VERSION ""

NS_ :

BS_:

BU_: TBox

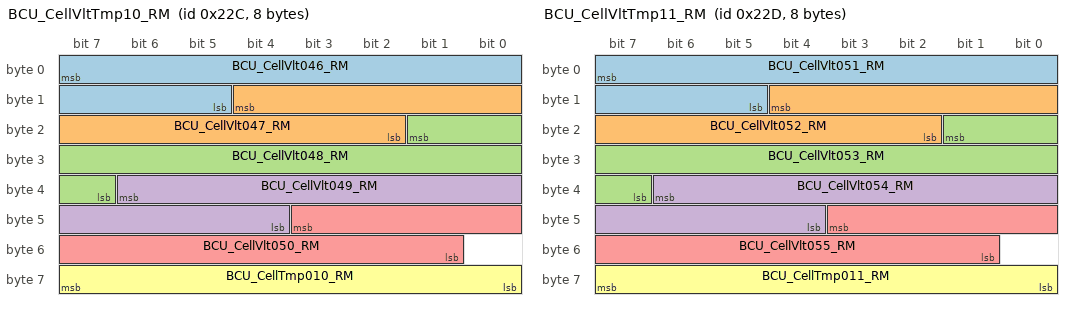
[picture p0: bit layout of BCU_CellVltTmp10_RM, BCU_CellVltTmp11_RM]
BO_ 556 BCU_CellVltTmp10_RM: 8 CGW
 SG_ BCU_CellVlt046_RM : 7|11@0+ (0.01,0) [0|18] "V" TBox
 SG_ BCU_CellVlt047_RM : 12|11@0+ (0.01,0) [0|18] "V" TBox
 SG_ BCU_CellVlt048_RM : 17|11@0+ (0.01,0) [0|18] "V" TBox
 SG_ BCU_CellVlt049_RM : 38|11@0+ (0.01,0) [0|18] "V" TBox
 SG_ BCU_CellVlt050_RM : 43|11@0+ (0.01,0) [0|18] "V" TBox
 SG_ BCU_CellTmp010_RM : 63|8@0+ (1,-40) [-40|120] "℃" TBox

BO_ 557 BCU_CellVltTmp11_RM: 8 CGW
 SG_ BCU_CellVlt051_RM : 7|11@0+ (0.01,0) [0|18] "V" TBox
 SG_ BCU_CellVlt052_RM : 12|11@0+ (0.01,0) [0|18] "V" TBox
 SG_ BCU_CellVlt053_RM : 17|11@0+ (0.01,0) [0|18] "V" TBox
 SG_ BCU_CellVlt054_RM : 38|11@0+ (0.01,0) [0|18] "V" TBox
 SG_ BCU_CellVlt055_RM : 43|11@0+ (0.01,0) [0|18] "V" TBox
 SG_ BCU_CellTmp011_RM : 63|8@0+ (1,-40) [-40|120] "℃" TBox

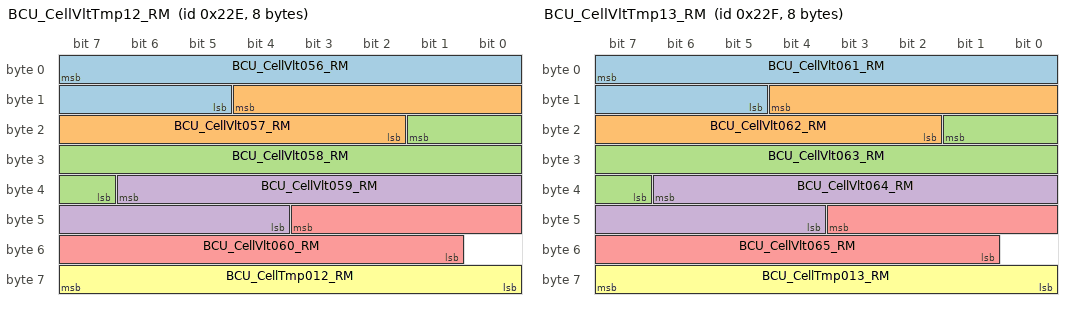
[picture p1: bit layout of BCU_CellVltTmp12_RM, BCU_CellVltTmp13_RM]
BO_ 558 BCU_CellVltTmp12_RM: 8 CGW
 SG_ BCU_CellVlt056_RM : 7|11@0+ (0.01,0) [0|18] "V" TBox
 SG_ BCU_CellVlt057_RM : 12|11@0+ (0.01,0) [0|18] "V" TBox
 SG_ BCU_CellVlt058_RM : 17|11@0+ (0.01,0) [0|18] "V" TBox
 SG_ BCU_CellVlt059_RM : 38|11@0+ (0.01,0) [0|18] "V" TBox
 SG_ BCU_CellVlt060_RM : 43|11@0+ (0.01,0) [0|18] "V" TBox
 SG_ BCU_CellTmp012_RM : 63|8@0+ (1,-40) [-40|120] "℃" TBox

BO_ 559 BCU_CellVltTmp13_RM: 8 CGW
 SG_ BCU_CellVlt061_RM : 7|11@0+ (0.01,0) [0|18] "V" TBox
 SG_ BCU_CellVlt062_RM : 12|11@0+ (0.01,0) [0|18] "V" TBox
 SG_ BCU_CellVlt063_RM : 17|11@0+ (0.01,0) [0|18] "V" TBox
 SG_ BCU_CellVlt064_RM : 38|11@0+ (0.01,0) [0|18] "V" TBox
 SG_ BCU_CellVlt065_RM : 43|11@0+ (0.01,0) [0|18] "V" TBox
 SG_ BCU_CellTmp013_RM : 63|8@0+ (1,-40) [-40|120] "℃" TBox

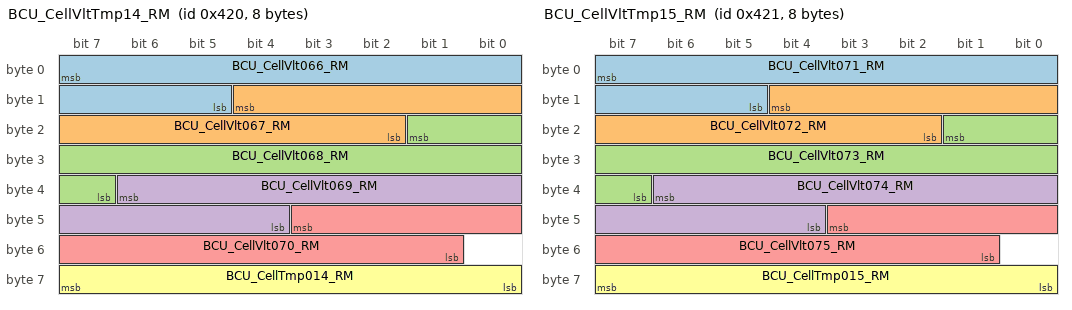
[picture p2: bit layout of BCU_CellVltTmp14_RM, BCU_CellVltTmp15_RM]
BO_ 1056 BCU_CellVltTmp14_RM: 8 CGW
 SG_ BCU_CellVlt066_RM : 7|11@0+ (0.01,0) [0|18] "V" TBox
 SG_ BCU_CellVlt067_RM : 12|11@0+ (0.01,0) [0|18] "V" TBox
 SG_ BCU_CellVlt068_RM : 17|11@0+ (0.01,0) [0|18] "V" TBox
 SG_ BCU_CellVlt069_RM : 38|11@0+ (0.01,0) [0|18] "V" TBox
 SG_ BCU_CellVlt070_RM : 43|11@0+ (0.01,0) [0|18] "V" TBox
 SG_ BCU_CellTmp014_RM : 63|8@0+ (1,-40) [-40|120] "℃" TBox

BO_ 1057 BCU_CellVltTmp15_RM: 8 CGW
 SG_ BCU_CellVlt071_RM : 7|11@0+ (0.01,0) [0|18] "V" TBox
 SG_ BCU_CellVlt072_RM : 12|11@0+ (0.01,0) [0|18] "V" TBox
 SG_ BCU_CellVlt073_RM : 17|11@0+ (0.01,0) [0|18] "V" TBox
 SG_ BCU_CellVlt074_RM : 38|11@0+ (0.01,0) [0|18] "V" TBox
 SG_ BCU_CellVlt075_RM : 43|11@0+ (0.01,0) [0|18] "V" TBox
 SG_ BCU_CellTmp015_RM : 63|8@0+ (1,-40) [-40|120] "℃" TBox

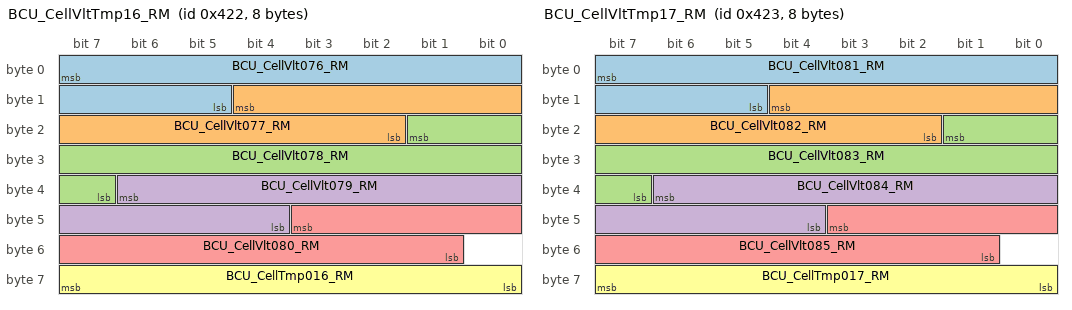
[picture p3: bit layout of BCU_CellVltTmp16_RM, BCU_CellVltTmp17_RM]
BO_ 1058 BCU_CellVltTmp16_RM: 8 CGW
 SG_ BCU_CellVlt076_RM : 7|11@0+ (0.01,0) [0|18] "V" TBox
 SG_ BCU_CellVlt077_RM : 12|11@0+ (0.01,0) [0|18] "V" TBox
 SG_ BCU_CellVlt078_RM : 17|11@0+ (0.01,0) [0|18] "V" TBox
 SG_ BCU_CellVlt079_RM : 38|11@0+ (0.01,0) [0|18] "V" TBox
 SG_ BCU_CellVlt080_RM : 43|11@0+ (0.01,0) [0|18] "V" TBox
 SG_ BCU_CellTmp016_RM : 63|8@0+ (1,-40) [-40|120] "℃" TBox

BO_ 1059 BCU_CellVltTmp17_RM: 8 CGW
 SG_ BCU_CellVlt081_RM : 7|11@0+ (0.01,0) [0|18] "V" TBox
 SG_ BCU_CellVlt082_RM : 12|11@0+ (0.01,0) [0|18] "V" TBox
 SG_ BCU_CellVlt083_RM : 17|11@0+ (0.01,0) [0|18] "V" TBox
 SG_ BCU_CellVlt084_RM : 38|11@0+ (0.01,0) [0|18] "V" TBox
 SG_ BCU_CellVlt085_RM : 43|11@0+ (0.01,0) [0|18] "V" TBox
 SG_ BCU_CellTmp017_RM : 63|8@0+ (1,-40) [-40|120] "℃" TBox

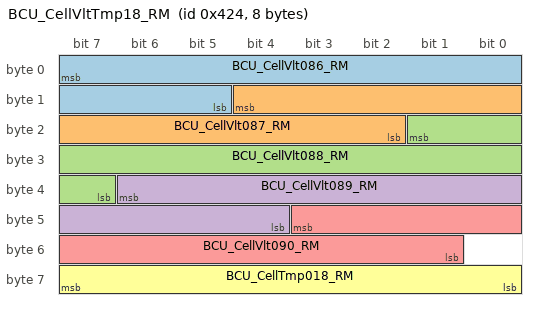
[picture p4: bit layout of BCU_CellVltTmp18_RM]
BO_ 1060 BCU_CellVltTmp18_RM: 8 CGW
 SG_ BCU_CellVlt086_RM : 7|11@0+ (0.01,0) [0|18] "V" TBox
 SG_ BCU_CellVlt087_RM : 12|11@0+ (0.01,0) [0|18] "V" TBox
 SG_ BCU_CellVlt088_RM : 17|11@0+ (0.01,0) [0|18] "V" TBox
 SG_ BCU_CellVlt089_RM : 38|11@0+ (0.01,0) [0|18] "V" TBox
 SG_ BCU_CellVlt090_RM : 43|11@0+ (0.01,0) [0|18] "V" TBox
 SG_ BCU_CellTmp018_RM : 63|8@0+ (1,-40) [-40|120] "℃" TBox

CM_ SG_ 556 BCU_CellVlt046_RM "Cell voltage 046
单体电压046";
CM_ SG_ 556 BCU_CellVlt047_RM "Cell voltage 047
单体电压047";
CM_ SG_ 556 BCU_CellVlt048_RM "Cell voltage 048
单体电压048";
CM_ SG_ 556 BCU_CellVlt049_RM "Cell voltage 049
单体电压049";
CM_ SG_ 556 BCU_CellVlt050_RM "Cell voltage 050
单体电压050";
CM_ SG_ 556 BCU_CellTmp010_RM "Cell temperature 010
单体温度010";
CM_ SG_ 557 BCU_CellVlt051_RM "Cell voltage 051
单体电压051";
CM_ SG_ 557 BCU_CellVlt052_RM "Cell voltage 052
单体电压052";
CM_ SG_ 557 BCU_CellVlt053_RM "Cell voltage 053
单体电压053";
CM_ SG_ 557 BCU_CellVlt054_RM "Cell voltage 054
单体电压054";
CM_ SG_ 557 BCU_CellVlt055_RM "Cell voltage 055
单体电压055";
CM_ SG_ 557 BCU_CellTmp011_RM "Cell temperature 011
单体温度011";
CM_ SG_ 558 BCU_CellVlt056_RM "Cell voltage 056
单体电压056";
CM_ SG_ 558 BCU_CellVlt057_RM "Cell voltage 057
单体电压057";
CM_ SG_ 558 BCU_CellVlt058_RM "Cell voltage 058
单体电压058";
CM_ SG_ 558 BCU_CellVlt059_RM "Cell voltage 059
单体电压059";
CM_ SG_ 558 BCU_CellVlt060_RM "Cell voltage 060
单体电压060";
CM_ SG_ 558 BCU_CellTmp012_RM "Cell temperature 012
单体温度012";
CM_ SG_ 559 BCU_CellVlt061_RM "Cell voltage 061
单体电压061";
CM_ SG_ 559 BCU_CellVlt062_RM "Cell voltage 062
单体电压062";
CM_ SG_ 559 BCU_CellVlt063_RM "Cell voltage 063
单体电压063";
CM_ SG_ 559 BCU_CellVlt064_RM "Cell voltage 064
单体电压064";
CM_ SG_ 559 BCU_CellVlt065_RM "Cell voltage 065
单体电压065";
CM_ SG_ 559 BCU_CellTmp013_RM "Cell temperature 013
单体温度013";
CM_ SG_ 1056 BCU_CellVlt066_RM "Cell voltage 066
单体电压066";
CM_ SG_ 1056 BCU_CellVlt067_RM "Cell voltage 067
单体电压067";
CM_ SG_ 1056 BCU_CellVlt068_RM "Cell voltage 068
单体电压068";
CM_ SG_ 1056 BCU_CellVlt069_RM "Cell voltage 069
单体电压069";
CM_ SG_ 1056 BCU_CellVlt070_RM "Cell voltage 070
单体电压070";
CM_ SG_ 1056 BCU_CellTmp014_RM "Cell temperature 014
单体温度014";
CM_ SG_ 1057 BCU_CellVlt071_RM "Cell voltage 071
单体电压071";
CM_ SG_ 1057 BCU_CellVlt072_RM "Cell voltage 072
单体电压072";
CM_ SG_ 1057 BCU_CellVlt073_RM "Cell voltage 073
单体电压073";
CM_ SG_ 1057 BCU_CellVlt074_RM "Cell voltage 074
单体电压074";
CM_ SG_ 1057 BCU_CellVlt075_RM "Cell voltage 075
单体电压075";
CM_ SG_ 1057 BCU_CellTmp015_RM "Cell temperature 015
单体温度015";
CM_ SG_ 1058 BCU_CellVlt076_RM "Cell voltage 076
单体电压076";
CM_ SG_ 1058 BCU_CellVlt077_RM "Cell voltage 077
单体电压077";
CM_ SG_ 1058 BCU_CellVlt078_RM "Cell voltage 078
单体电压078";
CM_ SG_ 1058 BCU_CellVlt079_RM "Cell voltage 079
单体电压079";
CM_ SG_ 1058 BCU_CellVlt080_RM "Cell voltage 080
单体电压080";
CM_ SG_ 1058 BCU_CellTmp016_RM "Cell temperature 016
单体温度016";
CM_ SG_ 1059 BCU_CellVlt081_RM "Cell voltage 081
单体电压081";
CM_ SG_ 1059 BCU_CellVlt082_RM "Cell voltage 082
单体电压082";
CM_ SG_ 1059 BCU_CellVlt083_RM "Cell voltage 083
单体电压083";
CM_ SG_ 1059 BCU_CellVlt084_RM "Cell voltage 084
单体电压084";
CM_ SG_ 1059 BCU_CellVlt085_RM "Cell voltage 085
单体电压085";
CM_ SG_ 1059 BCU_CellTmp017_RM "Cell temperature 017
单体温度017";
CM_ SG_ 1060 BCU_CellVlt086_RM "Cell voltage 086
单体电压086";
CM_ SG_ 1060 BCU_CellVlt087_RM "Cell voltage 087
单体电压087";
CM_ SG_ 1060 BCU_CellVlt088_RM "Cell voltage 088
单体电压088";
CM_ SG_ 1060 BCU_CellVlt089_RM "Cell voltage 089
单体电压089";
CM_ SG_ 1060 BCU_CellVlt090_RM "Cell voltage 090
单体电压090";
CM_ SG_ 1060 BCU_CellTmp018_RM "Cell temperature 018
单体温度018";

BA_DEF_ BO_  "NmMessage" ENUM "No","Yes";
BA_DEF_ BO_  "GenMsgSendType" ENUM  "Cycle","CA","CE","Event","NotUsed","NotUsed","NotUsed","IfActive","NoMsgSendType","NotUsed";
BA_DEF_ BO_  "GenMsgCycleTime" INT 0 0;
BA_DEF_ SG_  "GenSigSendType" ENUM  "Cycle","OnChange","OnWrite","IfActive","OnChangeWithRepetition","OnWriteWithRepetition","IfActiveWithRepetition";
BA_DEF_ SG_  "GenSigStartValue" INT 0 0;
BA_DEF_ BO_  "GenMsgCycleTimeFast" INT 0 0;
BA_DEF_ BO_  "GenMsgNrOfRepetition" INT 0 0;
BA_DEF_ BO_  "GenMsgDelayTime" INT 0 0;
BA_DEF_ BO_  "VFrameFormat" ENUM  "StandardCAN","ExtendedCAN","reserved","reserved","reserved","reserved","reserved","reserved","reserved","reserved","reserved","reserved","reserved","reserved","StandardCAN_FD","ExtendedCAN_FD";
BA_DEF_ BO_  "GenMsgCycleTimeActive" INT 0 500;
BA_DEF_ BO_  "GenMsgStartDelayTime" INT 0 500;

BA_DEF_DEF_  "NmMessage" "No";
BA_DEF_DEF_  "GenMsgSendType" "Cycle";
BA_DEF_DEF_  "GenMsgCycleTime" 0;
BA_DEF_DEF_  "GenSigSendType" "Cycle";
BA_DEF_DEF_  "GenSigStartValue" 0;
BA_DEF_DEF_  "GenMsgCycleTimeFast" 0;
BA_DEF_DEF_  "GenMsgNrOfRepetition" 0;
BA_DEF_DEF_  "GenMsgDelayTime" 0;
BA_DEF_DEF_  "VFrameFormat" "StandardCAN";
BA_DEF_DEF_  "GenMsgCycleTimeActive" 100;
BA_DEF_DEF_  "GenMsgStartDelayTime" 200;
BA_ "GenMsgCycleTime" BO_ 556 1000;
BA_ "GenSigStartValue" SG_ 556 BCU_CellTmp010_RM 40;
BA_ "GenMsgCycleTime" BO_ 557 1000;
BA_ "GenSigStartValue" SG_ 557 BCU_CellTmp011_RM 40;
BA_ "GenMsgCycleTime" BO_ 558 1000;
BA_ "GenSigStartValue" SG_ 558 BCU_CellTmp012_RM 40;
BA_ "GenMsgCycleTime" BO_ 559 1000;
BA_ "GenSigStartValue" SG_ 559 BCU_CellTmp013_RM 40;
BA_ "GenMsgCycleTime" BO_ 1056 1000;
BA_ "GenSigStartValue" SG_ 1056 BCU_CellTmp014_RM 40;
BA_ "GenMsgCycleTime" BO_ 1057 1000;
BA_ "GenSigStartValue" SG_ 1057 BCU_CellTmp015_RM 40;
BA_ "GenMsgCycleTime" BO_ 1058 1000;
BA_ "GenSigStartValue" SG_ 1058 BCU_CellTmp016_RM 40;
BA_ "GenMsgCycleTime" BO_ 1059 1000;
BA_ "GenSigStartValue" SG_ 1059 BCU_CellTmp017_RM 40;
BA_ "GenMsgCycleTime" BO_ 1060 1000;
BA_ "GenSigStartValue" SG_ 1060 BCU_CellTmp018_RM 40;
VAL_ 556 BCU_CellVlt046_RM 2047 "Invalid" 2046 "Invalid" 2045 "Invalid" 2044 "Invalid" 2043 "Invalid" 2042 "Invalid" 2041 "Invalid" 2040 "Invalid" 2039 "Invalid" 2038 "Invalid" 2037 "Invalid" 2036 "Invalid" 2035 "Invalid" 2034 "Invalid" 2033 "Invalid" 2032 "Invalid" 2031 "Invalid" 2030 "Invalid" 2029 "Invalid" 2028 "Invalid" 2027 "Invalid" 2026 "Invalid" 2025 "Invalid" 2024 "Invalid" 2023 "Invalid" 2022 "Invalid" 2021 "Invalid" 2020 "Invalid" 2019 "Invalid" 2018 "Invalid" 2017 "Invalid" 2016 "Invalid" 2015 "Invalid" 2014 "Invalid" 2013 "Invalid" 2012 "Invalid" 2011 "Invalid" 2010 "Invalid" 2009 "Invalid" 2008 "Invalid" 2007 "Invalid" 2006 "Invalid" 2005 "Invalid" 2004 "Invalid" 2003 "Invalid" 2002 "Invalid" 2001 "Invalid" 2000 "Invalid" 1999 "Invalid" 1998 "Invalid" 1997 "Invalid" 1996 "Invalid" 1995 "Invalid" 1994 "Invalid" 1993 "Invalid" 1992 "Invalid" 1991 "Invalid" 1990 "Invalid" 1989 "Invalid" 1988 "Invalid" 1987 "Invalid" 1986 "Invalid" 1985 "Invalid" 1984 "Invalid" 1983 "Invalid" 1982 "Invalid" 1981 "Invalid" 1980 "Invalid" 1979 "Invalid" 1978 "Invalid" 1977 "Invalid" 1976 "Invalid" 1975 "Invalid" 1974 "Invalid" 1973 "Invalid" 1972 "Invalid" 1971 "Invalid" 1970 "Invalid" 1969 "Invalid" 1968 "Invalid" 1967 "Invalid" 1966 "Invalid" 1965 "Invalid" 1964 "Invalid" 1963 "Invalid" 1962 "Invalid" 1961 "Invalid" 1960 "Invalid" 1959 "Invalid" 1958 "Invalid" 1957 "Invalid" 1956 "Invalid" 1955 "Invalid" 1954 "Invalid" 1953 "Invalid" 1952 "Invalid" 1951 "Invalid" 1950 "Invalid" 1949 "Invalid" 1948 "Invalid" 1947 "Invalid" 1946 "Invalid" 1945 "Invalid" 1944 "Invalid" 1943 "Invalid" 1942 "Invalid" 1941 "Invalid" 1940 "Invalid" 1939 "Invalid" 1938 "Invalid" 1937 "Invalid" 1936 "Invalid" 1935 "Invalid" 1934 "Invalid" 1933 "Invalid" 1932 "Invalid" 1931 "Invalid" 1930 "Invalid" 1929 "Invalid" 1928 "Invalid" 1927 "Invalid" 1926 "Invalid" 1925 "Invalid" 1924 "Invalid" 1923 "Invalid" 1922 "Invalid" 1921 "Invalid" 1920 "Invalid" 1919 "Invalid" 1918 "Invalid" 1917 "Invalid" 1916 "Invalid" 1915 "Invalid" 1914 "Invalid" 1913 "Invalid" 1912 "Invalid" 1911 "Invalid" 1910 "Invalid" 1909 "Invalid" 1908 "Invalid" 1907 "Invalid" 1906 "Invalid" 1905 "Invalid" 1904 "Invalid" 1903 "Invalid" 1902 "Invalid" 1901 "Invalid" 1900 "Invalid" 1899 "Invalid" 1898 "Invalid" 1897 "Invalid" 1896 "Invalid" 1895 "Invalid" 1894 "Invalid" 1893 "Invalid" 1892 "Invalid" 1891 "Invalid" 1890 "Invalid" 1889 "Invalid" 1888 "Invalid" 1887 "Invalid" 1886 "Invalid" 1885 "Invalid" 1884 "Invalid" 1883 "Invalid" 1882 "Invalid" 1881 "Invalid" 1880 "Invalid" 1879 "Invalid" 1878 "Invalid" 1877 "Invalid" 1876 "Invalid" 1875 "Invalid" 1874 "Invalid" 1873 "Invalid" 1872 "Invalid" 1871 "Invalid" 1870 "Invalid" 1869 "Invalid" 1868 "Invalid" 1867 "Invalid" 1866 "Invalid" 1865 "Invalid" 1864 "Invalid" 1863 "Invalid" 1862 "Invalid" 1861 "Invalid" 1860 "Invalid" 1859 "Invalid" 1858 "Invalid" 1857 "Invalid" 1856 "Invalid" 1855 "Invalid" 1854 "Invalid" 1853 "Invalid" 1852 "Invalid" 1851 "Invalid" 1850 "Invalid" 1849 "Invalid" 1848 "Invalid" 1847 "Invalid" 1846 "Invalid" 1845 "Invalid" 1844 "Invalid" 1843 "Invalid" 1842 "Invalid" 1841 "Invalid" 1840 "Invalid" 1839 "Invalid" 1838 "Invalid" 1837 "Invalid" 1836 "Invalid" 1835 "Invalid" 1834 "Invalid" 1833 "Invalid" 1832 "Invalid" 1831 "Invalid" 1830 "Invalid" 1829 "Invalid" 1828 "Invalid" 1827 "Invalid" 1826 "Invalid" 1825 "Invalid" 1824 "Invalid" 1823 "Invalid" 1822 "Invalid" 1821 "Invalid" 1820 "Invalid" 1819 "Invalid" 1818 "Invalid" 1817 "Invalid" 1816 "Invalid" 1815 "Invalid" 1814 "Invalid" 1813 "Invalid" 1812 "Invalid" 1811 "Invalid" 1810 "Invalid" 1809 "Invalid" 1808 "Invalid" 1807 "Invalid" 1806 "Invalid" 1805 "Invalid" 1804 "Invalid" 1803 "Invalid" 1802 "Invalid" 1801 "Invalid" ;
VAL_ 556 BCU_CellVlt047_RM 2047 "Invalid" 2046 "Invalid" 2045 "Invalid" 2044 "Invalid" 2043 "Invalid" 2042 "Invalid" 2041 "Invalid" 2040 "Invalid" 2039 "Invalid" 2038 "Invalid" 2037 "Invalid" 2036 "Invalid" 2035 "Invalid" 2034 "Invalid" 2033 "Invalid" 2032 "Invalid" 2031 "Invalid" 2030 "Invalid" 2029 "Invalid" 2028 "Invalid" 2027 "Invalid" 2026 "Invalid" 2025 "Invalid" 2024 "Invalid" 2023 "Invalid" 2022 "Invalid" 2021 "Invalid" 2020 "Invalid" 2019 "Invalid" 2018 "Invalid" 2017 "Invalid" 2016 "Invalid" 2015 "Invalid" 2014 "Invalid" 2013 "Invalid" 2012 "Invalid" 2011 "Invalid" 2010 "Invalid" 2009 "Invalid" 2008 "Invalid" 2007 "Invalid" 2006 "Invalid" 2005 "Invalid" 2004 "Invalid" 2003 "Invalid" 2002 "Invalid" 2001 "Invalid" 2000 "Invalid" 1999 "Invalid" 1998 "Invalid" 1997 "Invalid" 1996 "Invalid" 1995 "Invalid" 1994 "Invalid" 1993 "Invalid" 1992 "Invalid" 1991 "Invalid" 1990 "Invalid" 1989 "Invalid" 1988 "Invalid" 1987 "Invalid" 1986 "Invalid" 1985 "Invalid" 1984 "Invalid" 1983 "Invalid" 1982 "Invalid" 1981 "Invalid" 1980 "Invalid" 1979 "Invalid" 1978 "Invalid" 1977 "Invalid" 1976 "Invalid" 1975 "Invalid" 1974 "Invalid" 1973 "Invalid" 1972 "Invalid" 1971 "Invalid" 1970 "Invalid" 1969 "Invalid" 1968 "Invalid" 1967 "Invalid" 1966 "Invalid" 1965 "Invalid" 1964 "Invalid" 1963 "Invalid" 1962 "Invalid" 1961 "Invalid" 1960 "Invalid" 1959 "Invalid" 1958 "Invalid" 1957 "Invalid" 1956 "Invalid" 1955 "Invalid" 1954 "Invalid" 1953 "Invalid" 1952 "Invalid" 1951 "Invalid" 1950 "Invalid" 1949 "Invalid" 1948 "Invalid" 1947 "Invalid" 1946 "Invalid" 1945 "Invalid" 1944 "Invalid" 1943 "Invalid" 1942 "Invalid" 1941 "Invalid" 1940 "Invalid" 1939 "Invalid" 1938 "Invalid" 1937 "Invalid" 1936 "Invalid" 1935 "Invalid" 1934 "Invalid" 1933 "Invalid" 1932 "Invalid" 1931 "Invalid" 1930 "Invalid" 1929 "Invalid" 1928 "Invalid" 1927 "Invalid" 1926 "Invalid" 1925 "Invalid" 1924 "Invalid" 1923 "Invalid" 1922 "Invalid" 1921 "Invalid" 1920 "Invalid" 1919 "Invalid" 1918 "Invalid" 1917 "Invalid" 1916 "Invalid" 1915 "Invalid" 1914 "Invalid" 1913 "Invalid" 1912 "Invalid" 1911 "Invalid" 1910 "Invalid" 1909 "Invalid" 1908 "Invalid" 1907 "Invalid" 1906 "Invalid" 1905 "Invalid" 1904 "Invalid" 1903 "Invalid" 1902 "Invalid" 1901 "Invalid" 1900 "Invalid" 1899 "Invalid" 1898 "Invalid" 1897 "Invalid" 1896 "Invalid" 1895 "Invalid" 1894 "Invalid" 1893 "Invalid" 1892 "Invalid" 1891 "Invalid" 1890 "Invalid" 1889 "Invalid" 1888 "Invalid" 1887 "Invalid" 1886 "Invalid" 1885 "Invalid" 1884 "Invalid" 1883 "Invalid" 1882 "Invalid" 1881 "Invalid" 1880 "Invalid" 1879 "Invalid" 1878 "Invalid" 1877 "Invalid" 1876 "Invalid" 1875 "Invalid" 1874 "Invalid" 1873 "Invalid" 1872 "Invalid" 1871 "Invalid" 1870 "Invalid" 1869 "Invalid" 1868 "Invalid" 1867 "Invalid" 1866 "Invalid" 1865 "Invalid" 1864 "Invalid" 1863 "Invalid" 1862 "Invalid" 1861 "Invalid" 1860 "Invalid" 1859 "Invalid" 1858 "Invalid" 1857 "Invalid" 1856 "Invalid" 1855 "Invalid" 1854 "Invalid" 1853 "Invalid" 1852 "Invalid" 1851 "Invalid" 1850 "Invalid" 1849 "Invalid" 1848 "Invalid" 1847 "Invalid" 1846 "Invalid" 1845 "Invalid" 1844 "Invalid" 1843 "Invalid" 1842 "Invalid" 1841 "Invalid" 1840 "Invalid" 1839 "Invalid" 1838 "Invalid" 1837 "Invalid" 1836 "Invalid" 1835 "Invalid" 1834 "Invalid" 1833 "Invalid" 1832 "Invalid" 1831 "Invalid" 1830 "Invalid" 1829 "Invalid" 1828 "Invalid" 1827 "Invalid" 1826 "Invalid" 1825 "Invalid" 1824 "Invalid" 1823 "Invalid" 1822 "Invalid" 1821 "Invalid" 1820 "Invalid" 1819 "Invalid" 1818 "Invalid" 1817 "Invalid" 1816 "Invalid" 1815 "Invalid" 1814 "Invalid" 1813 "Invalid" 1812 "Invalid" 1811 "Invalid" 1810 "Invalid" 1809 "Invalid" 1808 "Invalid" 1807 "Invalid" 1806 "Invalid" 1805 "Invalid" 1804 "Invalid" 1803 "Invalid" 1802 "Invalid" 1801 "Invalid" ;
VAL_ 556 BCU_CellVlt048_RM 2047 "Invalid" 2046 "Invalid" 2045 "Invalid" 2044 "Invalid" 2043 "Invalid" 2042 "Invalid" 2041 "Invalid" 2040 "Invalid" 2039 "Invalid" 2038 "Invalid" 2037 "Invalid" 2036 "Invalid" 2035 "Invalid" 2034 "Invalid" 2033 "Invalid" 2032 "Invalid" 2031 "Invalid" 2030 "Invalid" 2029 "Invalid" 2028 "Invalid" 2027 "Invalid" 2026 "Invalid" 2025 "Invalid" 2024 "Invalid" 2023 "Invalid" 2022 "Invalid" 2021 "Invalid" 2020 "Invalid" 2019 "Invalid" 2018 "Invalid" 2017 "Invalid" 2016 "Invalid" 2015 "Invalid" 2014 "Invalid" 2013 "Invalid" 2012 "Invalid" 2011 "Invalid" 2010 "Invalid" 2009 "Invalid" 2008 "Invalid" 2007 "Invalid" 2006 "Invalid" 2005 "Invalid" 2004 "Invalid" 2003 "Invalid" 2002 "Invalid" 2001 "Invalid" 2000 "Invalid" 1999 "Invalid" 1998 "Invalid" 1997 "Invalid" 1996 "Invalid" 1995 "Invalid" 1994 "Invalid" 1993 "Invalid" 1992 "Invalid" 1991 "Invalid" 1990 "Invalid" 1989 "Invalid" 1988 "Invalid" 1987 "Invalid" 1986 "Invalid" 1985 "Invalid" 1984 "Invalid" 1983 "Invalid" 1982 "Invalid" 1981 "Invalid" 1980 "Invalid" 1979 "Invalid" 1978 "Invalid" 1977 "Invalid" 1976 "Invalid" 1975 "Invalid" 1974 "Invalid" 1973 "Invalid" 1972 "Invalid" 1971 "Invalid" 1970 "Invalid" 1969 "Invalid" 1968 "Invalid" 1967 "Invalid" 1966 "Invalid" 1965 "Invalid" 1964 "Invalid" 1963 "Invalid" 1962 "Invalid" 1961 "Invalid" 1960 "Invalid" 1959 "Invalid" 1958 "Invalid" 1957 "Invalid" 1956 "Invalid" 1955 "Invalid" 1954 "Invalid" 1953 "Invalid" 1952 "Invalid" 1951 "Invalid" 1950 "Invalid" 1949 "Invalid" 1948 "Invalid" 1947 "Invalid" 1946 "Invalid" 1945 "Invalid" 1944 "Invalid" 1943 "Invalid" 1942 "Invalid" 1941 "Invalid" 1940 "Invalid" 1939 "Invalid" 1938 "Invalid" 1937 "Invalid" 1936 "Invalid" 1935 "Invalid" 1934 "Invalid" 1933 "Invalid" 1932 "Invalid" 1931 "Invalid" 1930 "Invalid" 1929 "Invalid" 1928 "Invalid" 1927 "Invalid" 1926 "Invalid" 1925 "Invalid" 1924 "Invalid" 1923 "Invalid" 1922 "Invalid" 1921 "Invalid" 1920 "Invalid" 1919 "Invalid" 1918 "Invalid" 1917 "Invalid" 1916 "Invalid" 1915 "Invalid" 1914 "Invalid" 1913 "Invalid" 1912 "Invalid" 1911 "Invalid" 1910 "Invalid" 1909 "Invalid" 1908 "Invalid" 1907 "Invalid" 1906 "Invalid" 1905 "Invalid" 1904 "Invalid" 1903 "Invalid" 1902 "Invalid" 1901 "Invalid" 1900 "Invalid" 1899 "Invalid" 1898 "Invalid" 1897 "Invalid" 1896 "Invalid" 1895 "Invalid" 1894 "Invalid" 1893 "Invalid" 1892 "Invalid" 1891 "Invalid" 1890 "Invalid" 1889 "Invalid" 1888 "Invalid" 1887 "Invalid" 1886 "Invalid" 1885 "Invalid" 1884 "Invalid" 1883 "Invalid" 1882 "Invalid" 1881 "Invalid" 1880 "Invalid" 1879 "Invalid" 1878 "Invalid" 1877 "Invalid" 1876 "Invalid" 1875 "Invalid" 1874 "Invalid" 1873 "Invalid" 1872 "Invalid" 1871 "Invalid" 1870 "Invalid" 1869 "Invalid" 1868 "Invalid" 1867 "Invalid" 1866 "Invalid" 1865 "Invalid" 1864 "Invalid" 1863 "Invalid" 1862 "Invalid" 1861 "Invalid" 1860 "Invalid" 1859 "Invalid" 1858 "Invalid" 1857 "Invalid" 1856 "Invalid" 1855 "Invalid" 1854 "Invalid" 1853 "Invalid" 1852 "Invalid" 1851 "Invalid" 1850 "Invalid" 1849 "Invalid" 1848 "Invalid" 1847 "Invalid" 1846 "Invalid" 1845 "Invalid" 1844 "Invalid" 1843 "Invalid" 1842 "Invalid" 1841 "Invalid" 1840 "Invalid" 1839 "Invalid" 1838 "Invalid" 1837 "Invalid" 1836 "Invalid" 1835 "Invalid" 1834 "Invalid" 1833 "Invalid" 1832 "Invalid" 1831 "Invalid" 1830 "Invalid" 1829 "Invalid" 1828 "Invalid" 1827 "Invalid" 1826 "Invalid" 1825 "Invalid" 1824 "Invalid" 1823 "Invalid" 1822 "Invalid" 1821 "Invalid" 1820 "Invalid" 1819 "Invalid" 1818 "Invalid" 1817 "Invalid" 1816 "Invalid" 1815 "Invalid" 1814 "Invalid" 1813 "Invalid" 1812 "Invalid" 1811 "Invalid" 1810 "Invalid" 1809 "Invalid" 1808 "Invalid" 1807 "Invalid" 1806 "Invalid" 1805 "Invalid" 1804 "Invalid" 1803 "Invalid" 1802 "Invalid" 1801 "Invalid" ;
VAL_ 556 BCU_CellVlt049_RM 2047 "Invalid" 2046 "Invalid" 2045 "Invalid" 2044 "Invalid" 2043 "Invalid" 2042 "Invalid" 2041 "Invalid" 2040 "Invalid" 2039 "Invalid" 2038 "Invalid" 2037 "Invalid" 2036 "Invalid" 2035 "Invalid" 2034 "Invalid" 2033 "Invalid" 2032 "Invalid" 2031 "Invalid" 2030 "Invalid" 2029 "Invalid" 2028 "Invalid" 2027 "Invalid" 2026 "Invalid" 2025 "Invalid" 2024 "Invalid" 2023 "Invalid" 2022 "Invalid" 2021 "Invalid" 2020 "Invalid" 2019 "Invalid" 2018 "Invalid" 2017 "Invalid" 2016 "Invalid" 2015 "Invalid" 2014 "Invalid" 2013 "Invalid" 2012 "Invalid" 2011 "Invalid" 2010 "Invalid" 2009 "Invalid" 2008 "Invalid" 2007 "Invalid" 2006 "Invalid" 2005 "Invalid" 2004 "Invalid" 2003 "Invalid" 2002 "Invalid" 2001 "Invalid" 2000 "Invalid" 1999 "Invalid" 1998 "Invalid" 1997 "Invalid" 1996 "Invalid" 1995 "Invalid" 1994 "Invalid" 1993 "Invalid" 1992 "Invalid" 1991 "Invalid" 1990 "Invalid" 1989 "Invalid" 1988 "Invalid" 1987 "Invalid" 1986 "Invalid" 1985 "Invalid" 1984 "Invalid" 1983 "Invalid" 1982 "Invalid" 1981 "Invalid" 1980 "Invalid" 1979 "Invalid" 1978 "Invalid" 1977 "Invalid" 1976 "Invalid" 1975 "Invalid" 1974 "Invalid" 1973 "Invalid" 1972 "Invalid" 1971 "Invalid" 1970 "Invalid" 1969 "Invalid" 1968 "Invalid" 1967 "Invalid" 1966 "Invalid" 1965 "Invalid" 1964 "Invalid" 1963 "Invalid" 1962 "Invalid" 1961 "Invalid" 1960 "Invalid" 1959 "Invalid" 1958 "Invalid" 1957 "Invalid" 1956 "Invalid" 1955 "Invalid" 1954 "Invalid" 1953 "Invalid" 1952 "Invalid" 1951 "Invalid" 1950 "Invalid" 1949 "Invalid" 1948 "Invalid" 1947 "Invalid" 1946 "Invalid" 1945 "Invalid" 1944 "Invalid" 1943 "Invalid" 1942 "Invalid" 1941 "Invalid" 1940 "Invalid" 1939 "Invalid" 1938 "Invalid" 1937 "Invalid" 1936 "Invalid" 1935 "Invalid" 1934 "Invalid" 1933 "Invalid" 1932 "Invalid" 1931 "Invalid" 1930 "Invalid" 1929 "Invalid" 1928 "Invalid" 1927 "Invalid" 1926 "Invalid" 1925 "Invalid" 1924 "Invalid" 1923 "Invalid" 1922 "Invalid" 1921 "Invalid" 1920 "Invalid" 1919 "Invalid" 1918 "Invalid" 1917 "Invalid" 1916 "Invalid" 1915 "Invalid" 1914 "Invalid" 1913 "Invalid" 1912 "Invalid" 1911 "Invalid" 1910 "Invalid" 1909 "Invalid" 1908 "Invalid" 1907 "Invalid" 1906 "Invalid" 1905 "Invalid" 1904 "Invalid" 1903 "Invalid" 1902 "Invalid" 1901 "Invalid" 1900 "Invalid" 1899 "Invalid" 1898 "Invalid" 1897 "Invalid" 1896 "Invalid" 1895 "Invalid" 1894 "Invalid" 1893 "Invalid" 1892 "Invalid" 1891 "Invalid" 1890 "Invalid" 1889 "Invalid" 1888 "Invalid" 1887 "Invalid" 1886 "Invalid" 1885 "Invalid" 1884 "Invalid" 1883 "Invalid" 1882 "Invalid" 1881 "Invalid" 1880 "Invalid" 1879 "Invalid" 1878 "Invalid" 1877 "Invalid" 1876 "Invalid" 1875 "Invalid" 1874 "Invalid" 1873 "Invalid" 1872 "Invalid" 1871 "Invalid" 1870 "Invalid" 1869 "Invalid" 1868 "Invalid" 1867 "Invalid" 1866 "Invalid" 1865 "Invalid" 1864 "Invalid" 1863 "Invalid" 1862 "Invalid" 1861 "Invalid" 1860 "Invalid" 1859 "Invalid" 1858 "Invalid" 1857 "Invalid" 1856 "Invalid" 1855 "Invalid" 1854 "Invalid" 1853 "Invalid" 1852 "Invalid" 1851 "Invalid" 1850 "Invalid" 1849 "Invalid" 1848 "Invalid" 1847 "Invalid" 1846 "Invalid" 1845 "Invalid" 1844 "Invalid" 1843 "Invalid" 1842 "Invalid" 1841 "Invalid" 1840 "Invalid" 1839 "Invalid" 1838 "Invalid" 1837 "Invalid" 1836 "Invalid" 1835 "Invalid" 1834 "Invalid" 1833 "Invalid" 1832 "Invalid" 1831 "Invalid" 1830 "Invalid" 1829 "Invalid" 1828 "Invalid" 1827 "Invalid" 1826 "Invalid" 1825 "Invalid" 1824 "Invalid" 1823 "Invalid" 1822 "Invalid" 1821 "Invalid" 1820 "Invalid" 1819 "Invalid" 1818 "Invalid" 1817 "Invalid" 1816 "Invalid" 1815 "Invalid" 1814 "Invalid" 1813 "Invalid" 1812 "Invalid" 1811 "Invalid" 1810 "Invalid" 1809 "Invalid" 1808 "Invalid" 1807 "Invalid" 1806 "Invalid" 1805 "Invalid" 1804 "Invalid" 1803 "Invalid" 1802 "Invalid" 1801 "Invalid" ;
VAL_ 556 BCU_CellVlt050_RM 2047 "Invalid" 2046 "Invalid" 2045 "Invalid" 2044 "Invalid" 2043 "Invalid" 2042 "Invalid" 2041 "Invalid" 2040 "Invalid" 2039 "Invalid" 2038 "Invalid" 2037 "Invalid" 2036 "Invalid" 2035 "Invalid" 2034 "Invalid" 2033 "Invalid" 2032 "Invalid" 2031 "Invalid" 2030 "Invalid" 2029 "Invalid" 2028 "Invalid" 2027 "Invalid" 2026 "Invalid" 2025 "Invalid" 2024 "Invalid" 2023 "Invalid" 2022 "Invalid" 2021 "Invalid" 2020 "Invalid" 2019 "Invalid" 2018 "Invalid" 2017 "Invalid" 2016 "Invalid" 2015 "Invalid" 2014 "Invalid" 2013 "Invalid" 2012 "Invalid" 2011 "Invalid" 2010 "Invalid" 2009 "Invalid" 2008 "Invalid" 2007 "Invalid" 2006 "Invalid" 2005 "Invalid" 2004 "Invalid" 2003 "Invalid" 2002 "Invalid" 2001 "Invalid" 2000 "Invalid" 1999 "Invalid" 1998 "Invalid" 1997 "Invalid" 1996 "Invalid" 1995 "Invalid" 1994 "Invalid" 1993 "Invalid" 1992 "Invalid" 1991 "Invalid" 1990 "Invalid" 1989 "Invalid" 1988 "Invalid" 1987 "Invalid" 1986 "Invalid" 1985 "Invalid" 1984 "Invalid" 1983 "Invalid" 1982 "Invalid" 1981 "Invalid" 1980 "Invalid" 1979 "Invalid" 1978 "Invalid" 1977 "Invalid" 1976 "Invalid" 1975 "Invalid" 1974 "Invalid" 1973 "Invalid" 1972 "Invalid" 1971 "Invalid" 1970 "Invalid" 1969 "Invalid" 1968 "Invalid" 1967 "Invalid" 1966 "Invalid" 1965 "Invalid" 1964 "Invalid" 1963 "Invalid" 1962 "Invalid" 1961 "Invalid" 1960 "Invalid" 1959 "Invalid" 1958 "Invalid" 1957 "Invalid" 1956 "Invalid" 1955 "Invalid" 1954 "Invalid" 1953 "Invalid" 1952 "Invalid" 1951 "Invalid" 1950 "Invalid" 1949 "Invalid" 1948 "Invalid" 1947 "Invalid" 1946 "Invalid" 1945 "Invalid" 1944 "Invalid" 1943 "Invalid" 1942 "Invalid" 1941 "Invalid" 1940 "Invalid" 1939 "Invalid" 1938 "Invalid" 1937 "Invalid" 1936 "Invalid" 1935 "Invalid" 1934 "Invalid" 1933 "Invalid" 1932 "Invalid" 1931 "Invalid" 1930 "Invalid" 1929 "Invalid" 1928 "Invalid" 1927 "Invalid" 1926 "Invalid" 1925 "Invalid" 1924 "Invalid" 1923 "Invalid" 1922 "Invalid" 1921 "Invalid" 1920 "Invalid" 1919 "Invalid" 1918 "Invalid" 1917 "Invalid" 1916 "Invalid" 1915 "Invalid" 1914 "Invalid" 1913 "Invalid" 1912 "Invalid" 1911 "Invalid" 1910 "Invalid" 1909 "Invalid" 1908 "Invalid" 1907 "Invalid" 1906 "Invalid" 1905 "Invalid" 1904 "Invalid" 1903 "Invalid" 1902 "Invalid" 1901 "Invalid" 1900 "Invalid" 1899 "Invalid" 1898 "Invalid" 1897 "Invalid" 1896 "Invalid" 1895 "Invalid" 1894 "Invalid" 1893 "Invalid" 1892 "Invalid" 1891 "Invalid" 1890 "Invalid" 1889 "Invalid" 1888 "Invalid" 1887 "Invalid" 1886 "Invalid" 1885 "Invalid" 1884 "Invalid" 1883 "Invalid" 1882 "Invalid" 1881 "Invalid" 1880 "Invalid" 1879 "Invalid" 1878 "Invalid" 1877 "Invalid" 1876 "Invalid" 1875 "Invalid" 1874 "Invalid" 1873 "Invalid" 1872 "Invalid" 1871 "Invalid" 1870 "Invalid" 1869 "Invalid" 1868 "Invalid" 1867 "Invalid" 1866 "Invalid" 1865 "Invalid" 1864 "Invalid" 1863 "Invalid" 1862 "Invalid" 1861 "Invalid" 1860 "Invalid" 1859 "Invalid" 1858 "Invalid" 1857 "Invalid" 1856 "Invalid" 1855 "Invalid" 1854 "Invalid" 1853 "Invalid" 1852 "Invalid" 1851 "Invalid" 1850 "Invalid" 1849 "Invalid" 1848 "Invalid" 1847 "Invalid" 1846 "Invalid" 1845 "Invalid" 1844 "Invalid" 1843 "Invalid" 1842 "Invalid" 1841 "Invalid" 1840 "Invalid" 1839 "Invalid" 1838 "Invalid" 1837 "Invalid" 1836 "Invalid" 1835 "Invalid" 1834 "Invalid" 1833 "Invalid" 1832 "Invalid" 1831 "Invalid" 1830 "Invalid" 1829 "Invalid" 1828 "Invalid" 1827 "Invalid" 1826 "Invalid" 1825 "Invalid" 1824 "Invalid" 1823 "Invalid" 1822 "Invalid" 1821 "Invalid" 1820 "Invalid" 1819 "Invalid" 1818 "Invalid" 1817 "Invalid" 1816 "Invalid" 1815 "Invalid" 1814 "Invalid" 1813 "Invalid" 1812 "Invalid" 1811 "Invalid" 1810 "Invalid" 1809 "Invalid" 1808 "Invalid" 1807 "Invalid" 1806 "Invalid" 1805 "Invalid" 1804 "Invalid" 1803 "Invalid" 1802 "Invalid" 1801 "Invalid" ;
VAL_ 556 BCU_CellTmp010_RM 255 "Invalid" 254 "Invalid" 253 "Invalid" 252 "Invalid" 251 "Invalid" 250 "Invalid" 249 "Invalid" 248 "Invalid" 247 "Invalid" 246 "Invalid" 245 "Invalid" 244 "Invalid" 243 "Invalid" 242 "Invalid" 241 "Invalid" 240 "Invalid" 239 "Invalid" 238 "Invalid" 237 "Invalid" 236 "Invalid" 235 "Invalid" 234 "Invalid" 233 "Invalid" 232 "Invalid" 231 "Invalid" 230 "Invalid" 229 "Invalid" 228 "Invalid" 227 "Invalid" 226 "Invalid" 225 "Invalid" 224 "Invalid" 223 "Invalid" 222 "Invalid" 221 "Invalid" 220 "Invalid" 219 "Invalid" 218 "Invalid" 217 "Invalid" 216 "Invalid" 215 "Invalid" 214 "Invalid" 213 "Invalid" 212 "Invalid" 211 "Invalid" 210 "Invalid" 209 "Invalid" 208 "Invalid" 207 "Invalid" 206 "Invalid" 205 "Invalid" 204 "Invalid" 203 "Invalid" 202 "Invalid" 201 "Invalid" 200 "Invalid" 199 "Invalid" 198 "Invalid" 197 "Invalid" 196 "Invalid" 195 "Invalid" 194 "Invalid" 193 "Invalid" 192 "Invalid" 191 "Invalid" 190 "Invalid" 189 "Invalid" 188 "Invalid" 187 "Invalid" 186 "Invalid" 185 "Invalid" 184 "Invalid" 183 "Invalid" 182 "Invalid" 181 "Invalid" 180 "Invalid" 179 "Invalid" 178 "Invalid" 177 "Invalid" 176 "Invalid" 175 "Invalid" 174 "Invalid" 173 "Invalid" 172 "Invalid" 171 "Invalid" 170 "Invalid" 169 "Invalid" 168 "Invalid" 167 "Invalid" 166 "Invalid" 165 "Invalid" 164 "Invalid" 163 "Invalid" 162 "Invalid" 161 "Invalid" ;
VAL_ 557 BCU_CellVlt051_RM 2047 "Invalid" 2046 "Invalid" 2045 "Invalid" 2044 "Invalid" 2043 "Invalid" 2042 "Invalid" 2041 "Invalid" 2040 "Invalid" 2039 "Invalid" 2038 "Invalid" 2037 "Invalid" 2036 "Invalid" 2035 "Invalid" 2034 "Invalid" 2033 "Invalid" 2032 "Invalid" 2031 "Invalid" 2030 "Invalid" 2029 "Invalid" 2028 "Invalid" 2027 "Invalid" 2026 "Invalid" 2025 "Invalid" 2024 "Invalid" 2023 "Invalid" 2022 "Invalid" 2021 "Invalid" 2020 "Invalid" 2019 "Invalid" 2018 "Invalid" 2017 "Invalid" 2016 "Invalid" 2015 "Invalid" 2014 "Invalid" 2013 "Invalid" 2012 "Invalid" 2011 "Invalid" 2010 "Invalid" 2009 "Invalid" 2008 "Invalid" 2007 "Invalid" 2006 "Invalid" 2005 "Invalid" 2004 "Invalid" 2003 "Invalid" 2002 "Invalid" 2001 "Invalid" 2000 "Invalid" 1999 "Invalid" 1998 "Invalid" 1997 "Invalid" 1996 "Invalid" 1995 "Invalid" 1994 "Invalid" 1993 "Invalid" 1992 "Invalid" 1991 "Invalid" 1990 "Invalid" 1989 "Invalid" 1988 "Invalid" 1987 "Invalid" 1986 "Invalid" 1985 "Invalid" 1984 "Invalid" 1983 "Invalid" 1982 "Invalid" 1981 "Invalid" 1980 "Invalid" 1979 "Invalid" 1978 "Invalid" 1977 "Invalid" 1976 "Invalid" 1975 "Invalid" 1974 "Invalid" 1973 "Invalid" 1972 "Invalid" 1971 "Invalid" 1970 "Invalid" 1969 "Invalid" 1968 "Invalid" 1967 "Invalid" 1966 "Invalid" 1965 "Invalid" 1964 "Invalid" 1963 "Invalid" 1962 "Invalid" 1961 "Invalid" 1960 "Invalid" 1959 "Invalid" 1958 "Invalid" 1957 "Invalid" 1956 "Invalid" 1955 "Invalid" 1954 "Invalid" 1953 "Invalid" 1952 "Invalid" 1951 "Invalid" 1950 "Invalid" 1949 "Invalid" 1948 "Invalid" 1947 "Invalid" 1946 "Invalid" 1945 "Invalid" 1944 "Invalid" 1943 "Invalid" 1942 "Invalid" 1941 "Invalid" 1940 "Invalid" 1939 "Invalid" 1938 "Invalid" 1937 "Invalid" 1936 "Invalid" 1935 "Invalid" 1934 "Invalid" 1933 "Invalid" 1932 "Invalid" 1931 "Invalid" 1930 "Invalid" 1929 "Invalid" 1928 "Invalid" 1927 "Invalid" 1926 "Invalid" 1925 "Invalid" 1924 "Invalid" 1923 "Invalid" 1922 "Invalid" 1921 "Invalid" 1920 "Invalid" 1919 "Invalid" 1918 "Invalid" 1917 "Invalid" 1916 "Invalid" 1915 "Invalid" 1914 "Invalid" 1913 "Invalid" 1912 "Invalid" 1911 "Invalid" 1910 "Invalid" 1909 "Invalid" 1908 "Invalid" 1907 "Invalid" 1906 "Invalid" 1905 "Invalid" 1904 "Invalid" 1903 "Invalid" 1902 "Invalid" 1901 "Invalid" 1900 "Invalid" 1899 "Invalid" 1898 "Invalid" 1897 "Invalid" 1896 "Invalid" 1895 "Invalid" 1894 "Invalid" 1893 "Invalid" 1892 "Invalid" 1891 "Invalid" 1890 "Invalid" 1889 "Invalid" 1888 "Invalid" 1887 "Invalid" 1886 "Invalid" 1885 "Invalid" 1884 "Invalid" 1883 "Invalid" 1882 "Invalid" 1881 "Invalid" 1880 "Invalid" 1879 "Invalid" 1878 "Invalid" 1877 "Invalid" 1876 "Invalid" 1875 "Invalid" 1874 "Invalid" 1873 "Invalid" 1872 "Invalid" 1871 "Invalid" 1870 "Invalid" 1869 "Invalid" 1868 "Invalid" 1867 "Invalid" 1866 "Invalid" 1865 "Invalid" 1864 "Invalid" 1863 "Invalid" 1862 "Invalid" 1861 "Invalid" 1860 "Invalid" 1859 "Invalid" 1858 "Invalid" 1857 "Invalid" 1856 "Invalid" 1855 "Invalid" 1854 "Invalid" 1853 "Invalid" 1852 "Invalid" 1851 "Invalid" 1850 "Invalid" 1849 "Invalid" 1848 "Invalid" 1847 "Invalid" 1846 "Invalid" 1845 "Invalid" 1844 "Invalid" 1843 "Invalid" 1842 "Invalid" 1841 "Invalid" 1840 "Invalid" 1839 "Invalid" 1838 "Invalid" 1837 "Invalid" 1836 "Invalid" 1835 "Invalid" 1834 "Invalid" 1833 "Invalid" 1832 "Invalid" 1831 "Invalid" 1830 "Invalid" 1829 "Invalid" 1828 "Invalid" 1827 "Invalid" 1826 "Invalid" 1825 "Invalid" 1824 "Invalid" 1823 "Invalid" 1822 "Invalid" 1821 "Invalid" 1820 "Invalid" 1819 "Invalid" 1818 "Invalid" 1817 "Invalid" 1816 "Invalid" 1815 "Invalid" 1814 "Invalid" 1813 "Invalid" 1812 "Invalid" 1811 "Invalid" 1810 "Invalid" 1809 "Invalid" 1808 "Invalid" 1807 "Invalid" 1806 "Invalid" 1805 "Invalid" 1804 "Invalid" 1803 "Invalid" 1802 "Invalid" 1801 "Invalid" ;
VAL_ 557 BCU_CellVlt052_RM 2047 "Invalid" 2046 "Invalid" 2045 "Invalid" 2044 "Invalid" 2043 "Invalid" 2042 "Invalid" 2041 "Invalid" 2040 "Invalid" 2039 "Invalid" 2038 "Invalid" 2037 "Invalid" 2036 "Invalid" 2035 "Invalid" 2034 "Invalid" 2033 "Invalid" 2032 "Invalid" 2031 "Invalid" 2030 "Invalid" 2029 "Invalid" 2028 "Invalid" 2027 "Invalid" 2026 "Invalid" 2025 "Invalid" 2024 "Invalid" 2023 "Invalid" 2022 "Invalid" 2021 "Invalid" 2020 "Invalid" 2019 "Invalid" 2018 "Invalid" 2017 "Invalid" 2016 "Invalid" 2015 "Invalid" 2014 "Invalid" 2013 "Invalid" 2012 "Invalid" 2011 "Invalid" 2010 "Invalid" 2009 "Invalid" 2008 "Invalid" 2007 "Invalid" 2006 "Invalid" 2005 "Invalid" 2004 "Invalid" 2003 "Invalid" 2002 "Invalid" 2001 "Invalid" 2000 "Invalid" 1999 "Invalid" 1998 "Invalid" 1997 "Invalid" 1996 "Invalid" 1995 "Invalid" 1994 "Invalid" 1993 "Invalid" 1992 "Invalid" 1991 "Invalid" 1990 "Invalid" 1989 "Invalid" 1988 "Invalid" 1987 "Invalid" 1986 "Invalid" 1985 "Invalid" 1984 "Invalid" 1983 "Invalid" 1982 "Invalid" 1981 "Invalid" 1980 "Invalid" 1979 "Invalid" 1978 "Invalid" 1977 "Invalid" 1976 "Invalid" 1975 "Invalid" 1974 "Invalid" 1973 "Invalid" 1972 "Invalid" 1971 "Invalid" 1970 "Invalid" 1969 "Invalid" 1968 "Invalid" 1967 "Invalid" 1966 "Invalid" 1965 "Invalid" 1964 "Invalid" 1963 "Invalid" 1962 "Invalid" 1961 "Invalid" 1960 "Invalid" 1959 "Invalid" 1958 "Invalid" 1957 "Invalid" 1956 "Invalid" 1955 "Invalid" 1954 "Invalid" 1953 "Invalid" 1952 "Invalid" 1951 "Invalid" 1950 "Invalid" 1949 "Invalid" 1948 "Invalid" 1947 "Invalid" 1946 "Invalid" 1945 "Invalid" 1944 "Invalid" 1943 "Invalid" 1942 "Invalid" 1941 "Invalid" 1940 "Invalid" 1939 "Invalid" 1938 "Invalid" 1937 "Invalid" 1936 "Invalid" 1935 "Invalid" 1934 "Invalid" 1933 "Invalid" 1932 "Invalid" 1931 "Invalid" 1930 "Invalid" 1929 "Invalid" 1928 "Invalid" 1927 "Invalid" 1926 "Invalid" 1925 "Invalid" 1924 "Invalid" 1923 "Invalid" 1922 "Invalid" 1921 "Invalid" 1920 "Invalid" 1919 "Invalid" 1918 "Invalid" 1917 "Invalid" 1916 "Invalid" 1915 "Invalid" 1914 "Invalid" 1913 "Invalid" 1912 "Invalid" 1911 "Invalid" 1910 "Invalid" 1909 "Invalid" 1908 "Invalid" 1907 "Invalid" 1906 "Invalid" 1905 "Invalid" 1904 "Invalid" 1903 "Invalid" 1902 "Invalid" 1901 "Invalid" 1900 "Invalid" 1899 "Invalid" 1898 "Invalid" 1897 "Invalid" 1896 "Invalid" 1895 "Invalid" 1894 "Invalid" 1893 "Invalid" 1892 "Invalid" 1891 "Invalid" 1890 "Invalid" 1889 "Invalid" 1888 "Invalid" 1887 "Invalid" 1886 "Invalid" 1885 "Invalid" 1884 "Invalid" 1883 "Invalid" 1882 "Invalid" 1881 "Invalid" 1880 "Invalid" 1879 "Invalid" 1878 "Invalid" 1877 "Invalid" 1876 "Invalid" 1875 "Invalid" 1874 "Invalid" 1873 "Invalid" 1872 "Invalid" 1871 "Invalid" 1870 "Invalid" 1869 "Invalid" 1868 "Invalid" 1867 "Invalid" 1866 "Invalid" 1865 "Invalid" 1864 "Invalid" 1863 "Invalid" 1862 "Invalid" 1861 "Invalid" 1860 "Invalid" 1859 "Invalid" 1858 "Invalid" 1857 "Invalid" 1856 "Invalid" 1855 "Invalid" 1854 "Invalid" 1853 "Invalid" 1852 "Invalid" 1851 "Invalid" 1850 "Invalid" 1849 "Invalid" 1848 "Invalid" 1847 "Invalid" 1846 "Invalid" 1845 "Invalid" 1844 "Invalid" 1843 "Invalid" 1842 "Invalid" 1841 "Invalid" 1840 "Invalid" 1839 "Invalid" 1838 "Invalid" 1837 "Invalid" 1836 "Invalid" 1835 "Invalid" 1834 "Invalid" 1833 "Invalid" 1832 "Invalid" 1831 "Invalid" 1830 "Invalid" 1829 "Invalid" 1828 "Invalid" 1827 "Invalid" 1826 "Invalid" 1825 "Invalid" 1824 "Invalid" 1823 "Invalid" 1822 "Invalid" 1821 "Invalid" 1820 "Invalid" 1819 "Invalid" 1818 "Invalid" 1817 "Invalid" 1816 "Invalid" 1815 "Invalid" 1814 "Invalid" 1813 "Invalid" 1812 "Invalid" 1811 "Invalid" 1810 "Invalid" 1809 "Invalid" 1808 "Invalid" 1807 "Invalid" 1806 "Invalid" 1805 "Invalid" 1804 "Invalid" 1803 "Invalid" 1802 "Invalid" 1801 "Invalid" ;
VAL_ 557 BCU_CellVlt053_RM 2047 "Invalid" 2046 "Invalid" 2045 "Invalid" 2044 "Invalid" 2043 "Invalid" 2042 "Invalid" 2041 "Invalid" 2040 "Invalid" 2039 "Invalid" 2038 "Invalid" 2037 "Invalid" 2036 "Invalid" 2035 "Invalid" 2034 "Invalid" 2033 "Invalid" 2032 "Invalid" 2031 "Invalid" 2030 "Invalid" 2029 "Invalid" 2028 "Invalid" 2027 "Invalid" 2026 "Invalid" 2025 "Invalid" 2024 "Invalid" 2023 "Invalid" 2022 "Invalid" 2021 "Invalid" 2020 "Invalid" 2019 "Invalid" 2018 "Invalid" 2017 "Invalid" 2016 "Invalid" 2015 "Invalid" 2014 "Invalid" 2013 "Invalid" 2012 "Invalid" 2011 "Invalid" 2010 "Invalid" 2009 "Invalid" 2008 "Invalid" 2007 "Invalid" 2006 "Invalid" 2005 "Invalid" 2004 "Invalid" 2003 "Invalid" 2002 "Invalid" 2001 "Invalid" 2000 "Invalid" 1999 "Invalid" 1998 "Invalid" 1997 "Invalid" 1996 "Invalid" 1995 "Invalid" 1994 "Invalid" 1993 "Invalid" 1992 "Invalid" 1991 "Invalid" 1990 "Invalid" 1989 "Invalid" 1988 "Invalid" 1987 "Invalid" 1986 "Invalid" 1985 "Invalid" 1984 "Invalid" 1983 "Invalid" 1982 "Invalid" 1981 "Invalid" 1980 "Invalid" 1979 "Invalid" 1978 "Invalid" 1977 "Invalid" 1976 "Invalid" 1975 "Invalid" 1974 "Invalid" 1973 "Invalid" 1972 "Invalid" 1971 "Invalid" 1970 "Invalid" 1969 "Invalid" 1968 "Invalid" 1967 "Invalid" 1966 "Invalid" 1965 "Invalid" 1964 "Invalid" 1963 "Invalid" 1962 "Invalid" 1961 "Invalid" 1960 "Invalid" 1959 "Invalid" 1958 "Invalid" 1957 "Invalid" 1956 "Invalid" 1955 "Invalid" 1954 "Invalid" 1953 "Invalid" 1952 "Invalid" 1951 "Invalid" 1950 "Invalid" 1949 "Invalid" 1948 "Invalid" 1947 "Invalid" 1946 "Invalid" 1945 "Invalid" 1944 "Invalid" 1943 "Invalid" 1942 "Invalid" 1941 "Invalid" 1940 "Invalid" 1939 "Invalid" 1938 "Invalid" 1937 "Invalid" 1936 "Invalid" 1935 "Invalid" 1934 "Invalid" 1933 "Invalid" 1932 "Invalid" 1931 "Invalid" 1930 "Invalid" 1929 "Invalid" 1928 "Invalid" 1927 "Invalid" 1926 "Invalid" 1925 "Invalid" 1924 "Invalid" 1923 "Invalid" 1922 "Invalid" 1921 "Invalid" 1920 "Invalid" 1919 "Invalid" 1918 "Invalid" 1917 "Invalid" 1916 "Invalid" 1915 "Invalid" 1914 "Invalid" 1913 "Invalid" 1912 "Invalid" 1911 "Invalid" 1910 "Invalid" 1909 "Invalid" 1908 "Invalid" 1907 "Invalid" 1906 "Invalid" 1905 "Invalid" 1904 "Invalid" 1903 "Invalid" 1902 "Invalid" 1901 "Invalid" 1900 "Invalid" 1899 "Invalid" 1898 "Invalid" 1897 "Invalid" 1896 "Invalid" 1895 "Invalid" 1894 "Invalid" 1893 "Invalid" 1892 "Invalid" 1891 "Invalid" 1890 "Invalid" 1889 "Invalid" 1888 "Invalid" 1887 "Invalid" 1886 "Invalid" 1885 "Invalid" 1884 "Invalid" 1883 "Invalid" 1882 "Invalid" 1881 "Invalid" 1880 "Invalid" 1879 "Invalid" 1878 "Invalid" 1877 "Invalid" 1876 "Invalid" 1875 "Invalid" 1874 "Invalid" 1873 "Invalid" 1872 "Invalid" 1871 "Invalid" 1870 "Invalid" 1869 "Invalid" 1868 "Invalid" 1867 "Invalid" 1866 "Invalid" 1865 "Invalid" 1864 "Invalid" 1863 "Invalid" 1862 "Invalid" 1861 "Invalid" 1860 "Invalid" 1859 "Invalid" 1858 "Invalid" 1857 "Invalid" 1856 "Invalid" 1855 "Invalid" 1854 "Invalid" 1853 "Invalid" 1852 "Invalid" 1851 "Invalid" 1850 "Invalid" 1849 "Invalid" 1848 "Invalid" 1847 "Invalid" 1846 "Invalid" 1845 "Invalid" 1844 "Invalid" 1843 "Invalid" 1842 "Invalid" 1841 "Invalid" 1840 "Invalid" 1839 "Invalid" 1838 "Invalid" 1837 "Invalid" 1836 "Invalid" 1835 "Invalid" 1834 "Invalid" 1833 "Invalid" 1832 "Invalid" 1831 "Invalid" 1830 "Invalid" 1829 "Invalid" 1828 "Invalid" 1827 "Invalid" 1826 "Invalid" 1825 "Invalid" 1824 "Invalid" 1823 "Invalid" 1822 "Invalid" 1821 "Invalid" 1820 "Invalid" 1819 "Invalid" 1818 "Invalid" 1817 "Invalid" 1816 "Invalid" 1815 "Invalid" 1814 "Invalid" 1813 "Invalid" 1812 "Invalid" 1811 "Invalid" 1810 "Invalid" 1809 "Invalid" 1808 "Invalid" 1807 "Invalid" 1806 "Invalid" 1805 "Invalid" 1804 "Invalid" 1803 "Invalid" 1802 "Invalid" 1801 "Invalid" ;
VAL_ 557 BCU_CellVlt054_RM 2047 "Invalid" 2046 "Invalid" 2045 "Invalid" 2044 "Invalid" 2043 "Invalid" 2042 "Invalid" 2041 "Invalid" 2040 "Invalid" 2039 "Invalid" 2038 "Invalid" 2037 "Invalid" 2036 "Invalid" 2035 "Invalid" 2034 "Invalid" 2033 "Invalid" 2032 "Invalid" 2031 "Invalid" 2030 "Invalid" 2029 "Invalid" 2028 "Invalid" 2027 "Invalid" 2026 "Invalid" 2025 "Invalid" 2024 "Invalid" 2023 "Invalid" 2022 "Invalid" 2021 "Invalid" 2020 "Invalid" 2019 "Invalid" 2018 "Invalid" 2017 "Invalid" 2016 "Invalid" 2015 "Invalid" 2014 "Invalid" 2013 "Invalid" 2012 "Invalid" 2011 "Invalid" 2010 "Invalid" 2009 "Invalid" 2008 "Invalid" 2007 "Invalid" 2006 "Invalid" 2005 "Invalid" 2004 "Invalid" 2003 "Invalid" 2002 "Invalid" 2001 "Invalid" 2000 "Invalid" 1999 "Invalid" 1998 "Invalid" 1997 "Invalid" 1996 "Invalid" 1995 "Invalid" 1994 "Invalid" 1993 "Invalid" 1992 "Invalid" 1991 "Invalid" 1990 "Invalid" 1989 "Invalid" 1988 "Invalid" 1987 "Invalid" 1986 "Invalid" 1985 "Invalid" 1984 "Invalid" 1983 "Invalid" 1982 "Invalid" 1981 "Invalid" 1980 "Invalid" 1979 "Invalid" 1978 "Invalid" 1977 "Invalid" 1976 "Invalid" 1975 "Invalid" 1974 "Invalid" 1973 "Invalid" 1972 "Invalid" 1971 "Invalid" 1970 "Invalid" 1969 "Invalid" 1968 "Invalid" 1967 "Invalid" 1966 "Invalid" 1965 "Invalid" 1964 "Invalid" 1963 "Invalid" 1962 "Invalid" 1961 "Invalid" 1960 "Invalid" 1959 "Invalid" 1958 "Invalid" 1957 "Invalid" 1956 "Invalid" 1955 "Invalid" 1954 "Invalid" 1953 "Invalid" 1952 "Invalid" 1951 "Invalid" 1950 "Invalid" 1949 "Invalid" 1948 "Invalid" 1947 "Invalid" 1946 "Invalid" 1945 "Invalid" 1944 "Invalid" 1943 "Invalid" 1942 "Invalid" 1941 "Invalid" 1940 "Invalid" 1939 "Invalid" 1938 "Invalid" 1937 "Invalid" 1936 "Invalid" 1935 "Invalid" 1934 "Invalid" 1933 "Invalid" 1932 "Invalid" 1931 "Invalid" 1930 "Invalid" 1929 "Invalid" 1928 "Invalid" 1927 "Invalid" 1926 "Invalid" 1925 "Invalid" 1924 "Invalid" 1923 "Invalid" 1922 "Invalid" 1921 "Invalid" 1920 "Invalid" 1919 "Invalid" 1918 "Invalid" 1917 "Invalid" 1916 "Invalid" 1915 "Invalid" 1914 "Invalid" 1913 "Invalid" 1912 "Invalid" 1911 "Invalid" 1910 "Invalid" 1909 "Invalid" 1908 "Invalid" 1907 "Invalid" 1906 "Invalid" 1905 "Invalid" 1904 "Invalid" 1903 "Invalid" 1902 "Invalid" 1901 "Invalid" 1900 "Invalid" 1899 "Invalid" 1898 "Invalid" 1897 "Invalid" 1896 "Invalid" 1895 "Invalid" 1894 "Invalid" 1893 "Invalid" 1892 "Invalid" 1891 "Invalid" 1890 "Invalid" 1889 "Invalid" 1888 "Invalid" 1887 "Invalid" 1886 "Invalid" 1885 "Invalid" 1884 "Invalid" 1883 "Invalid" 1882 "Invalid" 1881 "Invalid" 1880 "Invalid" 1879 "Invalid" 1878 "Invalid" 1877 "Invalid" 1876 "Invalid" 1875 "Invalid" 1874 "Invalid" 1873 "Invalid" 1872 "Invalid" 1871 "Invalid" 1870 "Invalid" 1869 "Invalid" 1868 "Invalid" 1867 "Invalid" 1866 "Invalid" 1865 "Invalid" 1864 "Invalid" 1863 "Invalid" 1862 "Invalid" 1861 "Invalid" 1860 "Invalid" 1859 "Invalid" 1858 "Invalid" 1857 "Invalid" 1856 "Invalid" 1855 "Invalid" 1854 "Invalid" 1853 "Invalid" 1852 "Invalid" 1851 "Invalid" 1850 "Invalid" 1849 "Invalid" 1848 "Invalid" 1847 "Invalid" 1846 "Invalid" 1845 "Invalid" 1844 "Invalid" 1843 "Invalid" 1842 "Invalid" 1841 "Invalid" 1840 "Invalid" 1839 "Invalid" 1838 "Invalid" 1837 "Invalid" 1836 "Invalid" 1835 "Invalid" 1834 "Invalid" 1833 "Invalid" 1832 "Invalid" 1831 "Invalid" 1830 "Invalid" 1829 "Invalid" 1828 "Invalid" 1827 "Invalid" 1826 "Invalid" 1825 "Invalid" 1824 "Invalid" 1823 "Invalid" 1822 "Invalid" 1821 "Invalid" 1820 "Invalid" 1819 "Invalid" 1818 "Invalid" 1817 "Invalid" 1816 "Invalid" 1815 "Invalid" 1814 "Invalid" 1813 "Invalid" 1812 "Invalid" 1811 "Invalid" 1810 "Invalid" 1809 "Invalid" 1808 "Invalid" 1807 "Invalid" 1806 "Invalid" 1805 "Invalid" 1804 "Invalid" 1803 "Invalid" 1802 "Invalid" 1801 "Invalid" ;
VAL_ 557 BCU_CellVlt055_RM 2047 "Invalid" 2046 "Invalid" 2045 "Invalid" 2044 "Invalid" 2043 "Invalid" 2042 "Invalid" 2041 "Invalid" 2040 "Invalid" 2039 "Invalid" 2038 "Invalid" 2037 "Invalid" 2036 "Invalid" 2035 "Invalid" 2034 "Invalid" 2033 "Invalid" 2032 "Invalid" 2031 "Invalid" 2030 "Invalid" 2029 "Invalid" 2028 "Invalid" 2027 "Invalid" 2026 "Invalid" 2025 "Invalid" 2024 "Invalid" 2023 "Invalid" 2022 "Invalid" 2021 "Invalid" 2020 "Invalid" 2019 "Invalid" 2018 "Invalid" 2017 "Invalid" 2016 "Invalid" 2015 "Invalid" 2014 "Invalid" 2013 "Invalid" 2012 "Invalid" 2011 "Invalid" 2010 "Invalid" 2009 "Invalid" 2008 "Invalid" 2007 "Invalid" 2006 "Invalid" 2005 "Invalid" 2004 "Invalid" 2003 "Invalid" 2002 "Invalid" 2001 "Invalid" 2000 "Invalid" 1999 "Invalid" 1998 "Invalid" 1997 "Invalid" 1996 "Invalid" 1995 "Invalid" 1994 "Invalid" 1993 "Invalid" 1992 "Invalid" 1991 "Invalid" 1990 "Invalid" 1989 "Invalid" 1988 "Invalid" 1987 "Invalid" 1986 "Invalid" 1985 "Invalid" 1984 "Invalid" 1983 "Invalid" 1982 "Invalid" 1981 "Invalid" 1980 "Invalid" 1979 "Invalid" 1978 "Invalid" 1977 "Invalid" 1976 "Invalid" 1975 "Invalid" 1974 "Invalid" 1973 "Invalid" 1972 "Invalid" 1971 "Invalid" 1970 "Invalid" 1969 "Invalid" 1968 "Invalid" 1967 "Invalid" 1966 "Invalid" 1965 "Invalid" 1964 "Invalid" 1963 "Invalid" 1962 "Invalid" 1961 "Invalid" 1960 "Invalid" 1959 "Invalid" 1958 "Invalid" 1957 "Invalid" 1956 "Invalid" 1955 "Invalid" 1954 "Invalid" 1953 "Invalid" 1952 "Invalid" 1951 "Invalid" 1950 "Invalid" 1949 "Invalid" 1948 "Invalid" 1947 "Invalid" 1946 "Invalid" 1945 "Invalid" 1944 "Invalid" 1943 "Invalid" 1942 "Invalid" 1941 "Invalid" 1940 "Invalid" 1939 "Invalid" 1938 "Invalid" 1937 "Invalid" 1936 "Invalid" 1935 "Invalid" 1934 "Invalid" 1933 "Invalid" 1932 "Invalid" 1931 "Invalid" 1930 "Invalid" 1929 "Invalid" 1928 "Invalid" 1927 "Invalid" 1926 "Invalid" 1925 "Invalid" 1924 "Invalid" 1923 "Invalid" 1922 "Invalid" 1921 "Invalid" 1920 "Invalid" 1919 "Invalid" 1918 "Invalid" 1917 "Invalid" 1916 "Invalid" 1915 "Invalid" 1914 "Invalid" 1913 "Invalid" 1912 "Invalid" 1911 "Invalid" 1910 "Invalid" 1909 "Invalid" 1908 "Invalid" 1907 "Invalid" 1906 "Invalid" 1905 "Invalid" 1904 "Invalid" 1903 "Invalid" 1902 "Invalid" 1901 "Invalid" 1900 "Invalid" 1899 "Invalid" 1898 "Invalid" 1897 "Invalid" 1896 "Invalid" 1895 "Invalid" 1894 "Invalid" 1893 "Invalid" 1892 "Invalid" 1891 "Invalid" 1890 "Invalid" 1889 "Invalid" 1888 "Invalid" 1887 "Invalid" 1886 "Invalid" 1885 "Invalid" 1884 "Invalid" 1883 "Invalid" 1882 "Invalid" 1881 "Invalid" 1880 "Invalid" 1879 "Invalid" 1878 "Invalid" 1877 "Invalid" 1876 "Invalid" 1875 "Invalid" 1874 "Invalid" 1873 "Invalid" 1872 "Invalid" 1871 "Invalid" 1870 "Invalid" 1869 "Invalid" 1868 "Invalid" 1867 "Invalid" 1866 "Invalid" 1865 "Invalid" 1864 "Invalid" 1863 "Invalid" 1862 "Invalid" 1861 "Invalid" 1860 "Invalid" 1859 "Invalid" 1858 "Invalid" 1857 "Invalid" 1856 "Invalid" 1855 "Invalid" 1854 "Invalid" 1853 "Invalid" 1852 "Invalid" 1851 "Invalid" 1850 "Invalid" 1849 "Invalid" 1848 "Invalid" 1847 "Invalid" 1846 "Invalid" 1845 "Invalid" 1844 "Invalid" 1843 "Invalid" 1842 "Invalid" 1841 "Invalid" 1840 "Invalid" 1839 "Invalid" 1838 "Invalid" 1837 "Invalid" 1836 "Invalid" 1835 "Invalid" 1834 "Invalid" 1833 "Invalid" 1832 "Invalid" 1831 "Invalid" 1830 "Invalid" 1829 "Invalid" 1828 "Invalid" 1827 "Invalid" 1826 "Invalid" 1825 "Invalid" 1824 "Invalid" 1823 "Invalid" 1822 "Invalid" 1821 "Invalid" 1820 "Invalid" 1819 "Invalid" 1818 "Invalid" 1817 "Invalid" 1816 "Invalid" 1815 "Invalid" 1814 "Invalid" 1813 "Invalid" 1812 "Invalid" 1811 "Invalid" 1810 "Invalid" 1809 "Invalid" 1808 "Invalid" 1807 "Invalid" 1806 "Invalid" 1805 "Invalid" 1804 "Invalid" 1803 "Invalid" 1802 "Invalid" 1801 "Invalid" ;
VAL_ 557 BCU_CellTmp011_RM 255 "Invalid" 254 "Invalid" 253 "Invalid" 252 "Invalid" 251 "Invalid" 250 "Invalid" 249 "Invalid" 248 "Invalid" 247 "Invalid" 246 "Invalid" 245 "Invalid" 244 "Invalid" 243 "Invalid" 242 "Invalid" 241 "Invalid" 240 "Invalid" 239 "Invalid" 238 "Invalid" 237 "Invalid" 236 "Invalid" 235 "Invalid" 234 "Invalid" 233 "Invalid" 232 "Invalid" 231 "Invalid" 230 "Invalid" 229 "Invalid" 228 "Invalid" 227 "Invalid" 226 "Invalid" 225 "Invalid" 224 "Invalid" 223 "Invalid" 222 "Invalid" 221 "Invalid" 220 "Invalid" 219 "Invalid" 218 "Invalid" 217 "Invalid" 216 "Invalid" 215 "Invalid" 214 "Invalid" 213 "Invalid" 212 "Invalid" 211 "Invalid" 210 "Invalid" 209 "Invalid" 208 "Invalid" 207 "Invalid" 206 "Invalid" 205 "Invalid" 204 "Invalid" 203 "Invalid" 202 "Invalid" 201 "Invalid" 200 "Invalid" 199 "Invalid" 198 "Invalid" 197 "Invalid" 196 "Invalid" 195 "Invalid" 194 "Invalid" 193 "Invalid" 192 "Invalid" 191 "Invalid" 190 "Invalid" 189 "Invalid" 188 "Invalid" 187 "Invalid" 186 "Invalid" 185 "Invalid" 184 "Invalid" 183 "Invalid" 182 "Invalid" 181 "Invalid" 180 "Invalid" 179 "Invalid" 178 "Invalid" 177 "Invalid" 176 "Invalid" 175 "Invalid" 174 "Invalid" 173 "Invalid" 172 "Invalid" 171 "Invalid" 170 "Invalid" 169 "Invalid" 168 "Invalid" 167 "Invalid" 166 "Invalid" 165 "Invalid" 164 "Invalid" 163 "Invalid" 162 "Invalid" 161 "Invalid" ;
VAL_ 558 BCU_CellVlt056_RM 2047 "Invalid" 2046 "Invalid" 2045 "Invalid" 2044 "Invalid" 2043 "Invalid" 2042 "Invalid" 2041 "Invalid" 2040 "Invalid" 2039 "Invalid" 2038 "Invalid" 2037 "Invalid" 2036 "Invalid" 2035 "Invalid" 2034 "Invalid" 2033 "Invalid" 2032 "Invalid" 2031 "Invalid" 2030 "Invalid" 2029 "Invalid" 2028 "Invalid" 2027 "Invalid" 2026 "Invalid" 2025 "Invalid" 2024 "Invalid" 2023 "Invalid" 2022 "Invalid" 2021 "Invalid" 2020 "Invalid" 2019 "Invalid" 2018 "Invalid" 2017 "Invalid" 2016 "Invalid" 2015 "Invalid" 2014 "Invalid" 2013 "Invalid" 2012 "Invalid" 2011 "Invalid" 2010 "Invalid" 2009 "Invalid" 2008 "Invalid" 2007 "Invalid" 2006 "Invalid" 2005 "Invalid" 2004 "Invalid" 2003 "Invalid" 2002 "Invalid" 2001 "Invalid" 2000 "Invalid" 1999 "Invalid" 1998 "Invalid" 1997 "Invalid" 1996 "Invalid" 1995 "Invalid" 1994 "Invalid" 1993 "Invalid" 1992 "Invalid" 1991 "Invalid" 1990 "Invalid" 1989 "Invalid" 1988 "Invalid" 1987 "Invalid" 1986 "Invalid" 1985 "Invalid" 1984 "Invalid" 1983 "Invalid" 1982 "Invalid" 1981 "Invalid" 1980 "Invalid" 1979 "Invalid" 1978 "Invalid" 1977 "Invalid" 1976 "Invalid" 1975 "Invalid" 1974 "Invalid" 1973 "Invalid" 1972 "Invalid" 1971 "Invalid" 1970 "Invalid" 1969 "Invalid" 1968 "Invalid" 1967 "Invalid" 1966 "Invalid" 1965 "Invalid" 1964 "Invalid" 1963 "Invalid" 1962 "Invalid" 1961 "Invalid" 1960 "Invalid" 1959 "Invalid" 1958 "Invalid" 1957 "Invalid" 1956 "Invalid" 1955 "Invalid" 1954 "Invalid" 1953 "Invalid" 1952 "Invalid" 1951 "Invalid" 1950 "Invalid" 1949 "Invalid" 1948 "Invalid" 1947 "Invalid" 1946 "Invalid" 1945 "Invalid" 1944 "Invalid" 1943 "Invalid" 1942 "Invalid" 1941 "Invalid" 1940 "Invalid" 1939 "Invalid" 1938 "Invalid" 1937 "Invalid" 1936 "Invalid" 1935 "Invalid" 1934 "Invalid" 1933 "Invalid" 1932 "Invalid" 1931 "Invalid" 1930 "Invalid" 1929 "Invalid" 1928 "Invalid" 1927 "Invalid" 1926 "Invalid" 1925 "Invalid" 1924 "Invalid" 1923 "Invalid" 1922 "Invalid" 1921 "Invalid" 1920 "Invalid" 1919 "Invalid" 1918 "Invalid" 1917 "Invalid" 1916 "Invalid" 1915 "Invalid" 1914 "Invalid" 1913 "Invalid" 1912 "Invalid" 1911 "Invalid" 1910 "Invalid" 1909 "Invalid" 1908 "Invalid" 1907 "Invalid" 1906 "Invalid" 1905 "Invalid" 1904 "Invalid" 1903 "Invalid" 1902 "Invalid" 1901 "Invalid" 1900 "Invalid" 1899 "Invalid" 1898 "Invalid" 1897 "Invalid" 1896 "Invalid" 1895 "Invalid" 1894 "Invalid" 1893 "Invalid" 1892 "Invalid" 1891 "Invalid" 1890 "Invalid" 1889 "Invalid" 1888 "Invalid" 1887 "Invalid" 1886 "Invalid" 1885 "Invalid" 1884 "Invalid" 1883 "Invalid" 1882 "Invalid" 1881 "Invalid" 1880 "Invalid" 1879 "Invalid" 1878 "Invalid" 1877 "Invalid" 1876 "Invalid" 1875 "Invalid" 1874 "Invalid" 1873 "Invalid" 1872 "Invalid" 1871 "Invalid" 1870 "Invalid" 1869 "Invalid" 1868 "Invalid" 1867 "Invalid" 1866 "Invalid" 1865 "Invalid" 1864 "Invalid" 1863 "Invalid" 1862 "Invalid" 1861 "Invalid" 1860 "Invalid" 1859 "Invalid" 1858 "Invalid" 1857 "Invalid" 1856 "Invalid" 1855 "Invalid" 1854 "Invalid" 1853 "Invalid" 1852 "Invalid" 1851 "Invalid" 1850 "Invalid" 1849 "Invalid" 1848 "Invalid" 1847 "Invalid" 1846 "Invalid" 1845 "Invalid" 1844 "Invalid" 1843 "Invalid" 1842 "Invalid" 1841 "Invalid" 1840 "Invalid" 1839 "Invalid" 1838 "Invalid" 1837 "Invalid" 1836 "Invalid" 1835 "Invalid" 1834 "Invalid" 1833 "Invalid" 1832 "Invalid" 1831 "Invalid" 1830 "Invalid" 1829 "Invalid" 1828 "Invalid" 1827 "Invalid" 1826 "Invalid" 1825 "Invalid" 1824 "Invalid" 1823 "Invalid" 1822 "Invalid" 1821 "Invalid" 1820 "Invalid" 1819 "Invalid" 1818 "Invalid" 1817 "Invalid" 1816 "Invalid" 1815 "Invalid" 1814 "Invalid" 1813 "Invalid" 1812 "Invalid" 1811 "Invalid" 1810 "Invalid" 1809 "Invalid" 1808 "Invalid" 1807 "Invalid" 1806 "Invalid" 1805 "Invalid" 1804 "Invalid" 1803 "Invalid" 1802 "Invalid" 1801 "Invalid" ;
VAL_ 558 BCU_CellVlt057_RM 2047 "Invalid" 2046 "Invalid" 2045 "Invalid" 2044 "Invalid" 2043 "Invalid" 2042 "Invalid" 2041 "Invalid" 2040 "Invalid" 2039 "Invalid" 2038 "Invalid" 2037 "Invalid" 2036 "Invalid" 2035 "Invalid" 2034 "Invalid" 2033 "Invalid" 2032 "Invalid" 2031 "Invalid" 2030 "Invalid" 2029 "Invalid" 2028 "Invalid" 2027 "Invalid" 2026 "Invalid" 2025 "Invalid" 2024 "Invalid" 2023 "Invalid" 2022 "Invalid" 2021 "Invalid" 2020 "Invalid" 2019 "Invalid" 2018 "Invalid" 2017 "Invalid" 2016 "Invalid" 2015 "Invalid" 2014 "Invalid" 2013 "Invalid" 2012 "Invalid" 2011 "Invalid" 2010 "Invalid" 2009 "Invalid" 2008 "Invalid" 2007 "Invalid" 2006 "Invalid" 2005 "Invalid" 2004 "Invalid" 2003 "Invalid" 2002 "Invalid" 2001 "Invalid" 2000 "Invalid" 1999 "Invalid" 1998 "Invalid" 1997 "Invalid" 1996 "Invalid" 1995 "Invalid" 1994 "Invalid" 1993 "Invalid" 1992 "Invalid" 1991 "Invalid" 1990 "Invalid" 1989 "Invalid" 1988 "Invalid" 1987 "Invalid" 1986 "Invalid" 1985 "Invalid" 1984 "Invalid" 1983 "Invalid" 1982 "Invalid" 1981 "Invalid" 1980 "Invalid" 1979 "Invalid" 1978 "Invalid" 1977 "Invalid" 1976 "Invalid" 1975 "Invalid" 1974 "Invalid" 1973 "Invalid" 1972 "Invalid" 1971 "Invalid" 1970 "Invalid" 1969 "Invalid" 1968 "Invalid" 1967 "Invalid" 1966 "Invalid" 1965 "Invalid" 1964 "Invalid" 1963 "Invalid" 1962 "Invalid" 1961 "Invalid" 1960 "Invalid" 1959 "Invalid" 1958 "Invalid" 1957 "Invalid" 1956 "Invalid" 1955 "Invalid" 1954 "Invalid" 1953 "Invalid" 1952 "Invalid" 1951 "Invalid" 1950 "Invalid" 1949 "Invalid" 1948 "Invalid" 1947 "Invalid" 1946 "Invalid" 1945 "Invalid" 1944 "Invalid" 1943 "Invalid" 1942 "Invalid" 1941 "Invalid" 1940 "Invalid" 1939 "Invalid" 1938 "Invalid" 1937 "Invalid" 1936 "Invalid" 1935 "Invalid" 1934 "Invalid" 1933 "Invalid" 1932 "Invalid" 1931 "Invalid" 1930 "Invalid" 1929 "Invalid" 1928 "Invalid" 1927 "Invalid" 1926 "Invalid" 1925 "Invalid" 1924 "Invalid" 1923 "Invalid" 1922 "Invalid" 1921 "Invalid" 1920 "Invalid" 1919 "Invalid" 1918 "Invalid" 1917 "Invalid" 1916 "Invalid" 1915 "Invalid" 1914 "Invalid" 1913 "Invalid" 1912 "Invalid" 1911 "Invalid" 1910 "Invalid" 1909 "Invalid" 1908 "Invalid" 1907 "Invalid" 1906 "Invalid" 1905 "Invalid" 1904 "Invalid" 1903 "Invalid" 1902 "Invalid" 1901 "Invalid" 1900 "Invalid" 1899 "Invalid" 1898 "Invalid" 1897 "Invalid" 1896 "Invalid" 1895 "Invalid" 1894 "Invalid" 1893 "Invalid" 1892 "Invalid" 1891 "Invalid" 1890 "Invalid" 1889 "Invalid" 1888 "Invalid" 1887 "Invalid" 1886 "Invalid" 1885 "Invalid" 1884 "Invalid" 1883 "Invalid" 1882 "Invalid" 1881 "Invalid" 1880 "Invalid" 1879 "Invalid" 1878 "Invalid" 1877 "Invalid" 1876 "Invalid" 1875 "Invalid" 1874 "Invalid" 1873 "Invalid" 1872 "Invalid" 1871 "Invalid" 1870 "Invalid" 1869 "Invalid" 1868 "Invalid" 1867 "Invalid" 1866 "Invalid" 1865 "Invalid" 1864 "Invalid" 1863 "Invalid" 1862 "Invalid" 1861 "Invalid" 1860 "Invalid" 1859 "Invalid" 1858 "Invalid" 1857 "Invalid" 1856 "Invalid" 1855 "Invalid" 1854 "Invalid" 1853 "Invalid" 1852 "Invalid" 1851 "Invalid" 1850 "Invalid" 1849 "Invalid" 1848 "Invalid" 1847 "Invalid" 1846 "Invalid" 1845 "Invalid" 1844 "Invalid" 1843 "Invalid" 1842 "Invalid" 1841 "Invalid" 1840 "Invalid" 1839 "Invalid" 1838 "Invalid" 1837 "Invalid" 1836 "Invalid" 1835 "Invalid" 1834 "Invalid" 1833 "Invalid" 1832 "Invalid" 1831 "Invalid" 1830 "Invalid" 1829 "Invalid" 1828 "Invalid" 1827 "Invalid" 1826 "Invalid" 1825 "Invalid" 1824 "Invalid" 1823 "Invalid" 1822 "Invalid" 1821 "Invalid" 1820 "Invalid" 1819 "Invalid" 1818 "Invalid" 1817 "Invalid" 1816 "Invalid" 1815 "Invalid" 1814 "Invalid" 1813 "Invalid" 1812 "Invalid" 1811 "Invalid" 1810 "Invalid" 1809 "Invalid" 1808 "Invalid" 1807 "Invalid" 1806 "Invalid" 1805 "Invalid" 1804 "Invalid" 1803 "Invalid" 1802 "Invalid" 1801 "Invalid" ;
VAL_ 558 BCU_CellVlt058_RM 2047 "Invalid" 2046 "Invalid" 2045 "Invalid" 2044 "Invalid" 2043 "Invalid" 2042 "Invalid" 2041 "Invalid" 2040 "Invalid" 2039 "Invalid" 2038 "Invalid" 2037 "Invalid" 2036 "Invalid" 2035 "Invalid" 2034 "Invalid" 2033 "Invalid" 2032 "Invalid" 2031 "Invalid" 2030 "Invalid" 2029 "Invalid" 2028 "Invalid" 2027 "Invalid" 2026 "Invalid" 2025 "Invalid" 2024 "Invalid" 2023 "Invalid" 2022 "Invalid" 2021 "Invalid" 2020 "Invalid" 2019 "Invalid" 2018 "Invalid" 2017 "Invalid" 2016 "Invalid" 2015 "Invalid" 2014 "Invalid" 2013 "Invalid" 2012 "Invalid" 2011 "Invalid" 2010 "Invalid" 2009 "Invalid" 2008 "Invalid" 2007 "Invalid" 2006 "Invalid" 2005 "Invalid" 2004 "Invalid" 2003 "Invalid" 2002 "Invalid" 2001 "Invalid" 2000 "Invalid" 1999 "Invalid" 1998 "Invalid" 1997 "Invalid" 1996 "Invalid" 1995 "Invalid" 1994 "Invalid" 1993 "Invalid" 1992 "Invalid" 1991 "Invalid" 1990 "Invalid" 1989 "Invalid" 1988 "Invalid" 1987 "Invalid" 1986 "Invalid" 1985 "Invalid" 1984 "Invalid" 1983 "Invalid" 1982 "Invalid" 1981 "Invalid" 1980 "Invalid" 1979 "Invalid" 1978 "Invalid" 1977 "Invalid" 1976 "Invalid" 1975 "Invalid" 1974 "Invalid" 1973 "Invalid" 1972 "Invalid" 1971 "Invalid" 1970 "Invalid" 1969 "Invalid" 1968 "Invalid" 1967 "Invalid" 1966 "Invalid" 1965 "Invalid" 1964 "Invalid" 1963 "Invalid" 1962 "Invalid" 1961 "Invalid" 1960 "Invalid" 1959 "Invalid" 1958 "Invalid" 1957 "Invalid" 1956 "Invalid" 1955 "Invalid" 1954 "Invalid" 1953 "Invalid" 1952 "Invalid" 1951 "Invalid" 1950 "Invalid" 1949 "Invalid" 1948 "Invalid" 1947 "Invalid" 1946 "Invalid" 1945 "Invalid" 1944 "Invalid" 1943 "Invalid" 1942 "Invalid" 1941 "Invalid" 1940 "Invalid" 1939 "Invalid" 1938 "Invalid" 1937 "Invalid" 1936 "Invalid" 1935 "Invalid" 1934 "Invalid" 1933 "Invalid" 1932 "Invalid" 1931 "Invalid" 1930 "Invalid" 1929 "Invalid" 1928 "Invalid" 1927 "Invalid" 1926 "Invalid" 1925 "Invalid" 1924 "Invalid" 1923 "Invalid" 1922 "Invalid" 1921 "Invalid" 1920 "Invalid" 1919 "Invalid" 1918 "Invalid" 1917 "Invalid" 1916 "Invalid" 1915 "Invalid" 1914 "Invalid" 1913 "Invalid" 1912 "Invalid" 1911 "Invalid" 1910 "Invalid" 1909 "Invalid" 1908 "Invalid" 1907 "Invalid" 1906 "Invalid" 1905 "Invalid" 1904 "Invalid" 1903 "Invalid" 1902 "Invalid" 1901 "Invalid" 1900 "Invalid" 1899 "Invalid" 1898 "Invalid" 1897 "Invalid" 1896 "Invalid" 1895 "Invalid" 1894 "Invalid" 1893 "Invalid" 1892 "Invalid" 1891 "Invalid" 1890 "Invalid" 1889 "Invalid" 1888 "Invalid" 1887 "Invalid" 1886 "Invalid" 1885 "Invalid" 1884 "Invalid" 1883 "Invalid" 1882 "Invalid" 1881 "Invalid" 1880 "Invalid" 1879 "Invalid" 1878 "Invalid" 1877 "Invalid" 1876 "Invalid" 1875 "Invalid" 1874 "Invalid" 1873 "Invalid" 1872 "Invalid" 1871 "Invalid" 1870 "Invalid" 1869 "Invalid" 1868 "Invalid" 1867 "Invalid" 1866 "Invalid" 1865 "Invalid" 1864 "Invalid" 1863 "Invalid" 1862 "Invalid" 1861 "Invalid" 1860 "Invalid" 1859 "Invalid" 1858 "Invalid" 1857 "Invalid" 1856 "Invalid" 1855 "Invalid" 1854 "Invalid" 1853 "Invalid" 1852 "Invalid" 1851 "Invalid" 1850 "Invalid" 1849 "Invalid" 1848 "Invalid" 1847 "Invalid" 1846 "Invalid" 1845 "Invalid" 1844 "Invalid" 1843 "Invalid" 1842 "Invalid" 1841 "Invalid" 1840 "Invalid" 1839 "Invalid" 1838 "Invalid" 1837 "Invalid" 1836 "Invalid" 1835 "Invalid" 1834 "Invalid" 1833 "Invalid" 1832 "Invalid" 1831 "Invalid" 1830 "Invalid" 1829 "Invalid" 1828 "Invalid" 1827 "Invalid" 1826 "Invalid" 1825 "Invalid" 1824 "Invalid" 1823 "Invalid" 1822 "Invalid" 1821 "Invalid" 1820 "Invalid" 1819 "Invalid" 1818 "Invalid" 1817 "Invalid" 1816 "Invalid" 1815 "Invalid" 1814 "Invalid" 1813 "Invalid" 1812 "Invalid" 1811 "Invalid" 1810 "Invalid" 1809 "Invalid" 1808 "Invalid" 1807 "Invalid" 1806 "Invalid" 1805 "Invalid" 1804 "Invalid" 1803 "Invalid" 1802 "Invalid" 1801 "Invalid" ;
VAL_ 558 BCU_CellVlt059_RM 2047 "Invalid" 2046 "Invalid" 2045 "Invalid" 2044 "Invalid" 2043 "Invalid" 2042 "Invalid" 2041 "Invalid" 2040 "Invalid" 2039 "Invalid" 2038 "Invalid" 2037 "Invalid" 2036 "Invalid" 2035 "Invalid" 2034 "Invalid" 2033 "Invalid" 2032 "Invalid" 2031 "Invalid" 2030 "Invalid" 2029 "Invalid" 2028 "Invalid" 2027 "Invalid" 2026 "Invalid" 2025 "Invalid" 2024 "Invalid" 2023 "Invalid" 2022 "Invalid" 2021 "Invalid" 2020 "Invalid" 2019 "Invalid" 2018 "Invalid" 2017 "Invalid" 2016 "Invalid" 2015 "Invalid" 2014 "Invalid" 2013 "Invalid" 2012 "Invalid" 2011 "Invalid" 2010 "Invalid" 2009 "Invalid" 2008 "Invalid" 2007 "Invalid" 2006 "Invalid" 2005 "Invalid" 2004 "Invalid" 2003 "Invalid" 2002 "Invalid" 2001 "Invalid" 2000 "Invalid" 1999 "Invalid" 1998 "Invalid" 1997 "Invalid" 1996 "Invalid" 1995 "Invalid" 1994 "Invalid" 1993 "Invalid" 1992 "Invalid" 1991 "Invalid" 1990 "Invalid" 1989 "Invalid" 1988 "Invalid" 1987 "Invalid" 1986 "Invalid" 1985 "Invalid" 1984 "Invalid" 1983 "Invalid" 1982 "Invalid" 1981 "Invalid" 1980 "Invalid" 1979 "Invalid" 1978 "Invalid" 1977 "Invalid" 1976 "Invalid" 1975 "Invalid" 1974 "Invalid" 1973 "Invalid" 1972 "Invalid" 1971 "Invalid" 1970 "Invalid" 1969 "Invalid" 1968 "Invalid" 1967 "Invalid" 1966 "Invalid" 1965 "Invalid" 1964 "Invalid" 1963 "Invalid" 1962 "Invalid" 1961 "Invalid" 1960 "Invalid" 1959 "Invalid" 1958 "Invalid" 1957 "Invalid" 1956 "Invalid" 1955 "Invalid" 1954 "Invalid" 1953 "Invalid" 1952 "Invalid" 1951 "Invalid" 1950 "Invalid" 1949 "Invalid" 1948 "Invalid" 1947 "Invalid" 1946 "Invalid" 1945 "Invalid" 1944 "Invalid" 1943 "Invalid" 1942 "Invalid" 1941 "Invalid" 1940 "Invalid" 1939 "Invalid" 1938 "Invalid" 1937 "Invalid" 1936 "Invalid" 1935 "Invalid" 1934 "Invalid" 1933 "Invalid" 1932 "Invalid" 1931 "Invalid" 1930 "Invalid" 1929 "Invalid" 1928 "Invalid" 1927 "Invalid" 1926 "Invalid" 1925 "Invalid" 1924 "Invalid" 1923 "Invalid" 1922 "Invalid" 1921 "Invalid" 1920 "Invalid" 1919 "Invalid" 1918 "Invalid" 1917 "Invalid" 1916 "Invalid" 1915 "Invalid" 1914 "Invalid" 1913 "Invalid" 1912 "Invalid" 1911 "Invalid" 1910 "Invalid" 1909 "Invalid" 1908 "Invalid" 1907 "Invalid" 1906 "Invalid" 1905 "Invalid" 1904 "Invalid" 1903 "Invalid" 1902 "Invalid" 1901 "Invalid" 1900 "Invalid" 1899 "Invalid" 1898 "Invalid" 1897 "Invalid" 1896 "Invalid" 1895 "Invalid" 1894 "Invalid" 1893 "Invalid" 1892 "Invalid" 1891 "Invalid" 1890 "Invalid" 1889 "Invalid" 1888 "Invalid" 1887 "Invalid" 1886 "Invalid" 1885 "Invalid" 1884 "Invalid" 1883 "Invalid" 1882 "Invalid" 1881 "Invalid" 1880 "Invalid" 1879 "Invalid" 1878 "Invalid" 1877 "Invalid" 1876 "Invalid" 1875 "Invalid" 1874 "Invalid" 1873 "Invalid" 1872 "Invalid" 1871 "Invalid" 1870 "Invalid" 1869 "Invalid" 1868 "Invalid" 1867 "Invalid" 1866 "Invalid" 1865 "Invalid" 1864 "Invalid" 1863 "Invalid" 1862 "Invalid" 1861 "Invalid" 1860 "Invalid" 1859 "Invalid" 1858 "Invalid" 1857 "Invalid" 1856 "Invalid" 1855 "Invalid" 1854 "Invalid" 1853 "Invalid" 1852 "Invalid" 1851 "Invalid" 1850 "Invalid" 1849 "Invalid" 1848 "Invalid" 1847 "Invalid" 1846 "Invalid" 1845 "Invalid" 1844 "Invalid" 1843 "Invalid" 1842 "Invalid" 1841 "Invalid" 1840 "Invalid" 1839 "Invalid" 1838 "Invalid" 1837 "Invalid" 1836 "Invalid" 1835 "Invalid" 1834 "Invalid" 1833 "Invalid" 1832 "Invalid" 1831 "Invalid" 1830 "Invalid" 1829 "Invalid" 1828 "Invalid" 1827 "Invalid" 1826 "Invalid" 1825 "Invalid" 1824 "Invalid" 1823 "Invalid" 1822 "Invalid" 1821 "Invalid" 1820 "Invalid" 1819 "Invalid" 1818 "Invalid" 1817 "Invalid" 1816 "Invalid" 1815 "Invalid" 1814 "Invalid" 1813 "Invalid" 1812 "Invalid" 1811 "Invalid" 1810 "Invalid" 1809 "Invalid" 1808 "Invalid" 1807 "Invalid" 1806 "Invalid" 1805 "Invalid" 1804 "Invalid" 1803 "Invalid" 1802 "Invalid" 1801 "Invalid" ;
VAL_ 558 BCU_CellVlt060_RM 2047 "Invalid" 2046 "Invalid" 2045 "Invalid" 2044 "Invalid" 2043 "Invalid" 2042 "Invalid" 2041 "Invalid" 2040 "Invalid" 2039 "Invalid" 2038 "Invalid" 2037 "Invalid" 2036 "Invalid" 2035 "Invalid" 2034 "Invalid" 2033 "Invalid" 2032 "Invalid" 2031 "Invalid" 2030 "Invalid" 2029 "Invalid" 2028 "Invalid" 2027 "Invalid" 2026 "Invalid" 2025 "Invalid" 2024 "Invalid" 2023 "Invalid" 2022 "Invalid" 2021 "Invalid" 2020 "Invalid" 2019 "Invalid" 2018 "Invalid" 2017 "Invalid" 2016 "Invalid" 2015 "Invalid" 2014 "Invalid" 2013 "Invalid" 2012 "Invalid" 2011 "Invalid" 2010 "Invalid" 2009 "Invalid" 2008 "Invalid" 2007 "Invalid" 2006 "Invalid" 2005 "Invalid" 2004 "Invalid" 2003 "Invalid" 2002 "Invalid" 2001 "Invalid" 2000 "Invalid" 1999 "Invalid" 1998 "Invalid" 1997 "Invalid" 1996 "Invalid" 1995 "Invalid" 1994 "Invalid" 1993 "Invalid" 1992 "Invalid" 1991 "Invalid" 1990 "Invalid" 1989 "Invalid" 1988 "Invalid" 1987 "Invalid" 1986 "Invalid" 1985 "Invalid" 1984 "Invalid" 1983 "Invalid" 1982 "Invalid" 1981 "Invalid" 1980 "Invalid" 1979 "Invalid" 1978 "Invalid" 1977 "Invalid" 1976 "Invalid" 1975 "Invalid" 1974 "Invalid" 1973 "Invalid" 1972 "Invalid" 1971 "Invalid" 1970 "Invalid" 1969 "Invalid" 1968 "Invalid" 1967 "Invalid" 1966 "Invalid" 1965 "Invalid" 1964 "Invalid" 1963 "Invalid" 1962 "Invalid" 1961 "Invalid" 1960 "Invalid" 1959 "Invalid" 1958 "Invalid" 1957 "Invalid" 1956 "Invalid" 1955 "Invalid" 1954 "Invalid" 1953 "Invalid" 1952 "Invalid" 1951 "Invalid" 1950 "Invalid" 1949 "Invalid" 1948 "Invalid" 1947 "Invalid" 1946 "Invalid" 1945 "Invalid" 1944 "Invalid" 1943 "Invalid" 1942 "Invalid" 1941 "Invalid" 1940 "Invalid" 1939 "Invalid" 1938 "Invalid" 1937 "Invalid" 1936 "Invalid" 1935 "Invalid" 1934 "Invalid" 1933 "Invalid" 1932 "Invalid" 1931 "Invalid" 1930 "Invalid" 1929 "Invalid" 1928 "Invalid" 1927 "Invalid" 1926 "Invalid" 1925 "Invalid" 1924 "Invalid" 1923 "Invalid" 1922 "Invalid" 1921 "Invalid" 1920 "Invalid" 1919 "Invalid" 1918 "Invalid" 1917 "Invalid" 1916 "Invalid" 1915 "Invalid" 1914 "Invalid" 1913 "Invalid" 1912 "Invalid" 1911 "Invalid" 1910 "Invalid" 1909 "Invalid" 1908 "Invalid" 1907 "Invalid" 1906 "Invalid" 1905 "Invalid" 1904 "Invalid" 1903 "Invalid" 1902 "Invalid" 1901 "Invalid" 1900 "Invalid" 1899 "Invalid" 1898 "Invalid" 1897 "Invalid" 1896 "Invalid" 1895 "Invalid" 1894 "Invalid" 1893 "Invalid" 1892 "Invalid" 1891 "Invalid" 1890 "Invalid" 1889 "Invalid" 1888 "Invalid" 1887 "Invalid" 1886 "Invalid" 1885 "Invalid" 1884 "Invalid" 1883 "Invalid" 1882 "Invalid" 1881 "Invalid" 1880 "Invalid" 1879 "Invalid" 1878 "Invalid" 1877 "Invalid" 1876 "Invalid" 1875 "Invalid" 1874 "Invalid" 1873 "Invalid" 1872 "Invalid" 1871 "Invalid" 1870 "Invalid" 1869 "Invalid" 1868 "Invalid" 1867 "Invalid" 1866 "Invalid" 1865 "Invalid" 1864 "Invalid" 1863 "Invalid" 1862 "Invalid" 1861 "Invalid" 1860 "Invalid" 1859 "Invalid" 1858 "Invalid" 1857 "Invalid" 1856 "Invalid" 1855 "Invalid" 1854 "Invalid" 1853 "Invalid" 1852 "Invalid" 1851 "Invalid" 1850 "Invalid" 1849 "Invalid" 1848 "Invalid" 1847 "Invalid" 1846 "Invalid" 1845 "Invalid" 1844 "Invalid" 1843 "Invalid" 1842 "Invalid" 1841 "Invalid" 1840 "Invalid" 1839 "Invalid" 1838 "Invalid" 1837 "Invalid" 1836 "Invalid" 1835 "Invalid" 1834 "Invalid" 1833 "Invalid" 1832 "Invalid" 1831 "Invalid" 1830 "Invalid" 1829 "Invalid" 1828 "Invalid" 1827 "Invalid" 1826 "Invalid" 1825 "Invalid" 1824 "Invalid" 1823 "Invalid" 1822 "Invalid" 1821 "Invalid" 1820 "Invalid" 1819 "Invalid" 1818 "Invalid" 1817 "Invalid" 1816 "Invalid" 1815 "Invalid" 1814 "Invalid" 1813 "Invalid" 1812 "Invalid" 1811 "Invalid" 1810 "Invalid" 1809 "Invalid" 1808 "Invalid" 1807 "Invalid" 1806 "Invalid" 1805 "Invalid" 1804 "Invalid" 1803 "Invalid" 1802 "Invalid" 1801 "Invalid" ;
VAL_ 558 BCU_CellTmp012_RM 255 "Invalid" 254 "Invalid" 253 "Invalid" 252 "Invalid" 251 "Invalid" 250 "Invalid" 249 "Invalid" 248 "Invalid" 247 "Invalid" 246 "Invalid" 245 "Invalid" 244 "Invalid" 243 "Invalid" 242 "Invalid" 241 "Invalid" 240 "Invalid" 239 "Invalid" 238 "Invalid" 237 "Invalid" 236 "Invalid" 235 "Invalid" 234 "Invalid" 233 "Invalid" 232 "Invalid" 231 "Invalid" 230 "Invalid" 229 "Invalid" 228 "Invalid" 227 "Invalid" 226 "Invalid" 225 "Invalid" 224 "Invalid" 223 "Invalid" 222 "Invalid" 221 "Invalid" 220 "Invalid" 219 "Invalid" 218 "Invalid" 217 "Invalid" 216 "Invalid" 215 "Invalid" 214 "Invalid" 213 "Invalid" 212 "Invalid" 211 "Invalid" 210 "Invalid" 209 "Invalid" 208 "Invalid" 207 "Invalid" 206 "Invalid" 205 "Invalid" 204 "Invalid" 203 "Invalid" 202 "Invalid" 201 "Invalid" 200 "Invalid" 199 "Invalid" 198 "Invalid" 197 "Invalid" 196 "Invalid" 195 "Invalid" 194 "Invalid" 193 "Invalid" 192 "Invalid" 191 "Invalid" 190 "Invalid" 189 "Invalid" 188 "Invalid" 187 "Invalid" 186 "Invalid" 185 "Invalid" 184 "Invalid" 183 "Invalid" 182 "Invalid" 181 "Invalid" 180 "Invalid" 179 "Invalid" 178 "Invalid" 177 "Invalid" 176 "Invalid" 175 "Invalid" 174 "Invalid" 173 "Invalid" 172 "Invalid" 171 "Invalid" 170 "Invalid" 169 "Invalid" 168 "Invalid" 167 "Invalid" 166 "Invalid" 165 "Invalid" 164 "Invalid" 163 "Invalid" 162 "Invalid" 161 "Invalid" ;
VAL_ 559 BCU_CellVlt061_RM 2047 "Invalid" 2046 "Invalid" 2045 "Invalid" 2044 "Invalid" 2043 "Invalid" 2042 "Invalid" 2041 "Invalid" 2040 "Invalid" 2039 "Invalid" 2038 "Invalid" 2037 "Invalid" 2036 "Invalid" 2035 "Invalid" 2034 "Invalid" 2033 "Invalid" 2032 "Invalid" 2031 "Invalid" 2030 "Invalid" 2029 "Invalid" 2028 "Invalid" 2027 "Invalid" 2026 "Invalid" 2025 "Invalid" 2024 "Invalid" 2023 "Invalid" 2022 "Invalid" 2021 "Invalid" 2020 "Invalid" 2019 "Invalid" 2018 "Invalid" 2017 "Invalid" 2016 "Invalid" 2015 "Invalid" 2014 "Invalid" 2013 "Invalid" 2012 "Invalid" 2011 "Invalid" 2010 "Invalid" 2009 "Invalid" 2008 "Invalid" 2007 "Invalid" 2006 "Invalid" 2005 "Invalid" 2004 "Invalid" 2003 "Invalid" 2002 "Invalid" 2001 "Invalid" 2000 "Invalid" 1999 "Invalid" 1998 "Invalid" 1997 "Invalid" 1996 "Invalid" 1995 "Invalid" 1994 "Invalid" 1993 "Invalid" 1992 "Invalid" 1991 "Invalid" 1990 "Invalid" 1989 "Invalid" 1988 "Invalid" 1987 "Invalid" 1986 "Invalid" 1985 "Invalid" 1984 "Invalid" 1983 "Invalid" 1982 "Invalid" 1981 "Invalid" 1980 "Invalid" 1979 "Invalid" 1978 "Invalid" 1977 "Invalid" 1976 "Invalid" 1975 "Invalid" 1974 "Invalid" 1973 "Invalid" 1972 "Invalid" 1971 "Invalid" 1970 "Invalid" 1969 "Invalid" 1968 "Invalid" 1967 "Invalid" 1966 "Invalid" 1965 "Invalid" 1964 "Invalid" 1963 "Invalid" 1962 "Invalid" 1961 "Invalid" 1960 "Invalid" 1959 "Invalid" 1958 "Invalid" 1957 "Invalid" 1956 "Invalid" 1955 "Invalid" 1954 "Invalid" 1953 "Invalid" 1952 "Invalid" 1951 "Invalid" 1950 "Invalid" 1949 "Invalid" 1948 "Invalid" 1947 "Invalid" 1946 "Invalid" 1945 "Invalid" 1944 "Invalid" 1943 "Invalid" 1942 "Invalid" 1941 "Invalid" 1940 "Invalid" 1939 "Invalid" 1938 "Invalid" 1937 "Invalid" 1936 "Invalid" 1935 "Invalid" 1934 "Invalid" 1933 "Invalid" 1932 "Invalid" 1931 "Invalid" 1930 "Invalid" 1929 "Invalid" 1928 "Invalid" 1927 "Invalid" 1926 "Invalid" 1925 "Invalid" 1924 "Invalid" 1923 "Invalid" 1922 "Invalid" 1921 "Invalid" 1920 "Invalid" 1919 "Invalid" 1918 "Invalid" 1917 "Invalid" 1916 "Invalid" 1915 "Invalid" 1914 "Invalid" 1913 "Invalid" 1912 "Invalid" 1911 "Invalid" 1910 "Invalid" 1909 "Invalid" 1908 "Invalid" 1907 "Invalid" 1906 "Invalid" 1905 "Invalid" 1904 "Invalid" 1903 "Invalid" 1902 "Invalid" 1901 "Invalid" 1900 "Invalid" 1899 "Invalid" 1898 "Invalid" 1897 "Invalid" 1896 "Invalid" 1895 "Invalid" 1894 "Invalid" 1893 "Invalid" 1892 "Invalid" 1891 "Invalid" 1890 "Invalid" 1889 "Invalid" 1888 "Invalid" 1887 "Invalid" 1886 "Invalid" 1885 "Invalid" 1884 "Invalid" 1883 "Invalid" 1882 "Invalid" 1881 "Invalid" 1880 "Invalid" 1879 "Invalid" 1878 "Invalid" 1877 "Invalid" 1876 "Invalid" 1875 "Invalid" 1874 "Invalid" 1873 "Invalid" 1872 "Invalid" 1871 "Invalid" 1870 "Invalid" 1869 "Invalid" 1868 "Invalid" 1867 "Invalid" 1866 "Invalid" 1865 "Invalid" 1864 "Invalid" 1863 "Invalid" 1862 "Invalid" 1861 "Invalid" 1860 "Invalid" 1859 "Invalid" 1858 "Invalid" 1857 "Invalid" 1856 "Invalid" 1855 "Invalid" 1854 "Invalid" 1853 "Invalid" 1852 "Invalid" 1851 "Invalid" 1850 "Invalid" 1849 "Invalid" 1848 "Invalid" 1847 "Invalid" 1846 "Invalid" 1845 "Invalid" 1844 "Invalid" 1843 "Invalid" 1842 "Invalid" 1841 "Invalid" 1840 "Invalid" 1839 "Invalid" 1838 "Invalid" 1837 "Invalid" 1836 "Invalid" 1835 "Invalid" 1834 "Invalid" 1833 "Invalid" 1832 "Invalid" 1831 "Invalid" 1830 "Invalid" 1829 "Invalid" 1828 "Invalid" 1827 "Invalid" 1826 "Invalid" 1825 "Invalid" 1824 "Invalid" 1823 "Invalid" 1822 "Invalid" 1821 "Invalid" 1820 "Invalid" 1819 "Invalid" 1818 "Invalid" 1817 "Invalid" 1816 "Invalid" 1815 "Invalid" 1814 "Invalid" 1813 "Invalid" 1812 "Invalid" 1811 "Invalid" 1810 "Invalid" 1809 "Invalid" 1808 "Invalid" 1807 "Invalid" 1806 "Invalid" 1805 "Invalid" 1804 "Invalid" 1803 "Invalid" 1802 "Invalid" 1801 "Invalid" ;
VAL_ 559 BCU_CellVlt062_RM 2047 "Invalid" 2046 "Invalid" 2045 "Invalid" 2044 "Invalid" 2043 "Invalid" 2042 "Invalid" 2041 "Invalid" 2040 "Invalid" 2039 "Invalid" 2038 "Invalid" 2037 "Invalid" 2036 "Invalid" 2035 "Invalid" 2034 "Invalid" 2033 "Invalid" 2032 "Invalid" 2031 "Invalid" 2030 "Invalid" 2029 "Invalid" 2028 "Invalid" 2027 "Invalid" 2026 "Invalid" 2025 "Invalid" 2024 "Invalid" 2023 "Invalid" 2022 "Invalid" 2021 "Invalid" 2020 "Invalid" 2019 "Invalid" 2018 "Invalid" 2017 "Invalid" 2016 "Invalid" 2015 "Invalid" 2014 "Invalid" 2013 "Invalid" 2012 "Invalid" 2011 "Invalid" 2010 "Invalid" 2009 "Invalid" 2008 "Invalid" 2007 "Invalid" 2006 "Invalid" 2005 "Invalid" 2004 "Invalid" 2003 "Invalid" 2002 "Invalid" 2001 "Invalid" 2000 "Invalid" 1999 "Invalid" 1998 "Invalid" 1997 "Invalid" 1996 "Invalid" 1995 "Invalid" 1994 "Invalid" 1993 "Invalid" 1992 "Invalid" 1991 "Invalid" 1990 "Invalid" 1989 "Invalid" 1988 "Invalid" 1987 "Invalid" 1986 "Invalid" 1985 "Invalid" 1984 "Invalid" 1983 "Invalid" 1982 "Invalid" 1981 "Invalid" 1980 "Invalid" 1979 "Invalid" 1978 "Invalid" 1977 "Invalid" 1976 "Invalid" 1975 "Invalid" 1974 "Invalid" 1973 "Invalid" 1972 "Invalid" 1971 "Invalid" 1970 "Invalid" 1969 "Invalid" 1968 "Invalid" 1967 "Invalid" 1966 "Invalid" 1965 "Invalid" 1964 "Invalid" 1963 "Invalid" 1962 "Invalid" 1961 "Invalid" 1960 "Invalid" 1959 "Invalid" 1958 "Invalid" 1957 "Invalid" 1956 "Invalid" 1955 "Invalid" 1954 "Invalid" 1953 "Invalid" 1952 "Invalid" 1951 "Invalid" 1950 "Invalid" 1949 "Invalid" 1948 "Invalid" 1947 "Invalid" 1946 "Invalid" 1945 "Invalid" 1944 "Invalid" 1943 "Invalid" 1942 "Invalid" 1941 "Invalid" 1940 "Invalid" 1939 "Invalid" 1938 "Invalid" 1937 "Invalid" 1936 "Invalid" 1935 "Invalid" 1934 "Invalid" 1933 "Invalid" 1932 "Invalid" 1931 "Invalid" 1930 "Invalid" 1929 "Invalid" 1928 "Invalid" 1927 "Invalid" 1926 "Invalid" 1925 "Invalid" 1924 "Invalid" 1923 "Invalid" 1922 "Invalid" 1921 "Invalid" 1920 "Invalid" 1919 "Invalid" 1918 "Invalid" 1917 "Invalid" 1916 "Invalid" 1915 "Invalid" 1914 "Invalid" 1913 "Invalid" 1912 "Invalid" 1911 "Invalid" 1910 "Invalid" 1909 "Invalid" 1908 "Invalid" 1907 "Invalid" 1906 "Invalid" 1905 "Invalid" 1904 "Invalid" 1903 "Invalid" 1902 "Invalid" 1901 "Invalid" 1900 "Invalid" 1899 "Invalid" 1898 "Invalid" 1897 "Invalid" 1896 "Invalid" 1895 "Invalid" 1894 "Invalid" 1893 "Invalid" 1892 "Invalid" 1891 "Invalid" 1890 "Invalid" 1889 "Invalid" 1888 "Invalid" 1887 "Invalid" 1886 "Invalid" 1885 "Invalid" 1884 "Invalid" 1883 "Invalid" 1882 "Invalid" 1881 "Invalid" 1880 "Invalid" 1879 "Invalid" 1878 "Invalid" 1877 "Invalid" 1876 "Invalid" 1875 "Invalid" 1874 "Invalid" 1873 "Invalid" 1872 "Invalid" 1871 "Invalid" 1870 "Invalid" 1869 "Invalid" 1868 "Invalid" 1867 "Invalid" 1866 "Invalid" 1865 "Invalid" 1864 "Invalid" 1863 "Invalid" 1862 "Invalid" 1861 "Invalid" 1860 "Invalid" 1859 "Invalid" 1858 "Invalid" 1857 "Invalid" 1856 "Invalid" 1855 "Invalid" 1854 "Invalid" 1853 "Invalid" 1852 "Invalid" 1851 "Invalid" 1850 "Invalid" 1849 "Invalid" 1848 "Invalid" 1847 "Invalid" 1846 "Invalid" 1845 "Invalid" 1844 "Invalid" 1843 "Invalid" 1842 "Invalid" 1841 "Invalid" 1840 "Invalid" 1839 "Invalid" 1838 "Invalid" 1837 "Invalid" 1836 "Invalid" 1835 "Invalid" 1834 "Invalid" 1833 "Invalid" 1832 "Invalid" 1831 "Invalid" 1830 "Invalid" 1829 "Invalid" 1828 "Invalid" 1827 "Invalid" 1826 "Invalid" 1825 "Invalid" 1824 "Invalid" 1823 "Invalid" 1822 "Invalid" 1821 "Invalid" 1820 "Invalid" 1819 "Invalid" 1818 "Invalid" 1817 "Invalid" 1816 "Invalid" 1815 "Invalid" 1814 "Invalid" 1813 "Invalid" 1812 "Invalid" 1811 "Invalid" 1810 "Invalid" 1809 "Invalid" 1808 "Invalid" 1807 "Invalid" 1806 "Invalid" 1805 "Invalid" 1804 "Invalid" 1803 "Invalid" 1802 "Invalid" 1801 "Invalid" ;
VAL_ 559 BCU_CellVlt063_RM 2047 "Invalid" 2046 "Invalid" 2045 "Invalid" 2044 "Invalid" 2043 "Invalid" 2042 "Invalid" 2041 "Invalid" 2040 "Invalid" 2039 "Invalid" 2038 "Invalid" 2037 "Invalid" 2036 "Invalid" 2035 "Invalid" 2034 "Invalid" 2033 "Invalid" 2032 "Invalid" 2031 "Invalid" 2030 "Invalid" 2029 "Invalid" 2028 "Invalid" 2027 "Invalid" 2026 "Invalid" 2025 "Invalid" 2024 "Invalid" 2023 "Invalid" 2022 "Invalid" 2021 "Invalid" 2020 "Invalid" 2019 "Invalid" 2018 "Invalid" 2017 "Invalid" 2016 "Invalid" 2015 "Invalid" 2014 "Invalid" 2013 "Invalid" 2012 "Invalid" 2011 "Invalid" 2010 "Invalid" 2009 "Invalid" 2008 "Invalid" 2007 "Invalid" 2006 "Invalid" 2005 "Invalid" 2004 "Invalid" 2003 "Invalid" 2002 "Invalid" 2001 "Invalid" 2000 "Invalid" 1999 "Invalid" 1998 "Invalid" 1997 "Invalid" 1996 "Invalid" 1995 "Invalid" 1994 "Invalid" 1993 "Invalid" 1992 "Invalid" 1991 "Invalid" 1990 "Invalid" 1989 "Invalid" 1988 "Invalid" 1987 "Invalid" 1986 "Invalid" 1985 "Invalid" 1984 "Invalid" 1983 "Invalid" 1982 "Invalid" 1981 "Invalid" 1980 "Invalid" 1979 "Invalid" 1978 "Invalid" 1977 "Invalid" 1976 "Invalid" 1975 "Invalid" 1974 "Invalid" 1973 "Invalid" 1972 "Invalid" 1971 "Invalid" 1970 "Invalid" 1969 "Invalid" 1968 "Invalid" 1967 "Invalid" 1966 "Invalid" 1965 "Invalid" 1964 "Invalid" 1963 "Invalid" 1962 "Invalid" 1961 "Invalid" 1960 "Invalid" 1959 "Invalid" 1958 "Invalid" 1957 "Invalid" 1956 "Invalid" 1955 "Invalid" 1954 "Invalid" 1953 "Invalid" 1952 "Invalid" 1951 "Invalid" 1950 "Invalid" 1949 "Invalid" 1948 "Invalid" 1947 "Invalid" 1946 "Invalid" 1945 "Invalid" 1944 "Invalid" 1943 "Invalid" 1942 "Invalid" 1941 "Invalid" 1940 "Invalid" 1939 "Invalid" 1938 "Invalid" 1937 "Invalid" 1936 "Invalid" 1935 "Invalid" 1934 "Invalid" 1933 "Invalid" 1932 "Invalid" 1931 "Invalid" 1930 "Invalid" 1929 "Invalid" 1928 "Invalid" 1927 "Invalid" 1926 "Invalid" 1925 "Invalid" 1924 "Invalid" 1923 "Invalid" 1922 "Invalid" 1921 "Invalid" 1920 "Invalid" 1919 "Invalid" 1918 "Invalid" 1917 "Invalid" 1916 "Invalid" 1915 "Invalid" 1914 "Invalid" 1913 "Invalid" 1912 "Invalid" 1911 "Invalid" 1910 "Invalid" 1909 "Invalid" 1908 "Invalid" 1907 "Invalid" 1906 "Invalid" 1905 "Invalid" 1904 "Invalid" 1903 "Invalid" 1902 "Invalid" 1901 "Invalid" 1900 "Invalid" 1899 "Invalid" 1898 "Invalid" 1897 "Invalid" 1896 "Invalid" 1895 "Invalid" 1894 "Invalid" 1893 "Invalid" 1892 "Invalid" 1891 "Invalid" 1890 "Invalid" 1889 "Invalid" 1888 "Invalid" 1887 "Invalid" 1886 "Invalid" 1885 "Invalid" 1884 "Invalid" 1883 "Invalid" 1882 "Invalid" 1881 "Invalid" 1880 "Invalid" 1879 "Invalid" 1878 "Invalid" 1877 "Invalid" 1876 "Invalid" 1875 "Invalid" 1874 "Invalid" 1873 "Invalid" 1872 "Invalid" 1871 "Invalid" 1870 "Invalid" 1869 "Invalid" 1868 "Invalid" 1867 "Invalid" 1866 "Invalid" 1865 "Invalid" 1864 "Invalid" 1863 "Invalid" 1862 "Invalid" 1861 "Invalid" 1860 "Invalid" 1859 "Invalid" 1858 "Invalid" 1857 "Invalid" 1856 "Invalid" 1855 "Invalid" 1854 "Invalid" 1853 "Invalid" 1852 "Invalid" 1851 "Invalid" 1850 "Invalid" 1849 "Invalid" 1848 "Invalid" 1847 "Invalid" 1846 "Invalid" 1845 "Invalid" 1844 "Invalid" 1843 "Invalid" 1842 "Invalid" 1841 "Invalid" 1840 "Invalid" 1839 "Invalid" 1838 "Invalid" 1837 "Invalid" 1836 "Invalid" 1835 "Invalid" 1834 "Invalid" 1833 "Invalid" 1832 "Invalid" 1831 "Invalid" 1830 "Invalid" 1829 "Invalid" 1828 "Invalid" 1827 "Invalid" 1826 "Invalid" 1825 "Invalid" 1824 "Invalid" 1823 "Invalid" 1822 "Invalid" 1821 "Invalid" 1820 "Invalid" 1819 "Invalid" 1818 "Invalid" 1817 "Invalid" 1816 "Invalid" 1815 "Invalid" 1814 "Invalid" 1813 "Invalid" 1812 "Invalid" 1811 "Invalid" 1810 "Invalid" 1809 "Invalid" 1808 "Invalid" 1807 "Invalid" 1806 "Invalid" 1805 "Invalid" 1804 "Invalid" 1803 "Invalid" 1802 "Invalid" 1801 "Invalid" ;
VAL_ 559 BCU_CellVlt064_RM 2047 "Invalid" 2046 "Invalid" 2045 "Invalid" 2044 "Invalid" 2043 "Invalid" 2042 "Invalid" 2041 "Invalid" 2040 "Invalid" 2039 "Invalid" 2038 "Invalid" 2037 "Invalid" 2036 "Invalid" 2035 "Invalid" 2034 "Invalid" 2033 "Invalid" 2032 "Invalid" 2031 "Invalid" 2030 "Invalid" 2029 "Invalid" 2028 "Invalid" 2027 "Invalid" 2026 "Invalid" 2025 "Invalid" 2024 "Invalid" 2023 "Invalid" 2022 "Invalid" 2021 "Invalid" 2020 "Invalid" 2019 "Invalid" 2018 "Invalid" 2017 "Invalid" 2016 "Invalid" 2015 "Invalid" 2014 "Invalid" 2013 "Invalid" 2012 "Invalid" 2011 "Invalid" 2010 "Invalid" 2009 "Invalid" 2008 "Invalid" 2007 "Invalid" 2006 "Invalid" 2005 "Invalid" 2004 "Invalid" 2003 "Invalid" 2002 "Invalid" 2001 "Invalid" 2000 "Invalid" 1999 "Invalid" 1998 "Invalid" 1997 "Invalid" 1996 "Invalid" 1995 "Invalid" 1994 "Invalid" 1993 "Invalid" 1992 "Invalid" 1991 "Invalid" 1990 "Invalid" 1989 "Invalid" 1988 "Invalid" 1987 "Invalid" 1986 "Invalid" 1985 "Invalid" 1984 "Invalid" 1983 "Invalid" 1982 "Invalid" 1981 "Invalid" 1980 "Invalid" 1979 "Invalid" 1978 "Invalid" 1977 "Invalid" 1976 "Invalid" 1975 "Invalid" 1974 "Invalid" 1973 "Invalid" 1972 "Invalid" 1971 "Invalid" 1970 "Invalid" 1969 "Invalid" 1968 "Invalid" 1967 "Invalid" 1966 "Invalid" 1965 "Invalid" 1964 "Invalid" 1963 "Invalid" 1962 "Invalid" 1961 "Invalid" 1960 "Invalid" 1959 "Invalid" 1958 "Invalid" 1957 "Invalid" 1956 "Invalid" 1955 "Invalid" 1954 "Invalid" 1953 "Invalid" 1952 "Invalid" 1951 "Invalid" 1950 "Invalid" 1949 "Invalid" 1948 "Invalid" 1947 "Invalid" 1946 "Invalid" 1945 "Invalid" 1944 "Invalid" 1943 "Invalid" 1942 "Invalid" 1941 "Invalid" 1940 "Invalid" 1939 "Invalid" 1938 "Invalid" 1937 "Invalid" 1936 "Invalid" 1935 "Invalid" 1934 "Invalid" 1933 "Invalid" 1932 "Invalid" 1931 "Invalid" 1930 "Invalid" 1929 "Invalid" 1928 "Invalid" 1927 "Invalid" 1926 "Invalid" 1925 "Invalid" 1924 "Invalid" 1923 "Invalid" 1922 "Invalid" 1921 "Invalid" 1920 "Invalid" 1919 "Invalid" 1918 "Invalid" 1917 "Invalid" 1916 "Invalid" 1915 "Invalid" 1914 "Invalid" 1913 "Invalid" 1912 "Invalid" 1911 "Invalid" 1910 "Invalid" 1909 "Invalid" 1908 "Invalid" 1907 "Invalid" 1906 "Invalid" 1905 "Invalid" 1904 "Invalid" 1903 "Invalid" 1902 "Invalid" 1901 "Invalid" 1900 "Invalid" 1899 "Invalid" 1898 "Invalid" 1897 "Invalid" 1896 "Invalid" 1895 "Invalid" 1894 "Invalid" 1893 "Invalid" 1892 "Invalid" 1891 "Invalid" 1890 "Invalid" 1889 "Invalid" 1888 "Invalid" 1887 "Invalid" 1886 "Invalid" 1885 "Invalid" 1884 "Invalid" 1883 "Invalid" 1882 "Invalid" 1881 "Invalid" 1880 "Invalid" 1879 "Invalid" 1878 "Invalid" 1877 "Invalid" 1876 "Invalid" 1875 "Invalid" 1874 "Invalid" 1873 "Invalid" 1872 "Invalid" 1871 "Invalid" 1870 "Invalid" 1869 "Invalid" 1868 "Invalid" 1867 "Invalid" 1866 "Invalid" 1865 "Invalid" 1864 "Invalid" 1863 "Invalid" 1862 "Invalid" 1861 "Invalid" 1860 "Invalid" 1859 "Invalid" 1858 "Invalid" 1857 "Invalid" 1856 "Invalid" 1855 "Invalid" 1854 "Invalid" 1853 "Invalid" 1852 "Invalid" 1851 "Invalid" 1850 "Invalid" 1849 "Invalid" 1848 "Invalid" 1847 "Invalid" 1846 "Invalid" 1845 "Invalid" 1844 "Invalid" 1843 "Invalid" 1842 "Invalid" 1841 "Invalid" 1840 "Invalid" 1839 "Invalid" 1838 "Invalid" 1837 "Invalid" 1836 "Invalid" 1835 "Invalid" 1834 "Invalid" 1833 "Invalid" 1832 "Invalid" 1831 "Invalid" 1830 "Invalid" 1829 "Invalid" 1828 "Invalid" 1827 "Invalid" 1826 "Invalid" 1825 "Invalid" 1824 "Invalid" 1823 "Invalid" 1822 "Invalid" 1821 "Invalid" 1820 "Invalid" 1819 "Invalid" 1818 "Invalid" 1817 "Invalid" 1816 "Invalid" 1815 "Invalid" 1814 "Invalid" 1813 "Invalid" 1812 "Invalid" 1811 "Invalid" 1810 "Invalid" 1809 "Invalid" 1808 "Invalid" 1807 "Invalid" 1806 "Invalid" 1805 "Invalid" 1804 "Invalid" 1803 "Invalid" 1802 "Invalid" 1801 "Invalid" ;
VAL_ 559 BCU_CellVlt065_RM 2047 "Invalid" 2046 "Invalid" 2045 "Invalid" 2044 "Invalid" 2043 "Invalid" 2042 "Invalid" 2041 "Invalid" 2040 "Invalid" 2039 "Invalid" 2038 "Invalid" 2037 "Invalid" 2036 "Invalid" 2035 "Invalid" 2034 "Invalid" 2033 "Invalid" 2032 "Invalid" 2031 "Invalid" 2030 "Invalid" 2029 "Invalid" 2028 "Invalid" 2027 "Invalid" 2026 "Invalid" 2025 "Invalid" 2024 "Invalid" 2023 "Invalid" 2022 "Invalid" 2021 "Invalid" 2020 "Invalid" 2019 "Invalid" 2018 "Invalid" 2017 "Invalid" 2016 "Invalid" 2015 "Invalid" 2014 "Invalid" 2013 "Invalid" 2012 "Invalid" 2011 "Invalid" 2010 "Invalid" 2009 "Invalid" 2008 "Invalid" 2007 "Invalid" 2006 "Invalid" 2005 "Invalid" 2004 "Invalid" 2003 "Invalid" 2002 "Invalid" 2001 "Invalid" 2000 "Invalid" 1999 "Invalid" 1998 "Invalid" 1997 "Invalid" 1996 "Invalid" 1995 "Invalid" 1994 "Invalid" 1993 "Invalid" 1992 "Invalid" 1991 "Invalid" 1990 "Invalid" 1989 "Invalid" 1988 "Invalid" 1987 "Invalid" 1986 "Invalid" 1985 "Invalid" 1984 "Invalid" 1983 "Invalid" 1982 "Invalid" 1981 "Invalid" 1980 "Invalid" 1979 "Invalid" 1978 "Invalid" 1977 "Invalid" 1976 "Invalid" 1975 "Invalid" 1974 "Invalid" 1973 "Invalid" 1972 "Invalid" 1971 "Invalid" 1970 "Invalid" 1969 "Invalid" 1968 "Invalid" 1967 "Invalid" 1966 "Invalid" 1965 "Invalid" 1964 "Invalid" 1963 "Invalid" 1962 "Invalid" 1961 "Invalid" 1960 "Invalid" 1959 "Invalid" 1958 "Invalid" 1957 "Invalid" 1956 "Invalid" 1955 "Invalid" 1954 "Invalid" 1953 "Invalid" 1952 "Invalid" 1951 "Invalid" 1950 "Invalid" 1949 "Invalid" 1948 "Invalid" 1947 "Invalid" 1946 "Invalid" 1945 "Invalid" 1944 "Invalid" 1943 "Invalid" 1942 "Invalid" 1941 "Invalid" 1940 "Invalid" 1939 "Invalid" 1938 "Invalid" 1937 "Invalid" 1936 "Invalid" 1935 "Invalid" 1934 "Invalid" 1933 "Invalid" 1932 "Invalid" 1931 "Invalid" 1930 "Invalid" 1929 "Invalid" 1928 "Invalid" 1927 "Invalid" 1926 "Invalid" 1925 "Invalid" 1924 "Invalid" 1923 "Invalid" 1922 "Invalid" 1921 "Invalid" 1920 "Invalid" 1919 "Invalid" 1918 "Invalid" 1917 "Invalid" 1916 "Invalid" 1915 "Invalid" 1914 "Invalid" 1913 "Invalid" 1912 "Invalid" 1911 "Invalid" 1910 "Invalid" 1909 "Invalid" 1908 "Invalid" 1907 "Invalid" 1906 "Invalid" 1905 "Invalid" 1904 "Invalid" 1903 "Invalid" 1902 "Invalid" 1901 "Invalid" 1900 "Invalid" 1899 "Invalid" 1898 "Invalid" 1897 "Invalid" 1896 "Invalid" 1895 "Invalid" 1894 "Invalid" 1893 "Invalid" 1892 "Invalid" 1891 "Invalid" 1890 "Invalid" 1889 "Invalid" 1888 "Invalid" 1887 "Invalid" 1886 "Invalid" 1885 "Invalid" 1884 "Invalid" 1883 "Invalid" 1882 "Invalid" 1881 "Invalid" 1880 "Invalid" 1879 "Invalid" 1878 "Invalid" 1877 "Invalid" 1876 "Invalid" 1875 "Invalid" 1874 "Invalid" 1873 "Invalid" 1872 "Invalid" 1871 "Invalid" 1870 "Invalid" 1869 "Invalid" 1868 "Invalid" 1867 "Invalid" 1866 "Invalid" 1865 "Invalid" 1864 "Invalid" 1863 "Invalid" 1862 "Invalid" 1861 "Invalid" 1860 "Invalid" 1859 "Invalid" 1858 "Invalid" 1857 "Invalid" 1856 "Invalid" 1855 "Invalid" 1854 "Invalid" 1853 "Invalid" 1852 "Invalid" 1851 "Invalid" 1850 "Invalid" 1849 "Invalid" 1848 "Invalid" 1847 "Invalid" 1846 "Invalid" 1845 "Invalid" 1844 "Invalid" 1843 "Invalid" 1842 "Invalid" 1841 "Invalid" 1840 "Invalid" 1839 "Invalid" 1838 "Invalid" 1837 "Invalid" 1836 "Invalid" 1835 "Invalid" 1834 "Invalid" 1833 "Invalid" 1832 "Invalid" 1831 "Invalid" 1830 "Invalid" 1829 "Invalid" 1828 "Invalid" 1827 "Invalid" 1826 "Invalid" 1825 "Invalid" 1824 "Invalid" 1823 "Invalid" 1822 "Invalid" 1821 "Invalid" 1820 "Invalid" 1819 "Invalid" 1818 "Invalid" 1817 "Invalid" 1816 "Invalid" 1815 "Invalid" 1814 "Invalid" 1813 "Invalid" 1812 "Invalid" 1811 "Invalid" 1810 "Invalid" 1809 "Invalid" 1808 "Invalid" 1807 "Invalid" 1806 "Invalid" 1805 "Invalid" 1804 "Invalid" 1803 "Invalid" 1802 "Invalid" 1801 "Invalid" ;
VAL_ 559 BCU_CellTmp013_RM 255 "Invalid" 254 "Invalid" 253 "Invalid" 252 "Invalid" 251 "Invalid" 250 "Invalid" 249 "Invalid" 248 "Invalid" 247 "Invalid" 246 "Invalid" 245 "Invalid" 244 "Invalid" 243 "Invalid" 242 "Invalid" 241 "Invalid" 240 "Invalid" 239 "Invalid" 238 "Invalid" 237 "Invalid" 236 "Invalid" 235 "Invalid" 234 "Invalid" 233 "Invalid" 232 "Invalid" 231 "Invalid" 230 "Invalid" 229 "Invalid" 228 "Invalid" 227 "Invalid" 226 "Invalid" 225 "Invalid" 224 "Invalid" 223 "Invalid" 222 "Invalid" 221 "Invalid" 220 "Invalid" 219 "Invalid" 218 "Invalid" 217 "Invalid" 216 "Invalid" 215 "Invalid" 214 "Invalid" 213 "Invalid" 212 "Invalid" 211 "Invalid" 210 "Invalid" 209 "Invalid" 208 "Invalid" 207 "Invalid" 206 "Invalid" 205 "Invalid" 204 "Invalid" 203 "Invalid" 202 "Invalid" 201 "Invalid" 200 "Invalid" 199 "Invalid" 198 "Invalid" 197 "Invalid" 196 "Invalid" 195 "Invalid" 194 "Invalid" 193 "Invalid" 192 "Invalid" 191 "Invalid" 190 "Invalid" 189 "Invalid" 188 "Invalid" 187 "Invalid" 186 "Invalid" 185 "Invalid" 184 "Invalid" 183 "Invalid" 182 "Invalid" 181 "Invalid" 180 "Invalid" 179 "Invalid" 178 "Invalid" 177 "Invalid" 176 "Invalid" 175 "Invalid" 174 "Invalid" 173 "Invalid" 172 "Invalid" 171 "Invalid" 170 "Invalid" 169 "Invalid" 168 "Invalid" 167 "Invalid" 166 "Invalid" 165 "Invalid" 164 "Invalid" 163 "Invalid" 162 "Invalid" 161 "Invalid" ;
VAL_ 1056 BCU_CellVlt066_RM 2047 "Invalid" 2046 "Invalid" 2045 "Invalid" 2044 "Invalid" 2043 "Invalid" 2042 "Invalid" 2041 "Invalid" 2040 "Invalid" 2039 "Invalid" 2038 "Invalid" 2037 "Invalid" 2036 "Invalid" 2035 "Invalid" 2034 "Invalid" 2033 "Invalid" 2032 "Invalid" 2031 "Invalid" 2030 "Invalid" 2029 "Invalid" 2028 "Invalid" 2027 "Invalid" 2026 "Invalid" 2025 "Invalid" 2024 "Invalid" 2023 "Invalid" 2022 "Invalid" 2021 "Invalid" 2020 "Invalid" 2019 "Invalid" 2018 "Invalid" 2017 "Invalid" 2016 "Invalid" 2015 "Invalid" 2014 "Invalid" 2013 "Invalid" 2012 "Invalid" 2011 "Invalid" 2010 "Invalid" 2009 "Invalid" 2008 "Invalid" 2007 "Invalid" 2006 "Invalid" 2005 "Invalid" 2004 "Invalid" 2003 "Invalid" 2002 "Invalid" 2001 "Invalid" 2000 "Invalid" 1999 "Invalid" 1998 "Invalid" 1997 "Invalid" 1996 "Invalid" 1995 "Invalid" 1994 "Invalid" 1993 "Invalid" 1992 "Invalid" 1991 "Invalid" 1990 "Invalid" 1989 "Invalid" 1988 "Invalid" 1987 "Invalid" 1986 "Invalid" 1985 "Invalid" 1984 "Invalid" 1983 "Invalid" 1982 "Invalid" 1981 "Invalid" 1980 "Invalid" 1979 "Invalid" 1978 "Invalid" 1977 "Invalid" 1976 "Invalid" 1975 "Invalid" 1974 "Invalid" 1973 "Invalid" 1972 "Invalid" 1971 "Invalid" 1970 "Invalid" 1969 "Invalid" 1968 "Invalid" 1967 "Invalid" 1966 "Invalid" 1965 "Invalid" 1964 "Invalid" 1963 "Invalid" 1962 "Invalid" 1961 "Invalid" 1960 "Invalid" 1959 "Invalid" 1958 "Invalid" 1957 "Invalid" 1956 "Invalid" 1955 "Invalid" 1954 "Invalid" 1953 "Invalid" 1952 "Invalid" 1951 "Invalid" 1950 "Invalid" 1949 "Invalid" 1948 "Invalid" 1947 "Invalid" 1946 "Invalid" 1945 "Invalid" 1944 "Invalid" 1943 "Invalid" 1942 "Invalid" 1941 "Invalid" 1940 "Invalid" 1939 "Invalid" 1938 "Invalid" 1937 "Invalid" 1936 "Invalid" 1935 "Invalid" 1934 "Invalid" 1933 "Invalid" 1932 "Invalid" 1931 "Invalid" 1930 "Invalid" 1929 "Invalid" 1928 "Invalid" 1927 "Invalid" 1926 "Invalid" 1925 "Invalid" 1924 "Invalid" 1923 "Invalid" 1922 "Invalid" 1921 "Invalid" 1920 "Invalid" 1919 "Invalid" 1918 "Invalid" 1917 "Invalid" 1916 "Invalid" 1915 "Invalid" 1914 "Invalid" 1913 "Invalid" 1912 "Invalid" 1911 "Invalid" 1910 "Invalid" 1909 "Invalid" 1908 "Invalid" 1907 "Invalid" 1906 "Invalid" 1905 "Invalid" 1904 "Invalid" 1903 "Invalid" 1902 "Invalid" 1901 "Invalid" 1900 "Invalid" 1899 "Invalid" 1898 "Invalid" 1897 "Invalid" 1896 "Invalid" 1895 "Invalid" 1894 "Invalid" 1893 "Invalid" 1892 "Invalid" 1891 "Invalid" 1890 "Invalid" 1889 "Invalid" 1888 "Invalid" 1887 "Invalid" 1886 "Invalid" 1885 "Invalid" 1884 "Invalid" 1883 "Invalid" 1882 "Invalid" 1881 "Invalid" 1880 "Invalid" 1879 "Invalid" 1878 "Invalid" 1877 "Invalid" 1876 "Invalid" 1875 "Invalid" 1874 "Invalid" 1873 "Invalid" 1872 "Invalid" 1871 "Invalid" 1870 "Invalid" 1869 "Invalid" 1868 "Invalid" 1867 "Invalid" 1866 "Invalid" 1865 "Invalid" 1864 "Invalid" 1863 "Invalid" 1862 "Invalid" 1861 "Invalid" 1860 "Invalid" 1859 "Invalid" 1858 "Invalid" 1857 "Invalid" 1856 "Invalid" 1855 "Invalid" 1854 "Invalid" 1853 "Invalid" 1852 "Invalid" 1851 "Invalid" 1850 "Invalid" 1849 "Invalid" 1848 "Invalid" 1847 "Invalid" 1846 "Invalid" 1845 "Invalid" 1844 "Invalid" 1843 "Invalid" 1842 "Invalid" 1841 "Invalid" 1840 "Invalid" 1839 "Invalid" 1838 "Invalid" 1837 "Invalid" 1836 "Invalid" 1835 "Invalid" 1834 "Invalid" 1833 "Invalid" 1832 "Invalid" 1831 "Invalid" 1830 "Invalid" 1829 "Invalid" 1828 "Invalid" 1827 "Invalid" 1826 "Invalid" 1825 "Invalid" 1824 "Invalid" 1823 "Invalid" 1822 "Invalid" 1821 "Invalid" 1820 "Invalid" 1819 "Invalid" 1818 "Invalid" 1817 "Invalid" 1816 "Invalid" 1815 "Invalid" 1814 "Invalid" 1813 "Invalid" 1812 "Invalid" 1811 "Invalid" 1810 "Invalid" 1809 "Invalid" 1808 "Invalid" 1807 "Invalid" 1806 "Invalid" 1805 "Invalid" 1804 "Invalid" 1803 "Invalid" 1802 "Invalid" 1801 "Invalid" ;
VAL_ 1056 BCU_CellVlt067_RM 2047 "Invalid" 2046 "Invalid" 2045 "Invalid" 2044 "Invalid" 2043 "Invalid" 2042 "Invalid" 2041 "Invalid" 2040 "Invalid" 2039 "Invalid" 2038 "Invalid" 2037 "Invalid" 2036 "Invalid" 2035 "Invalid" 2034 "Invalid" 2033 "Invalid" 2032 "Invalid" 2031 "Invalid" 2030 "Invalid" 2029 "Invalid" 2028 "Invalid" 2027 "Invalid" 2026 "Invalid" 2025 "Invalid" 2024 "Invalid" 2023 "Invalid" 2022 "Invalid" 2021 "Invalid" 2020 "Invalid" 2019 "Invalid" 2018 "Invalid" 2017 "Invalid" 2016 "Invalid" 2015 "Invalid" 2014 "Invalid" 2013 "Invalid" 2012 "Invalid" 2011 "Invalid" 2010 "Invalid" 2009 "Invalid" 2008 "Invalid" 2007 "Invalid" 2006 "Invalid" 2005 "Invalid" 2004 "Invalid" 2003 "Invalid" 2002 "Invalid" 2001 "Invalid" 2000 "Invalid" 1999 "Invalid" 1998 "Invalid" 1997 "Invalid" 1996 "Invalid" 1995 "Invalid" 1994 "Invalid" 1993 "Invalid" 1992 "Invalid" 1991 "Invalid" 1990 "Invalid" 1989 "Invalid" 1988 "Invalid" 1987 "Invalid" 1986 "Invalid" 1985 "Invalid" 1984 "Invalid" 1983 "Invalid" 1982 "Invalid" 1981 "Invalid" 1980 "Invalid" 1979 "Invalid" 1978 "Invalid" 1977 "Invalid" 1976 "Invalid" 1975 "Invalid" 1974 "Invalid" 1973 "Invalid" 1972 "Invalid" 1971 "Invalid" 1970 "Invalid" 1969 "Invalid" 1968 "Invalid" 1967 "Invalid" 1966 "Invalid" 1965 "Invalid" 1964 "Invalid" 1963 "Invalid" 1962 "Invalid" 1961 "Invalid" 1960 "Invalid" 1959 "Invalid" 1958 "Invalid" 1957 "Invalid" 1956 "Invalid" 1955 "Invalid" 1954 "Invalid" 1953 "Invalid" 1952 "Invalid" 1951 "Invalid" 1950 "Invalid" 1949 "Invalid" 1948 "Invalid" 1947 "Invalid" 1946 "Invalid" 1945 "Invalid" 1944 "Invalid" 1943 "Invalid" 1942 "Invalid" 1941 "Invalid" 1940 "Invalid" 1939 "Invalid" 1938 "Invalid" 1937 "Invalid" 1936 "Invalid" 1935 "Invalid" 1934 "Invalid" 1933 "Invalid" 1932 "Invalid" 1931 "Invalid" 1930 "Invalid" 1929 "Invalid" 1928 "Invalid" 1927 "Invalid" 1926 "Invalid" 1925 "Invalid" 1924 "Invalid" 1923 "Invalid" 1922 "Invalid" 1921 "Invalid" 1920 "Invalid" 1919 "Invalid" 1918 "Invalid" 1917 "Invalid" 1916 "Invalid" 1915 "Invalid" 1914 "Invalid" 1913 "Invalid" 1912 "Invalid" 1911 "Invalid" 1910 "Invalid" 1909 "Invalid" 1908 "Invalid" 1907 "Invalid" 1906 "Invalid" 1905 "Invalid" 1904 "Invalid" 1903 "Invalid" 1902 "Invalid" 1901 "Invalid" 1900 "Invalid" 1899 "Invalid" 1898 "Invalid" 1897 "Invalid" 1896 "Invalid" 1895 "Invalid" 1894 "Invalid" 1893 "Invalid" 1892 "Invalid" 1891 "Invalid" 1890 "Invalid" 1889 "Invalid" 1888 "Invalid" 1887 "Invalid" 1886 "Invalid" 1885 "Invalid" 1884 "Invalid" 1883 "Invalid" 1882 "Invalid" 1881 "Invalid" 1880 "Invalid" 1879 "Invalid" 1878 "Invalid" 1877 "Invalid" 1876 "Invalid" 1875 "Invalid" 1874 "Invalid" 1873 "Invalid" 1872 "Invalid" 1871 "Invalid" 1870 "Invalid" 1869 "Invalid" 1868 "Invalid" 1867 "Invalid" 1866 "Invalid" 1865 "Invalid" 1864 "Invalid" 1863 "Invalid" 1862 "Invalid" 1861 "Invalid" 1860 "Invalid" 1859 "Invalid" 1858 "Invalid" 1857 "Invalid" 1856 "Invalid" 1855 "Invalid" 1854 "Invalid" 1853 "Invalid" 1852 "Invalid" 1851 "Invalid" 1850 "Invalid" 1849 "Invalid" 1848 "Invalid" 1847 "Invalid" 1846 "Invalid" 1845 "Invalid" 1844 "Invalid" 1843 "Invalid" 1842 "Invalid" 1841 "Invalid" 1840 "Invalid" 1839 "Invalid" 1838 "Invalid" 1837 "Invalid" 1836 "Invalid" 1835 "Invalid" 1834 "Invalid" 1833 "Invalid" 1832 "Invalid" 1831 "Invalid" 1830 "Invalid" 1829 "Invalid" 1828 "Invalid" 1827 "Invalid" 1826 "Invalid" 1825 "Invalid" 1824 "Invalid" 1823 "Invalid" 1822 "Invalid" 1821 "Invalid" 1820 "Invalid" 1819 "Invalid" 1818 "Invalid" 1817 "Invalid" 1816 "Invalid" 1815 "Invalid" 1814 "Invalid" 1813 "Invalid" 1812 "Invalid" 1811 "Invalid" 1810 "Invalid" 1809 "Invalid" 1808 "Invalid" 1807 "Invalid" 1806 "Invalid" 1805 "Invalid" 1804 "Invalid" 1803 "Invalid" 1802 "Invalid" 1801 "Invalid" ;
VAL_ 1056 BCU_CellVlt068_RM 2047 "Invalid" 2046 "Invalid" 2045 "Invalid" 2044 "Invalid" 2043 "Invalid" 2042 "Invalid" 2041 "Invalid" 2040 "Invalid" 2039 "Invalid" 2038 "Invalid" 2037 "Invalid" 2036 "Invalid" 2035 "Invalid" 2034 "Invalid" 2033 "Invalid" 2032 "Invalid" 2031 "Invalid" 2030 "Invalid" 2029 "Invalid" 2028 "Invalid" 2027 "Invalid" 2026 "Invalid" 2025 "Invalid" 2024 "Invalid" 2023 "Invalid" 2022 "Invalid" 2021 "Invalid" 2020 "Invalid" 2019 "Invalid" 2018 "Invalid" 2017 "Invalid" 2016 "Invalid" 2015 "Invalid" 2014 "Invalid" 2013 "Invalid" 2012 "Invalid" 2011 "Invalid" 2010 "Invalid" 2009 "Invalid" 2008 "Invalid" 2007 "Invalid" 2006 "Invalid" 2005 "Invalid" 2004 "Invalid" 2003 "Invalid" 2002 "Invalid" 2001 "Invalid" 2000 "Invalid" 1999 "Invalid" 1998 "Invalid" 1997 "Invalid" 1996 "Invalid" 1995 "Invalid" 1994 "Invalid" 1993 "Invalid" 1992 "Invalid" 1991 "Invalid" 1990 "Invalid" 1989 "Invalid" 1988 "Invalid" 1987 "Invalid" 1986 "Invalid" 1985 "Invalid" 1984 "Invalid" 1983 "Invalid" 1982 "Invalid" 1981 "Invalid" 1980 "Invalid" 1979 "Invalid" 1978 "Invalid" 1977 "Invalid" 1976 "Invalid" 1975 "Invalid" 1974 "Invalid" 1973 "Invalid" 1972 "Invalid" 1971 "Invalid" 1970 "Invalid" 1969 "Invalid" 1968 "Invalid" 1967 "Invalid" 1966 "Invalid" 1965 "Invalid" 1964 "Invalid" 1963 "Invalid" 1962 "Invalid" 1961 "Invalid" 1960 "Invalid" 1959 "Invalid" 1958 "Invalid" 1957 "Invalid" 1956 "Invalid" 1955 "Invalid" 1954 "Invalid" 1953 "Invalid" 1952 "Invalid" 1951 "Invalid" 1950 "Invalid" 1949 "Invalid" 1948 "Invalid" 1947 "Invalid" 1946 "Invalid" 1945 "Invalid" 1944 "Invalid" 1943 "Invalid" 1942 "Invalid" 1941 "Invalid" 1940 "Invalid" 1939 "Invalid" 1938 "Invalid" 1937 "Invalid" 1936 "Invalid" 1935 "Invalid" 1934 "Invalid" 1933 "Invalid" 1932 "Invalid" 1931 "Invalid" 1930 "Invalid" 1929 "Invalid" 1928 "Invalid" 1927 "Invalid" 1926 "Invalid" 1925 "Invalid" 1924 "Invalid" 1923 "Invalid" 1922 "Invalid" 1921 "Invalid" 1920 "Invalid" 1919 "Invalid" 1918 "Invalid" 1917 "Invalid" 1916 "Invalid" 1915 "Invalid" 1914 "Invalid" 1913 "Invalid" 1912 "Invalid" 1911 "Invalid" 1910 "Invalid" 1909 "Invalid" 1908 "Invalid" 1907 "Invalid" 1906 "Invalid" 1905 "Invalid" 1904 "Invalid" 1903 "Invalid" 1902 "Invalid" 1901 "Invalid" 1900 "Invalid" 1899 "Invalid" 1898 "Invalid" 1897 "Invalid" 1896 "Invalid" 1895 "Invalid" 1894 "Invalid" 1893 "Invalid" 1892 "Invalid" 1891 "Invalid" 1890 "Invalid" 1889 "Invalid" 1888 "Invalid" 1887 "Invalid" 1886 "Invalid" 1885 "Invalid" 1884 "Invalid" 1883 "Invalid" 1882 "Invalid" 1881 "Invalid" 1880 "Invalid" 1879 "Invalid" 1878 "Invalid" 1877 "Invalid" 1876 "Invalid" 1875 "Invalid" 1874 "Invalid" 1873 "Invalid" 1872 "Invalid" 1871 "Invalid" 1870 "Invalid" 1869 "Invalid" 1868 "Invalid" 1867 "Invalid" 1866 "Invalid" 1865 "Invalid" 1864 "Invalid" 1863 "Invalid" 1862 "Invalid" 1861 "Invalid" 1860 "Invalid" 1859 "Invalid" 1858 "Invalid" 1857 "Invalid" 1856 "Invalid" 1855 "Invalid" 1854 "Invalid" 1853 "Invalid" 1852 "Invalid" 1851 "Invalid" 1850 "Invalid" 1849 "Invalid" 1848 "Invalid" 1847 "Invalid" 1846 "Invalid" 1845 "Invalid" 1844 "Invalid" 1843 "Invalid" 1842 "Invalid" 1841 "Invalid" 1840 "Invalid" 1839 "Invalid" 1838 "Invalid" 1837 "Invalid" 1836 "Invalid" 1835 "Invalid" 1834 "Invalid" 1833 "Invalid" 1832 "Invalid" 1831 "Invalid" 1830 "Invalid" 1829 "Invalid" 1828 "Invalid" 1827 "Invalid" 1826 "Invalid" 1825 "Invalid" 1824 "Invalid" 1823 "Invalid" 1822 "Invalid" 1821 "Invalid" 1820 "Invalid" 1819 "Invalid" 1818 "Invalid" 1817 "Invalid" 1816 "Invalid" 1815 "Invalid" 1814 "Invalid" 1813 "Invalid" 1812 "Invalid" 1811 "Invalid" 1810 "Invalid" 1809 "Invalid" 1808 "Invalid" 1807 "Invalid" 1806 "Invalid" 1805 "Invalid" 1804 "Invalid" 1803 "Invalid" 1802 "Invalid" 1801 "Invalid" ;
VAL_ 1056 BCU_CellVlt069_RM 2047 "Invalid" 2046 "Invalid" 2045 "Invalid" 2044 "Invalid" 2043 "Invalid" 2042 "Invalid" 2041 "Invalid" 2040 "Invalid" 2039 "Invalid" 2038 "Invalid" 2037 "Invalid" 2036 "Invalid" 2035 "Invalid" 2034 "Invalid" 2033 "Invalid" 2032 "Invalid" 2031 "Invalid" 2030 "Invalid" 2029 "Invalid" 2028 "Invalid" 2027 "Invalid" 2026 "Invalid" 2025 "Invalid" 2024 "Invalid" 2023 "Invalid" 2022 "Invalid" 2021 "Invalid" 2020 "Invalid" 2019 "Invalid" 2018 "Invalid" 2017 "Invalid" 2016 "Invalid" 2015 "Invalid" 2014 "Invalid" 2013 "Invalid" 2012 "Invalid" 2011 "Invalid" 2010 "Invalid" 2009 "Invalid" 2008 "Invalid" 2007 "Invalid" 2006 "Invalid" 2005 "Invalid" 2004 "Invalid" 2003 "Invalid" 2002 "Invalid" 2001 "Invalid" 2000 "Invalid" 1999 "Invalid" 1998 "Invalid" 1997 "Invalid" 1996 "Invalid" 1995 "Invalid" 1994 "Invalid" 1993 "Invalid" 1992 "Invalid" 1991 "Invalid" 1990 "Invalid" 1989 "Invalid" 1988 "Invalid" 1987 "Invalid" 1986 "Invalid" 1985 "Invalid" 1984 "Invalid" 1983 "Invalid" 1982 "Invalid" 1981 "Invalid" 1980 "Invalid" 1979 "Invalid" 1978 "Invalid" 1977 "Invalid" 1976 "Invalid" 1975 "Invalid" 1974 "Invalid" 1973 "Invalid" 1972 "Invalid" 1971 "Invalid" 1970 "Invalid" 1969 "Invalid" 1968 "Invalid" 1967 "Invalid" 1966 "Invalid" 1965 "Invalid" 1964 "Invalid" 1963 "Invalid" 1962 "Invalid" 1961 "Invalid" 1960 "Invalid" 1959 "Invalid" 1958 "Invalid" 1957 "Invalid" 1956 "Invalid" 1955 "Invalid" 1954 "Invalid" 1953 "Invalid" 1952 "Invalid" 1951 "Invalid" 1950 "Invalid" 1949 "Invalid" 1948 "Invalid" 1947 "Invalid" 1946 "Invalid" 1945 "Invalid" 1944 "Invalid" 1943 "Invalid" 1942 "Invalid" 1941 "Invalid" 1940 "Invalid" 1939 "Invalid" 1938 "Invalid" 1937 "Invalid" 1936 "Invalid" 1935 "Invalid" 1934 "Invalid" 1933 "Invalid" 1932 "Invalid" 1931 "Invalid" 1930 "Invalid" 1929 "Invalid" 1928 "Invalid" 1927 "Invalid" 1926 "Invalid" 1925 "Invalid" 1924 "Invalid" 1923 "Invalid" 1922 "Invalid" 1921 "Invalid" 1920 "Invalid" 1919 "Invalid" 1918 "Invalid" 1917 "Invalid" 1916 "Invalid" 1915 "Invalid" 1914 "Invalid" 1913 "Invalid" 1912 "Invalid" 1911 "Invalid" 1910 "Invalid" 1909 "Invalid" 1908 "Invalid" 1907 "Invalid" 1906 "Invalid" 1905 "Invalid" 1904 "Invalid" 1903 "Invalid" 1902 "Invalid" 1901 "Invalid" 1900 "Invalid" 1899 "Invalid" 1898 "Invalid" 1897 "Invalid" 1896 "Invalid" 1895 "Invalid" 1894 "Invalid" 1893 "Invalid" 1892 "Invalid" 1891 "Invalid" 1890 "Invalid" 1889 "Invalid" 1888 "Invalid" 1887 "Invalid" 1886 "Invalid" 1885 "Invalid" 1884 "Invalid" 1883 "Invalid" 1882 "Invalid" 1881 "Invalid" 1880 "Invalid" 1879 "Invalid" 1878 "Invalid" 1877 "Invalid" 1876 "Invalid" 1875 "Invalid" 1874 "Invalid" 1873 "Invalid" 1872 "Invalid" 1871 "Invalid" 1870 "Invalid" 1869 "Invalid" 1868 "Invalid" 1867 "Invalid" 1866 "Invalid" 1865 "Invalid" 1864 "Invalid" 1863 "Invalid" 1862 "Invalid" 1861 "Invalid" 1860 "Invalid" 1859 "Invalid" 1858 "Invalid" 1857 "Invalid" 1856 "Invalid" 1855 "Invalid" 1854 "Invalid" 1853 "Invalid" 1852 "Invalid" 1851 "Invalid" 1850 "Invalid" 1849 "Invalid" 1848 "Invalid" 1847 "Invalid" 1846 "Invalid" 1845 "Invalid" 1844 "Invalid" 1843 "Invalid" 1842 "Invalid" 1841 "Invalid" 1840 "Invalid" 1839 "Invalid" 1838 "Invalid" 1837 "Invalid" 1836 "Invalid" 1835 "Invalid" 1834 "Invalid" 1833 "Invalid" 1832 "Invalid" 1831 "Invalid" 1830 "Invalid" 1829 "Invalid" 1828 "Invalid" 1827 "Invalid" 1826 "Invalid" 1825 "Invalid" 1824 "Invalid" 1823 "Invalid" 1822 "Invalid" 1821 "Invalid" 1820 "Invalid" 1819 "Invalid" 1818 "Invalid" 1817 "Invalid" 1816 "Invalid" 1815 "Invalid" 1814 "Invalid" 1813 "Invalid" 1812 "Invalid" 1811 "Invalid" 1810 "Invalid" 1809 "Invalid" 1808 "Invalid" 1807 "Invalid" 1806 "Invalid" 1805 "Invalid" 1804 "Invalid" 1803 "Invalid" 1802 "Invalid" 1801 "Invalid" ;
VAL_ 1056 BCU_CellVlt070_RM 2047 "Invalid" 2046 "Invalid" 2045 "Invalid" 2044 "Invalid" 2043 "Invalid" 2042 "Invalid" 2041 "Invalid" 2040 "Invalid" 2039 "Invalid" 2038 "Invalid" 2037 "Invalid" 2036 "Invalid" 2035 "Invalid" 2034 "Invalid" 2033 "Invalid" 2032 "Invalid" 2031 "Invalid" 2030 "Invalid" 2029 "Invalid" 2028 "Invalid" 2027 "Invalid" 2026 "Invalid" 2025 "Invalid" 2024 "Invalid" 2023 "Invalid" 2022 "Invalid" 2021 "Invalid" 2020 "Invalid" 2019 "Invalid" 2018 "Invalid" 2017 "Invalid" 2016 "Invalid" 2015 "Invalid" 2014 "Invalid" 2013 "Invalid" 2012 "Invalid" 2011 "Invalid" 2010 "Invalid" 2009 "Invalid" 2008 "Invalid" 2007 "Invalid" 2006 "Invalid" 2005 "Invalid" 2004 "Invalid" 2003 "Invalid" 2002 "Invalid" 2001 "Invalid" 2000 "Invalid" 1999 "Invalid" 1998 "Invalid" 1997 "Invalid" 1996 "Invalid" 1995 "Invalid" 1994 "Invalid" 1993 "Invalid" 1992 "Invalid" 1991 "Invalid" 1990 "Invalid" 1989 "Invalid" 1988 "Invalid" 1987 "Invalid" 1986 "Invalid" 1985 "Invalid" 1984 "Invalid" 1983 "Invalid" 1982 "Invalid" 1981 "Invalid" 1980 "Invalid" 1979 "Invalid" 1978 "Invalid" 1977 "Invalid" 1976 "Invalid" 1975 "Invalid" 1974 "Invalid" 1973 "Invalid" 1972 "Invalid" 1971 "Invalid" 1970 "Invalid" 1969 "Invalid" 1968 "Invalid" 1967 "Invalid" 1966 "Invalid" 1965 "Invalid" 1964 "Invalid" 1963 "Invalid" 1962 "Invalid" 1961 "Invalid" 1960 "Invalid" 1959 "Invalid" 1958 "Invalid" 1957 "Invalid" 1956 "Invalid" 1955 "Invalid" 1954 "Invalid" 1953 "Invalid" 1952 "Invalid" 1951 "Invalid" 1950 "Invalid" 1949 "Invalid" 1948 "Invalid" 1947 "Invalid" 1946 "Invalid" 1945 "Invalid" 1944 "Invalid" 1943 "Invalid" 1942 "Invalid" 1941 "Invalid" 1940 "Invalid" 1939 "Invalid" 1938 "Invalid" 1937 "Invalid" 1936 "Invalid" 1935 "Invalid" 1934 "Invalid" 1933 "Invalid" 1932 "Invalid" 1931 "Invalid" 1930 "Invalid" 1929 "Invalid" 1928 "Invalid" 1927 "Invalid" 1926 "Invalid" 1925 "Invalid" 1924 "Invalid" 1923 "Invalid" 1922 "Invalid" 1921 "Invalid" 1920 "Invalid" 1919 "Invalid" 1918 "Invalid" 1917 "Invalid" 1916 "Invalid" 1915 "Invalid" 1914 "Invalid" 1913 "Invalid" 1912 "Invalid" 1911 "Invalid" 1910 "Invalid" 1909 "Invalid" 1908 "Invalid" 1907 "Invalid" 1906 "Invalid" 1905 "Invalid" 1904 "Invalid" 1903 "Invalid" 1902 "Invalid" 1901 "Invalid" 1900 "Invalid" 1899 "Invalid" 1898 "Invalid" 1897 "Invalid" 1896 "Invalid" 1895 "Invalid" 1894 "Invalid" 1893 "Invalid" 1892 "Invalid" 1891 "Invalid" 1890 "Invalid" 1889 "Invalid" 1888 "Invalid" 1887 "Invalid" 1886 "Invalid" 1885 "Invalid" 1884 "Invalid" 1883 "Invalid" 1882 "Invalid" 1881 "Invalid" 1880 "Invalid" 1879 "Invalid" 1878 "Invalid" 1877 "Invalid" 1876 "Invalid" 1875 "Invalid" 1874 "Invalid" 1873 "Invalid" 1872 "Invalid" 1871 "Invalid" 1870 "Invalid" 1869 "Invalid" 1868 "Invalid" 1867 "Invalid" 1866 "Invalid" 1865 "Invalid" 1864 "Invalid" 1863 "Invalid" 1862 "Invalid" 1861 "Invalid" 1860 "Invalid" 1859 "Invalid" 1858 "Invalid" 1857 "Invalid" 1856 "Invalid" 1855 "Invalid" 1854 "Invalid" 1853 "Invalid" 1852 "Invalid" 1851 "Invalid" 1850 "Invalid" 1849 "Invalid" 1848 "Invalid" 1847 "Invalid" 1846 "Invalid" 1845 "Invalid" 1844 "Invalid" 1843 "Invalid" 1842 "Invalid" 1841 "Invalid" 1840 "Invalid" 1839 "Invalid" 1838 "Invalid" 1837 "Invalid" 1836 "Invalid" 1835 "Invalid" 1834 "Invalid" 1833 "Invalid" 1832 "Invalid" 1831 "Invalid" 1830 "Invalid" 1829 "Invalid" 1828 "Invalid" 1827 "Invalid" 1826 "Invalid" 1825 "Invalid" 1824 "Invalid" 1823 "Invalid" 1822 "Invalid" 1821 "Invalid" 1820 "Invalid" 1819 "Invalid" 1818 "Invalid" 1817 "Invalid" 1816 "Invalid" 1815 "Invalid" 1814 "Invalid" 1813 "Invalid" 1812 "Invalid" 1811 "Invalid" 1810 "Invalid" 1809 "Invalid" 1808 "Invalid" 1807 "Invalid" 1806 "Invalid" 1805 "Invalid" 1804 "Invalid" 1803 "Invalid" 1802 "Invalid" 1801 "Invalid" ;
VAL_ 1056 BCU_CellTmp014_RM 255 "Invalid" 254 "Invalid" 253 "Invalid" 252 "Invalid" 251 "Invalid" 250 "Invalid" 249 "Invalid" 248 "Invalid" 247 "Invalid" 246 "Invalid" 245 "Invalid" 244 "Invalid" 243 "Invalid" 242 "Invalid" 241 "Invalid" 240 "Invalid" 239 "Invalid" 238 "Invalid" 237 "Invalid" 236 "Invalid" 235 "Invalid" 234 "Invalid" 233 "Invalid" 232 "Invalid" 231 "Invalid" 230 "Invalid" 229 "Invalid" 228 "Invalid" 227 "Invalid" 226 "Invalid" 225 "Invalid" 224 "Invalid" 223 "Invalid" 222 "Invalid" 221 "Invalid" 220 "Invalid" 219 "Invalid" 218 "Invalid" 217 "Invalid" 216 "Invalid" 215 "Invalid" 214 "Invalid" 213 "Invalid" 212 "Invalid" 211 "Invalid" 210 "Invalid" 209 "Invalid" 208 "Invalid" 207 "Invalid" 206 "Invalid" 205 "Invalid" 204 "Invalid" 203 "Invalid" 202 "Invalid" 201 "Invalid" 200 "Invalid" 199 "Invalid" 198 "Invalid" 197 "Invalid" 196 "Invalid" 195 "Invalid" 194 "Invalid" 193 "Invalid" 192 "Invalid" 191 "Invalid" 190 "Invalid" 189 "Invalid" 188 "Invalid" 187 "Invalid" 186 "Invalid" 185 "Invalid" 184 "Invalid" 183 "Invalid" 182 "Invalid" 181 "Invalid" 180 "Invalid" 179 "Invalid" 178 "Invalid" 177 "Invalid" 176 "Invalid" 175 "Invalid" 174 "Invalid" 173 "Invalid" 172 "Invalid" 171 "Invalid" 170 "Invalid" 169 "Invalid" 168 "Invalid" 167 "Invalid" 166 "Invalid" 165 "Invalid" 164 "Invalid" 163 "Invalid" 162 "Invalid" 161 "Invalid" ;
VAL_ 1057 BCU_CellVlt071_RM 2047 "Invalid" 2046 "Invalid" 2045 "Invalid" 2044 "Invalid" 2043 "Invalid" 2042 "Invalid" 2041 "Invalid" 2040 "Invalid" 2039 "Invalid" 2038 "Invalid" 2037 "Invalid" 2036 "Invalid" 2035 "Invalid" 2034 "Invalid" 2033 "Invalid" 2032 "Invalid" 2031 "Invalid" 2030 "Invalid" 2029 "Invalid" 2028 "Invalid" 2027 "Invalid" 2026 "Invalid" 2025 "Invalid" 2024 "Invalid" 2023 "Invalid" 2022 "Invalid" 2021 "Invalid" 2020 "Invalid" 2019 "Invalid" 2018 "Invalid" 2017 "Invalid" 2016 "Invalid" 2015 "Invalid" 2014 "Invalid" 2013 "Invalid" 2012 "Invalid" 2011 "Invalid" 2010 "Invalid" 2009 "Invalid" 2008 "Invalid" 2007 "Invalid" 2006 "Invalid" 2005 "Invalid" 2004 "Invalid" 2003 "Invalid" 2002 "Invalid" 2001 "Invalid" 2000 "Invalid" 1999 "Invalid" 1998 "Invalid" 1997 "Invalid" 1996 "Invalid" 1995 "Invalid" 1994 "Invalid" 1993 "Invalid" 1992 "Invalid" 1991 "Invalid" 1990 "Invalid" 1989 "Invalid" 1988 "Invalid" 1987 "Invalid" 1986 "Invalid" 1985 "Invalid" 1984 "Invalid" 1983 "Invalid" 1982 "Invalid" 1981 "Invalid" 1980 "Invalid" 1979 "Invalid" 1978 "Invalid" 1977 "Invalid" 1976 "Invalid" 1975 "Invalid" 1974 "Invalid" 1973 "Invalid" 1972 "Invalid" 1971 "Invalid" 1970 "Invalid" 1969 "Invalid" 1968 "Invalid" 1967 "Invalid" 1966 "Invalid" 1965 "Invalid" 1964 "Invalid" 1963 "Invalid" 1962 "Invalid" 1961 "Invalid" 1960 "Invalid" 1959 "Invalid" 1958 "Invalid" 1957 "Invalid" 1956 "Invalid" 1955 "Invalid" 1954 "Invalid" 1953 "Invalid" 1952 "Invalid" 1951 "Invalid" 1950 "Invalid" 1949 "Invalid" 1948 "Invalid" 1947 "Invalid" 1946 "Invalid" 1945 "Invalid" 1944 "Invalid" 1943 "Invalid" 1942 "Invalid" 1941 "Invalid" 1940 "Invalid" 1939 "Invalid" 1938 "Invalid" 1937 "Invalid" 1936 "Invalid" 1935 "Invalid" 1934 "Invalid" 1933 "Invalid" 1932 "Invalid" 1931 "Invalid" 1930 "Invalid" 1929 "Invalid" 1928 "Invalid" 1927 "Invalid" 1926 "Invalid" 1925 "Invalid" 1924 "Invalid" 1923 "Invalid" 1922 "Invalid" 1921 "Invalid" 1920 "Invalid" 1919 "Invalid" 1918 "Invalid" 1917 "Invalid" 1916 "Invalid" 1915 "Invalid" 1914 "Invalid" 1913 "Invalid" 1912 "Invalid" 1911 "Invalid" 1910 "Invalid" 1909 "Invalid" 1908 "Invalid" 1907 "Invalid" 1906 "Invalid" 1905 "Invalid" 1904 "Invalid" 1903 "Invalid" 1902 "Invalid" 1901 "Invalid" 1900 "Invalid" 1899 "Invalid" 1898 "Invalid" 1897 "Invalid" 1896 "Invalid" 1895 "Invalid" 1894 "Invalid" 1893 "Invalid" 1892 "Invalid" 1891 "Invalid" 1890 "Invalid" 1889 "Invalid" 1888 "Invalid" 1887 "Invalid" 1886 "Invalid" 1885 "Invalid" 1884 "Invalid" 1883 "Invalid" 1882 "Invalid" 1881 "Invalid" 1880 "Invalid" 1879 "Invalid" 1878 "Invalid" 1877 "Invalid" 1876 "Invalid" 1875 "Invalid" 1874 "Invalid" 1873 "Invalid" 1872 "Invalid" 1871 "Invalid" 1870 "Invalid" 1869 "Invalid" 1868 "Invalid" 1867 "Invalid" 1866 "Invalid" 1865 "Invalid" 1864 "Invalid" 1863 "Invalid" 1862 "Invalid" 1861 "Invalid" 1860 "Invalid" 1859 "Invalid" 1858 "Invalid" 1857 "Invalid" 1856 "Invalid" 1855 "Invalid" 1854 "Invalid" 1853 "Invalid" 1852 "Invalid" 1851 "Invalid" 1850 "Invalid" 1849 "Invalid" 1848 "Invalid" 1847 "Invalid" 1846 "Invalid" 1845 "Invalid" 1844 "Invalid" 1843 "Invalid" 1842 "Invalid" 1841 "Invalid" 1840 "Invalid" 1839 "Invalid" 1838 "Invalid" 1837 "Invalid" 1836 "Invalid" 1835 "Invalid" 1834 "Invalid" 1833 "Invalid" 1832 "Invalid" 1831 "Invalid" 1830 "Invalid" 1829 "Invalid" 1828 "Invalid" 1827 "Invalid" 1826 "Invalid" 1825 "Invalid" 1824 "Invalid" 1823 "Invalid" 1822 "Invalid" 1821 "Invalid" 1820 "Invalid" 1819 "Invalid" 1818 "Invalid" 1817 "Invalid" 1816 "Invalid" 1815 "Invalid" 1814 "Invalid" 1813 "Invalid" 1812 "Invalid" 1811 "Invalid" 1810 "Invalid" 1809 "Invalid" 1808 "Invalid" 1807 "Invalid" 1806 "Invalid" 1805 "Invalid" 1804 "Invalid" 1803 "Invalid" 1802 "Invalid" 1801 "Invalid" ;
VAL_ 1057 BCU_CellVlt072_RM 2047 "Invalid" 2046 "Invalid" 2045 "Invalid" 2044 "Invalid" 2043 "Invalid" 2042 "Invalid" 2041 "Invalid" 2040 "Invalid" 2039 "Invalid" 2038 "Invalid" 2037 "Invalid" 2036 "Invalid" 2035 "Invalid" 2034 "Invalid" 2033 "Invalid" 2032 "Invalid" 2031 "Invalid" 2030 "Invalid" 2029 "Invalid" 2028 "Invalid" 2027 "Invalid" 2026 "Invalid" 2025 "Invalid" 2024 "Invalid" 2023 "Invalid" 2022 "Invalid" 2021 "Invalid" 2020 "Invalid" 2019 "Invalid" 2018 "Invalid" 2017 "Invalid" 2016 "Invalid" 2015 "Invalid" 2014 "Invalid" 2013 "Invalid" 2012 "Invalid" 2011 "Invalid" 2010 "Invalid" 2009 "Invalid" 2008 "Invalid" 2007 "Invalid" 2006 "Invalid" 2005 "Invalid" 2004 "Invalid" 2003 "Invalid" 2002 "Invalid" 2001 "Invalid" 2000 "Invalid" 1999 "Invalid" 1998 "Invalid" 1997 "Invalid" 1996 "Invalid" 1995 "Invalid" 1994 "Invalid" 1993 "Invalid" 1992 "Invalid" 1991 "Invalid" 1990 "Invalid" 1989 "Invalid" 1988 "Invalid" 1987 "Invalid" 1986 "Invalid" 1985 "Invalid" 1984 "Invalid" 1983 "Invalid" 1982 "Invalid" 1981 "Invalid" 1980 "Invalid" 1979 "Invalid" 1978 "Invalid" 1977 "Invalid" 1976 "Invalid" 1975 "Invalid" 1974 "Invalid" 1973 "Invalid" 1972 "Invalid" 1971 "Invalid" 1970 "Invalid" 1969 "Invalid" 1968 "Invalid" 1967 "Invalid" 1966 "Invalid" 1965 "Invalid" 1964 "Invalid" 1963 "Invalid" 1962 "Invalid" 1961 "Invalid" 1960 "Invalid" 1959 "Invalid" 1958 "Invalid" 1957 "Invalid" 1956 "Invalid" 1955 "Invalid" 1954 "Invalid" 1953 "Invalid" 1952 "Invalid" 1951 "Invalid" 1950 "Invalid" 1949 "Invalid" 1948 "Invalid" 1947 "Invalid" 1946 "Invalid" 1945 "Invalid" 1944 "Invalid" 1943 "Invalid" 1942 "Invalid" 1941 "Invalid" 1940 "Invalid" 1939 "Invalid" 1938 "Invalid" 1937 "Invalid" 1936 "Invalid" 1935 "Invalid" 1934 "Invalid" 1933 "Invalid" 1932 "Invalid" 1931 "Invalid" 1930 "Invalid" 1929 "Invalid" 1928 "Invalid" 1927 "Invalid" 1926 "Invalid" 1925 "Invalid" 1924 "Invalid" 1923 "Invalid" 1922 "Invalid" 1921 "Invalid" 1920 "Invalid" 1919 "Invalid" 1918 "Invalid" 1917 "Invalid" 1916 "Invalid" 1915 "Invalid" 1914 "Invalid" 1913 "Invalid" 1912 "Invalid" 1911 "Invalid" 1910 "Invalid" 1909 "Invalid" 1908 "Invalid" 1907 "Invalid" 1906 "Invalid" 1905 "Invalid" 1904 "Invalid" 1903 "Invalid" 1902 "Invalid" 1901 "Invalid" 1900 "Invalid" 1899 "Invalid" 1898 "Invalid" 1897 "Invalid" 1896 "Invalid" 1895 "Invalid" 1894 "Invalid" 1893 "Invalid" 1892 "Invalid" 1891 "Invalid" 1890 "Invalid" 1889 "Invalid" 1888 "Invalid" 1887 "Invalid" 1886 "Invalid" 1885 "Invalid" 1884 "Invalid" 1883 "Invalid" 1882 "Invalid" 1881 "Invalid" 1880 "Invalid" 1879 "Invalid" 1878 "Invalid" 1877 "Invalid" 1876 "Invalid" 1875 "Invalid" 1874 "Invalid" 1873 "Invalid" 1872 "Invalid" 1871 "Invalid" 1870 "Invalid" 1869 "Invalid" 1868 "Invalid" 1867 "Invalid" 1866 "Invalid" 1865 "Invalid" 1864 "Invalid" 1863 "Invalid" 1862 "Invalid" 1861 "Invalid" 1860 "Invalid" 1859 "Invalid" 1858 "Invalid" 1857 "Invalid" 1856 "Invalid" 1855 "Invalid" 1854 "Invalid" 1853 "Invalid" 1852 "Invalid" 1851 "Invalid" 1850 "Invalid" 1849 "Invalid" 1848 "Invalid" 1847 "Invalid" 1846 "Invalid" 1845 "Invalid" 1844 "Invalid" 1843 "Invalid" 1842 "Invalid" 1841 "Invalid" 1840 "Invalid" 1839 "Invalid" 1838 "Invalid" 1837 "Invalid" 1836 "Invalid" 1835 "Invalid" 1834 "Invalid" 1833 "Invalid" 1832 "Invalid" 1831 "Invalid" 1830 "Invalid" 1829 "Invalid" 1828 "Invalid" 1827 "Invalid" 1826 "Invalid" 1825 "Invalid" 1824 "Invalid" 1823 "Invalid" 1822 "Invalid" 1821 "Invalid" 1820 "Invalid" 1819 "Invalid" 1818 "Invalid" 1817 "Invalid" 1816 "Invalid" 1815 "Invalid" 1814 "Invalid" 1813 "Invalid" 1812 "Invalid" 1811 "Invalid" 1810 "Invalid" 1809 "Invalid" 1808 "Invalid" 1807 "Invalid" 1806 "Invalid" 1805 "Invalid" 1804 "Invalid" 1803 "Invalid" 1802 "Invalid" 1801 "Invalid" ;
VAL_ 1057 BCU_CellVlt073_RM 2047 "Invalid" 2046 "Invalid" 2045 "Invalid" 2044 "Invalid" 2043 "Invalid" 2042 "Invalid" 2041 "Invalid" 2040 "Invalid" 2039 "Invalid" 2038 "Invalid" 2037 "Invalid" 2036 "Invalid" 2035 "Invalid" 2034 "Invalid" 2033 "Invalid" 2032 "Invalid" 2031 "Invalid" 2030 "Invalid" 2029 "Invalid" 2028 "Invalid" 2027 "Invalid" 2026 "Invalid" 2025 "Invalid" 2024 "Invalid" 2023 "Invalid" 2022 "Invalid" 2021 "Invalid" 2020 "Invalid" 2019 "Invalid" 2018 "Invalid" 2017 "Invalid" 2016 "Invalid" 2015 "Invalid" 2014 "Invalid" 2013 "Invalid" 2012 "Invalid" 2011 "Invalid" 2010 "Invalid" 2009 "Invalid" 2008 "Invalid" 2007 "Invalid" 2006 "Invalid" 2005 "Invalid" 2004 "Invalid" 2003 "Invalid" 2002 "Invalid" 2001 "Invalid" 2000 "Invalid" 1999 "Invalid" 1998 "Invalid" 1997 "Invalid" 1996 "Invalid" 1995 "Invalid" 1994 "Invalid" 1993 "Invalid" 1992 "Invalid" 1991 "Invalid" 1990 "Invalid" 1989 "Invalid" 1988 "Invalid" 1987 "Invalid" 1986 "Invalid" 1985 "Invalid" 1984 "Invalid" 1983 "Invalid" 1982 "Invalid" 1981 "Invalid" 1980 "Invalid" 1979 "Invalid" 1978 "Invalid" 1977 "Invalid" 1976 "Invalid" 1975 "Invalid" 1974 "Invalid" 1973 "Invalid" 1972 "Invalid" 1971 "Invalid" 1970 "Invalid" 1969 "Invalid" 1968 "Invalid" 1967 "Invalid" 1966 "Invalid" 1965 "Invalid" 1964 "Invalid" 1963 "Invalid" 1962 "Invalid" 1961 "Invalid" 1960 "Invalid" 1959 "Invalid" 1958 "Invalid" 1957 "Invalid" 1956 "Invalid" 1955 "Invalid" 1954 "Invalid" 1953 "Invalid" 1952 "Invalid" 1951 "Invalid" 1950 "Invalid" 1949 "Invalid" 1948 "Invalid" 1947 "Invalid" 1946 "Invalid" 1945 "Invalid" 1944 "Invalid" 1943 "Invalid" 1942 "Invalid" 1941 "Invalid" 1940 "Invalid" 1939 "Invalid" 1938 "Invalid" 1937 "Invalid" 1936 "Invalid" 1935 "Invalid" 1934 "Invalid" 1933 "Invalid" 1932 "Invalid" 1931 "Invalid" 1930 "Invalid" 1929 "Invalid" 1928 "Invalid" 1927 "Invalid" 1926 "Invalid" 1925 "Invalid" 1924 "Invalid" 1923 "Invalid" 1922 "Invalid" 1921 "Invalid" 1920 "Invalid" 1919 "Invalid" 1918 "Invalid" 1917 "Invalid" 1916 "Invalid" 1915 "Invalid" 1914 "Invalid" 1913 "Invalid" 1912 "Invalid" 1911 "Invalid" 1910 "Invalid" 1909 "Invalid" 1908 "Invalid" 1907 "Invalid" 1906 "Invalid" 1905 "Invalid" 1904 "Invalid" 1903 "Invalid" 1902 "Invalid" 1901 "Invalid" 1900 "Invalid" 1899 "Invalid" 1898 "Invalid" 1897 "Invalid" 1896 "Invalid" 1895 "Invalid" 1894 "Invalid" 1893 "Invalid" 1892 "Invalid" 1891 "Invalid" 1890 "Invalid" 1889 "Invalid" 1888 "Invalid" 1887 "Invalid" 1886 "Invalid" 1885 "Invalid" 1884 "Invalid" 1883 "Invalid" 1882 "Invalid" 1881 "Invalid" 1880 "Invalid" 1879 "Invalid" 1878 "Invalid" 1877 "Invalid" 1876 "Invalid" 1875 "Invalid" 1874 "Invalid" 1873 "Invalid" 1872 "Invalid" 1871 "Invalid" 1870 "Invalid" 1869 "Invalid" 1868 "Invalid" 1867 "Invalid" 1866 "Invalid" 1865 "Invalid" 1864 "Invalid" 1863 "Invalid" 1862 "Invalid" 1861 "Invalid" 1860 "Invalid" 1859 "Invalid" 1858 "Invalid" 1857 "Invalid" 1856 "Invalid" 1855 "Invalid" 1854 "Invalid" 1853 "Invalid" 1852 "Invalid" 1851 "Invalid" 1850 "Invalid" 1849 "Invalid" 1848 "Invalid" 1847 "Invalid" 1846 "Invalid" 1845 "Invalid" 1844 "Invalid" 1843 "Invalid" 1842 "Invalid" 1841 "Invalid" 1840 "Invalid" 1839 "Invalid" 1838 "Invalid" 1837 "Invalid" 1836 "Invalid" 1835 "Invalid" 1834 "Invalid" 1833 "Invalid" 1832 "Invalid" 1831 "Invalid" 1830 "Invalid" 1829 "Invalid" 1828 "Invalid" 1827 "Invalid" 1826 "Invalid" 1825 "Invalid" 1824 "Invalid" 1823 "Invalid" 1822 "Invalid" 1821 "Invalid" 1820 "Invalid" 1819 "Invalid" 1818 "Invalid" 1817 "Invalid" 1816 "Invalid" 1815 "Invalid" 1814 "Invalid" 1813 "Invalid" 1812 "Invalid" 1811 "Invalid" 1810 "Invalid" 1809 "Invalid" 1808 "Invalid" 1807 "Invalid" 1806 "Invalid" 1805 "Invalid" 1804 "Invalid" 1803 "Invalid" 1802 "Invalid" 1801 "Invalid" ;
VAL_ 1057 BCU_CellVlt074_RM 2047 "Invalid" 2046 "Invalid" 2045 "Invalid" 2044 "Invalid" 2043 "Invalid" 2042 "Invalid" 2041 "Invalid" 2040 "Invalid" 2039 "Invalid" 2038 "Invalid" 2037 "Invalid" 2036 "Invalid" 2035 "Invalid" 2034 "Invalid" 2033 "Invalid" 2032 "Invalid" 2031 "Invalid" 2030 "Invalid" 2029 "Invalid" 2028 "Invalid" 2027 "Invalid" 2026 "Invalid" 2025 "Invalid" 2024 "Invalid" 2023 "Invalid" 2022 "Invalid" 2021 "Invalid" 2020 "Invalid" 2019 "Invalid" 2018 "Invalid" 2017 "Invalid" 2016 "Invalid" 2015 "Invalid" 2014 "Invalid" 2013 "Invalid" 2012 "Invalid" 2011 "Invalid" 2010 "Invalid" 2009 "Invalid" 2008 "Invalid" 2007 "Invalid" 2006 "Invalid" 2005 "Invalid" 2004 "Invalid" 2003 "Invalid" 2002 "Invalid" 2001 "Invalid" 2000 "Invalid" 1999 "Invalid" 1998 "Invalid" 1997 "Invalid" 1996 "Invalid" 1995 "Invalid" 1994 "Invalid" 1993 "Invalid" 1992 "Invalid" 1991 "Invalid" 1990 "Invalid" 1989 "Invalid" 1988 "Invalid" 1987 "Invalid" 1986 "Invalid" 1985 "Invalid" 1984 "Invalid" 1983 "Invalid" 1982 "Invalid" 1981 "Invalid" 1980 "Invalid" 1979 "Invalid" 1978 "Invalid" 1977 "Invalid" 1976 "Invalid" 1975 "Invalid" 1974 "Invalid" 1973 "Invalid" 1972 "Invalid" 1971 "Invalid" 1970 "Invalid" 1969 "Invalid" 1968 "Invalid" 1967 "Invalid" 1966 "Invalid" 1965 "Invalid" 1964 "Invalid" 1963 "Invalid" 1962 "Invalid" 1961 "Invalid" 1960 "Invalid" 1959 "Invalid" 1958 "Invalid" 1957 "Invalid" 1956 "Invalid" 1955 "Invalid" 1954 "Invalid" 1953 "Invalid" 1952 "Invalid" 1951 "Invalid" 1950 "Invalid" 1949 "Invalid" 1948 "Invalid" 1947 "Invalid" 1946 "Invalid" 1945 "Invalid" 1944 "Invalid" 1943 "Invalid" 1942 "Invalid" 1941 "Invalid" 1940 "Invalid" 1939 "Invalid" 1938 "Invalid" 1937 "Invalid" 1936 "Invalid" 1935 "Invalid" 1934 "Invalid" 1933 "Invalid" 1932 "Invalid" 1931 "Invalid" 1930 "Invalid" 1929 "Invalid" 1928 "Invalid" 1927 "Invalid" 1926 "Invalid" 1925 "Invalid" 1924 "Invalid" 1923 "Invalid" 1922 "Invalid" 1921 "Invalid" 1920 "Invalid" 1919 "Invalid" 1918 "Invalid" 1917 "Invalid" 1916 "Invalid" 1915 "Invalid" 1914 "Invalid" 1913 "Invalid" 1912 "Invalid" 1911 "Invalid" 1910 "Invalid" 1909 "Invalid" 1908 "Invalid" 1907 "Invalid" 1906 "Invalid" 1905 "Invalid" 1904 "Invalid" 1903 "Invalid" 1902 "Invalid" 1901 "Invalid" 1900 "Invalid" 1899 "Invalid" 1898 "Invalid" 1897 "Invalid" 1896 "Invalid" 1895 "Invalid" 1894 "Invalid" 1893 "Invalid" 1892 "Invalid" 1891 "Invalid" 1890 "Invalid" 1889 "Invalid" 1888 "Invalid" 1887 "Invalid" 1886 "Invalid" 1885 "Invalid" 1884 "Invalid" 1883 "Invalid" 1882 "Invalid" 1881 "Invalid" 1880 "Invalid" 1879 "Invalid" 1878 "Invalid" 1877 "Invalid" 1876 "Invalid" 1875 "Invalid" 1874 "Invalid" 1873 "Invalid" 1872 "Invalid" 1871 "Invalid" 1870 "Invalid" 1869 "Invalid" 1868 "Invalid" 1867 "Invalid" 1866 "Invalid" 1865 "Invalid" 1864 "Invalid" 1863 "Invalid" 1862 "Invalid" 1861 "Invalid" 1860 "Invalid" 1859 "Invalid" 1858 "Invalid" 1857 "Invalid" 1856 "Invalid" 1855 "Invalid" 1854 "Invalid" 1853 "Invalid" 1852 "Invalid" 1851 "Invalid" 1850 "Invalid" 1849 "Invalid" 1848 "Invalid" 1847 "Invalid" 1846 "Invalid" 1845 "Invalid" 1844 "Invalid" 1843 "Invalid" 1842 "Invalid" 1841 "Invalid" 1840 "Invalid" 1839 "Invalid" 1838 "Invalid" 1837 "Invalid" 1836 "Invalid" 1835 "Invalid" 1834 "Invalid" 1833 "Invalid" 1832 "Invalid" 1831 "Invalid" 1830 "Invalid" 1829 "Invalid" 1828 "Invalid" 1827 "Invalid" 1826 "Invalid" 1825 "Invalid" 1824 "Invalid" 1823 "Invalid" 1822 "Invalid" 1821 "Invalid" 1820 "Invalid" 1819 "Invalid" 1818 "Invalid" 1817 "Invalid" 1816 "Invalid" 1815 "Invalid" 1814 "Invalid" 1813 "Invalid" 1812 "Invalid" 1811 "Invalid" 1810 "Invalid" 1809 "Invalid" 1808 "Invalid" 1807 "Invalid" 1806 "Invalid" 1805 "Invalid" 1804 "Invalid" 1803 "Invalid" 1802 "Invalid" 1801 "Invalid" ;
VAL_ 1057 BCU_CellVlt075_RM 2047 "Invalid" 2046 "Invalid" 2045 "Invalid" 2044 "Invalid" 2043 "Invalid" 2042 "Invalid" 2041 "Invalid" 2040 "Invalid" 2039 "Invalid" 2038 "Invalid" 2037 "Invalid" 2036 "Invalid" 2035 "Invalid" 2034 "Invalid" 2033 "Invalid" 2032 "Invalid" 2031 "Invalid" 2030 "Invalid" 2029 "Invalid" 2028 "Invalid" 2027 "Invalid" 2026 "Invalid" 2025 "Invalid" 2024 "Invalid" 2023 "Invalid" 2022 "Invalid" 2021 "Invalid" 2020 "Invalid" 2019 "Invalid" 2018 "Invalid" 2017 "Invalid" 2016 "Invalid" 2015 "Invalid" 2014 "Invalid" 2013 "Invalid" 2012 "Invalid" 2011 "Invalid" 2010 "Invalid" 2009 "Invalid" 2008 "Invalid" 2007 "Invalid" 2006 "Invalid" 2005 "Invalid" 2004 "Invalid" 2003 "Invalid" 2002 "Invalid" 2001 "Invalid" 2000 "Invalid" 1999 "Invalid" 1998 "Invalid" 1997 "Invalid" 1996 "Invalid" 1995 "Invalid" 1994 "Invalid" 1993 "Invalid" 1992 "Invalid" 1991 "Invalid" 1990 "Invalid" 1989 "Invalid" 1988 "Invalid" 1987 "Invalid" 1986 "Invalid" 1985 "Invalid" 1984 "Invalid" 1983 "Invalid" 1982 "Invalid" 1981 "Invalid" 1980 "Invalid" 1979 "Invalid" 1978 "Invalid" 1977 "Invalid" 1976 "Invalid" 1975 "Invalid" 1974 "Invalid" 1973 "Invalid" 1972 "Invalid" 1971 "Invalid" 1970 "Invalid" 1969 "Invalid" 1968 "Invalid" 1967 "Invalid" 1966 "Invalid" 1965 "Invalid" 1964 "Invalid" 1963 "Invalid" 1962 "Invalid" 1961 "Invalid" 1960 "Invalid" 1959 "Invalid" 1958 "Invalid" 1957 "Invalid" 1956 "Invalid" 1955 "Invalid" 1954 "Invalid" 1953 "Invalid" 1952 "Invalid" 1951 "Invalid" 1950 "Invalid" 1949 "Invalid" 1948 "Invalid" 1947 "Invalid" 1946 "Invalid" 1945 "Invalid" 1944 "Invalid" 1943 "Invalid" 1942 "Invalid" 1941 "Invalid" 1940 "Invalid" 1939 "Invalid" 1938 "Invalid" 1937 "Invalid" 1936 "Invalid" 1935 "Invalid" 1934 "Invalid" 1933 "Invalid" 1932 "Invalid" 1931 "Invalid" 1930 "Invalid" 1929 "Invalid" 1928 "Invalid" 1927 "Invalid" 1926 "Invalid" 1925 "Invalid" 1924 "Invalid" 1923 "Invalid" 1922 "Invalid" 1921 "Invalid" 1920 "Invalid" 1919 "Invalid" 1918 "Invalid" 1917 "Invalid" 1916 "Invalid" 1915 "Invalid" 1914 "Invalid" 1913 "Invalid" 1912 "Invalid" 1911 "Invalid" 1910 "Invalid" 1909 "Invalid" 1908 "Invalid" 1907 "Invalid" 1906 "Invalid" 1905 "Invalid" 1904 "Invalid" 1903 "Invalid" 1902 "Invalid" 1901 "Invalid" 1900 "Invalid" 1899 "Invalid" 1898 "Invalid" 1897 "Invalid" 1896 "Invalid" 1895 "Invalid" 1894 "Invalid" 1893 "Invalid" 1892 "Invalid" 1891 "Invalid" 1890 "Invalid" 1889 "Invalid" 1888 "Invalid" 1887 "Invalid" 1886 "Invalid" 1885 "Invalid" 1884 "Invalid" 1883 "Invalid" 1882 "Invalid" 1881 "Invalid" 1880 "Invalid" 1879 "Invalid" 1878 "Invalid" 1877 "Invalid" 1876 "Invalid" 1875 "Invalid" 1874 "Invalid" 1873 "Invalid" 1872 "Invalid" 1871 "Invalid" 1870 "Invalid" 1869 "Invalid" 1868 "Invalid" 1867 "Invalid" 1866 "Invalid" 1865 "Invalid" 1864 "Invalid" 1863 "Invalid" 1862 "Invalid" 1861 "Invalid" 1860 "Invalid" 1859 "Invalid" 1858 "Invalid" 1857 "Invalid" 1856 "Invalid" 1855 "Invalid" 1854 "Invalid" 1853 "Invalid" 1852 "Invalid" 1851 "Invalid" 1850 "Invalid" 1849 "Invalid" 1848 "Invalid" 1847 "Invalid" 1846 "Invalid" 1845 "Invalid" 1844 "Invalid" 1843 "Invalid" 1842 "Invalid" 1841 "Invalid" 1840 "Invalid" 1839 "Invalid" 1838 "Invalid" 1837 "Invalid" 1836 "Invalid" 1835 "Invalid" 1834 "Invalid" 1833 "Invalid" 1832 "Invalid" 1831 "Invalid" 1830 "Invalid" 1829 "Invalid" 1828 "Invalid" 1827 "Invalid" 1826 "Invalid" 1825 "Invalid" 1824 "Invalid" 1823 "Invalid" 1822 "Invalid" 1821 "Invalid" 1820 "Invalid" 1819 "Invalid" 1818 "Invalid" 1817 "Invalid" 1816 "Invalid" 1815 "Invalid" 1814 "Invalid" 1813 "Invalid" 1812 "Invalid" 1811 "Invalid" 1810 "Invalid" 1809 "Invalid" 1808 "Invalid" 1807 "Invalid" 1806 "Invalid" 1805 "Invalid" 1804 "Invalid" 1803 "Invalid" 1802 "Invalid" 1801 "Invalid" ;
VAL_ 1057 BCU_CellTmp015_RM 255 "Invalid" 254 "Invalid" 253 "Invalid" 252 "Invalid" 251 "Invalid" 250 "Invalid" 249 "Invalid" 248 "Invalid" 247 "Invalid" 246 "Invalid" 245 "Invalid" 244 "Invalid" 243 "Invalid" 242 "Invalid" 241 "Invalid" 240 "Invalid" 239 "Invalid" 238 "Invalid" 237 "Invalid" 236 "Invalid" 235 "Invalid" 234 "Invalid" 233 "Invalid" 232 "Invalid" 231 "Invalid" 230 "Invalid" 229 "Invalid" 228 "Invalid" 227 "Invalid" 226 "Invalid" 225 "Invalid" 224 "Invalid" 223 "Invalid" 222 "Invalid" 221 "Invalid" 220 "Invalid" 219 "Invalid" 218 "Invalid" 217 "Invalid" 216 "Invalid" 215 "Invalid" 214 "Invalid" 213 "Invalid" 212 "Invalid" 211 "Invalid" 210 "Invalid" 209 "Invalid" 208 "Invalid" 207 "Invalid" 206 "Invalid" 205 "Invalid" 204 "Invalid" 203 "Invalid" 202 "Invalid" 201 "Invalid" 200 "Invalid" 199 "Invalid" 198 "Invalid" 197 "Invalid" 196 "Invalid" 195 "Invalid" 194 "Invalid" 193 "Invalid" 192 "Invalid" 191 "Invalid" 190 "Invalid" 189 "Invalid" 188 "Invalid" 187 "Invalid" 186 "Invalid" 185 "Invalid" 184 "Invalid" 183 "Invalid" 182 "Invalid" 181 "Invalid" 180 "Invalid" 179 "Invalid" 178 "Invalid" 177 "Invalid" 176 "Invalid" 175 "Invalid" 174 "Invalid" 173 "Invalid" 172 "Invalid" 171 "Invalid" 170 "Invalid" 169 "Invalid" 168 "Invalid" 167 "Invalid" 166 "Invalid" 165 "Invalid" 164 "Invalid" 163 "Invalid" 162 "Invalid" 161 "Invalid" ;
VAL_ 1058 BCU_CellVlt076_RM 2047 "Invalid" 2046 "Invalid" 2045 "Invalid" 2044 "Invalid" 2043 "Invalid" 2042 "Invalid" 2041 "Invalid" 2040 "Invalid" 2039 "Invalid" 2038 "Invalid" 2037 "Invalid" 2036 "Invalid" 2035 "Invalid" 2034 "Invalid" 2033 "Invalid" 2032 "Invalid" 2031 "Invalid" 2030 "Invalid" 2029 "Invalid" 2028 "Invalid" 2027 "Invalid" 2026 "Invalid" 2025 "Invalid" 2024 "Invalid" 2023 "Invalid" 2022 "Invalid" 2021 "Invalid" 2020 "Invalid" 2019 "Invalid" 2018 "Invalid" 2017 "Invalid" 2016 "Invalid" 2015 "Invalid" 2014 "Invalid" 2013 "Invalid" 2012 "Invalid" 2011 "Invalid" 2010 "Invalid" 2009 "Invalid" 2008 "Invalid" 2007 "Invalid" 2006 "Invalid" 2005 "Invalid" 2004 "Invalid" 2003 "Invalid" 2002 "Invalid" 2001 "Invalid" 2000 "Invalid" 1999 "Invalid" 1998 "Invalid" 1997 "Invalid" 1996 "Invalid" 1995 "Invalid" 1994 "Invalid" 1993 "Invalid" 1992 "Invalid" 1991 "Invalid" 1990 "Invalid" 1989 "Invalid" 1988 "Invalid" 1987 "Invalid" 1986 "Invalid" 1985 "Invalid" 1984 "Invalid" 1983 "Invalid" 1982 "Invalid" 1981 "Invalid" 1980 "Invalid" 1979 "Invalid" 1978 "Invalid" 1977 "Invalid" 1976 "Invalid" 1975 "Invalid" 1974 "Invalid" 1973 "Invalid" 1972 "Invalid" 1971 "Invalid" 1970 "Invalid" 1969 "Invalid" 1968 "Invalid" 1967 "Invalid" 1966 "Invalid" 1965 "Invalid" 1964 "Invalid" 1963 "Invalid" 1962 "Invalid" 1961 "Invalid" 1960 "Invalid" 1959 "Invalid" 1958 "Invalid" 1957 "Invalid" 1956 "Invalid" 1955 "Invalid" 1954 "Invalid" 1953 "Invalid" 1952 "Invalid" 1951 "Invalid" 1950 "Invalid" 1949 "Invalid" 1948 "Invalid" 1947 "Invalid" 1946 "Invalid" 1945 "Invalid" 1944 "Invalid" 1943 "Invalid" 1942 "Invalid" 1941 "Invalid" 1940 "Invalid" 1939 "Invalid" 1938 "Invalid" 1937 "Invalid" 1936 "Invalid" 1935 "Invalid" 1934 "Invalid" 1933 "Invalid" 1932 "Invalid" 1931 "Invalid" 1930 "Invalid" 1929 "Invalid" 1928 "Invalid" 1927 "Invalid" 1926 "Invalid" 1925 "Invalid" 1924 "Invalid" 1923 "Invalid" 1922 "Invalid" 1921 "Invalid" 1920 "Invalid" 1919 "Invalid" 1918 "Invalid" 1917 "Invalid" 1916 "Invalid" 1915 "Invalid" 1914 "Invalid" 1913 "Invalid" 1912 "Invalid" 1911 "Invalid" 1910 "Invalid" 1909 "Invalid" 1908 "Invalid" 1907 "Invalid" 1906 "Invalid" 1905 "Invalid" 1904 "Invalid" 1903 "Invalid" 1902 "Invalid" 1901 "Invalid" 1900 "Invalid" 1899 "Invalid" 1898 "Invalid" 1897 "Invalid" 1896 "Invalid" 1895 "Invalid" 1894 "Invalid" 1893 "Invalid" 1892 "Invalid" 1891 "Invalid" 1890 "Invalid" 1889 "Invalid" 1888 "Invalid" 1887 "Invalid" 1886 "Invalid" 1885 "Invalid" 1884 "Invalid" 1883 "Invalid" 1882 "Invalid" 1881 "Invalid" 1880 "Invalid" 1879 "Invalid" 1878 "Invalid" 1877 "Invalid" 1876 "Invalid" 1875 "Invalid" 1874 "Invalid" 1873 "Invalid" 1872 "Invalid" 1871 "Invalid" 1870 "Invalid" 1869 "Invalid" 1868 "Invalid" 1867 "Invalid" 1866 "Invalid" 1865 "Invalid" 1864 "Invalid" 1863 "Invalid" 1862 "Invalid" 1861 "Invalid" 1860 "Invalid" 1859 "Invalid" 1858 "Invalid" 1857 "Invalid" 1856 "Invalid" 1855 "Invalid" 1854 "Invalid" 1853 "Invalid" 1852 "Invalid" 1851 "Invalid" 1850 "Invalid" 1849 "Invalid" 1848 "Invalid" 1847 "Invalid" 1846 "Invalid" 1845 "Invalid" 1844 "Invalid" 1843 "Invalid" 1842 "Invalid" 1841 "Invalid" 1840 "Invalid" 1839 "Invalid" 1838 "Invalid" 1837 "Invalid" 1836 "Invalid" 1835 "Invalid" 1834 "Invalid" 1833 "Invalid" 1832 "Invalid" 1831 "Invalid" 1830 "Invalid" 1829 "Invalid" 1828 "Invalid" 1827 "Invalid" 1826 "Invalid" 1825 "Invalid" 1824 "Invalid" 1823 "Invalid" 1822 "Invalid" 1821 "Invalid" 1820 "Invalid" 1819 "Invalid" 1818 "Invalid" 1817 "Invalid" 1816 "Invalid" 1815 "Invalid" 1814 "Invalid" 1813 "Invalid" 1812 "Invalid" 1811 "Invalid" 1810 "Invalid" 1809 "Invalid" 1808 "Invalid" 1807 "Invalid" 1806 "Invalid" 1805 "Invalid" 1804 "Invalid" 1803 "Invalid" 1802 "Invalid" 1801 "Invalid" ;
VAL_ 1058 BCU_CellVlt077_RM 2047 "Invalid" 2046 "Invalid" 2045 "Invalid" 2044 "Invalid" 2043 "Invalid" 2042 "Invalid" 2041 "Invalid" 2040 "Invalid" 2039 "Invalid" 2038 "Invalid" 2037 "Invalid" 2036 "Invalid" 2035 "Invalid" 2034 "Invalid" 2033 "Invalid" 2032 "Invalid" 2031 "Invalid" 2030 "Invalid" 2029 "Invalid" 2028 "Invalid" 2027 "Invalid" 2026 "Invalid" 2025 "Invalid" 2024 "Invalid" 2023 "Invalid" 2022 "Invalid" 2021 "Invalid" 2020 "Invalid" 2019 "Invalid" 2018 "Invalid" 2017 "Invalid" 2016 "Invalid" 2015 "Invalid" 2014 "Invalid" 2013 "Invalid" 2012 "Invalid" 2011 "Invalid" 2010 "Invalid" 2009 "Invalid" 2008 "Invalid" 2007 "Invalid" 2006 "Invalid" 2005 "Invalid" 2004 "Invalid" 2003 "Invalid" 2002 "Invalid" 2001 "Invalid" 2000 "Invalid" 1999 "Invalid" 1998 "Invalid" 1997 "Invalid" 1996 "Invalid" 1995 "Invalid" 1994 "Invalid" 1993 "Invalid" 1992 "Invalid" 1991 "Invalid" 1990 "Invalid" 1989 "Invalid" 1988 "Invalid" 1987 "Invalid" 1986 "Invalid" 1985 "Invalid" 1984 "Invalid" 1983 "Invalid" 1982 "Invalid" 1981 "Invalid" 1980 "Invalid" 1979 "Invalid" 1978 "Invalid" 1977 "Invalid" 1976 "Invalid" 1975 "Invalid" 1974 "Invalid" 1973 "Invalid" 1972 "Invalid" 1971 "Invalid" 1970 "Invalid" 1969 "Invalid" 1968 "Invalid" 1967 "Invalid" 1966 "Invalid" 1965 "Invalid" 1964 "Invalid" 1963 "Invalid" 1962 "Invalid" 1961 "Invalid" 1960 "Invalid" 1959 "Invalid" 1958 "Invalid" 1957 "Invalid" 1956 "Invalid" 1955 "Invalid" 1954 "Invalid" 1953 "Invalid" 1952 "Invalid" 1951 "Invalid" 1950 "Invalid" 1949 "Invalid" 1948 "Invalid" 1947 "Invalid" 1946 "Invalid" 1945 "Invalid" 1944 "Invalid" 1943 "Invalid" 1942 "Invalid" 1941 "Invalid" 1940 "Invalid" 1939 "Invalid" 1938 "Invalid" 1937 "Invalid" 1936 "Invalid" 1935 "Invalid" 1934 "Invalid" 1933 "Invalid" 1932 "Invalid" 1931 "Invalid" 1930 "Invalid" 1929 "Invalid" 1928 "Invalid" 1927 "Invalid" 1926 "Invalid" 1925 "Invalid" 1924 "Invalid" 1923 "Invalid" 1922 "Invalid" 1921 "Invalid" 1920 "Invalid" 1919 "Invalid" 1918 "Invalid" 1917 "Invalid" 1916 "Invalid" 1915 "Invalid" 1914 "Invalid" 1913 "Invalid" 1912 "Invalid" 1911 "Invalid" 1910 "Invalid" 1909 "Invalid" 1908 "Invalid" 1907 "Invalid" 1906 "Invalid" 1905 "Invalid" 1904 "Invalid" 1903 "Invalid" 1902 "Invalid" 1901 "Invalid" 1900 "Invalid" 1899 "Invalid" 1898 "Invalid" 1897 "Invalid" 1896 "Invalid" 1895 "Invalid" 1894 "Invalid" 1893 "Invalid" 1892 "Invalid" 1891 "Invalid" 1890 "Invalid" 1889 "Invalid" 1888 "Invalid" 1887 "Invalid" 1886 "Invalid" 1885 "Invalid" 1884 "Invalid" 1883 "Invalid" 1882 "Invalid" 1881 "Invalid" 1880 "Invalid" 1879 "Invalid" 1878 "Invalid" 1877 "Invalid" 1876 "Invalid" 1875 "Invalid" 1874 "Invalid" 1873 "Invalid" 1872 "Invalid" 1871 "Invalid" 1870 "Invalid" 1869 "Invalid" 1868 "Invalid" 1867 "Invalid" 1866 "Invalid" 1865 "Invalid" 1864 "Invalid" 1863 "Invalid" 1862 "Invalid" 1861 "Invalid" 1860 "Invalid" 1859 "Invalid" 1858 "Invalid" 1857 "Invalid" 1856 "Invalid" 1855 "Invalid" 1854 "Invalid" 1853 "Invalid" 1852 "Invalid" 1851 "Invalid" 1850 "Invalid" 1849 "Invalid" 1848 "Invalid" 1847 "Invalid" 1846 "Invalid" 1845 "Invalid" 1844 "Invalid" 1843 "Invalid" 1842 "Invalid" 1841 "Invalid" 1840 "Invalid" 1839 "Invalid" 1838 "Invalid" 1837 "Invalid" 1836 "Invalid" 1835 "Invalid" 1834 "Invalid" 1833 "Invalid" 1832 "Invalid" 1831 "Invalid" 1830 "Invalid" 1829 "Invalid" 1828 "Invalid" 1827 "Invalid" 1826 "Invalid" 1825 "Invalid" 1824 "Invalid" 1823 "Invalid" 1822 "Invalid" 1821 "Invalid" 1820 "Invalid" 1819 "Invalid" 1818 "Invalid" 1817 "Invalid" 1816 "Invalid" 1815 "Invalid" 1814 "Invalid" 1813 "Invalid" 1812 "Invalid" 1811 "Invalid" 1810 "Invalid" 1809 "Invalid" 1808 "Invalid" 1807 "Invalid" 1806 "Invalid" 1805 "Invalid" 1804 "Invalid" 1803 "Invalid" 1802 "Invalid" 1801 "Invalid" ;
VAL_ 1058 BCU_CellVlt078_RM 2047 "Invalid" 2046 "Invalid" 2045 "Invalid" 2044 "Invalid" 2043 "Invalid" 2042 "Invalid" 2041 "Invalid" 2040 "Invalid" 2039 "Invalid" 2038 "Invalid" 2037 "Invalid" 2036 "Invalid" 2035 "Invalid" 2034 "Invalid" 2033 "Invalid" 2032 "Invalid" 2031 "Invalid" 2030 "Invalid" 2029 "Invalid" 2028 "Invalid" 2027 "Invalid" 2026 "Invalid" 2025 "Invalid" 2024 "Invalid" 2023 "Invalid" 2022 "Invalid" 2021 "Invalid" 2020 "Invalid" 2019 "Invalid" 2018 "Invalid" 2017 "Invalid" 2016 "Invalid" 2015 "Invalid" 2014 "Invalid" 2013 "Invalid" 2012 "Invalid" 2011 "Invalid" 2010 "Invalid" 2009 "Invalid" 2008 "Invalid" 2007 "Invalid" 2006 "Invalid" 2005 "Invalid" 2004 "Invalid" 2003 "Invalid" 2002 "Invalid" 2001 "Invalid" 2000 "Invalid" 1999 "Invalid" 1998 "Invalid" 1997 "Invalid" 1996 "Invalid" 1995 "Invalid" 1994 "Invalid" 1993 "Invalid" 1992 "Invalid" 1991 "Invalid" 1990 "Invalid" 1989 "Invalid" 1988 "Invalid" 1987 "Invalid" 1986 "Invalid" 1985 "Invalid" 1984 "Invalid" 1983 "Invalid" 1982 "Invalid" 1981 "Invalid" 1980 "Invalid" 1979 "Invalid" 1978 "Invalid" 1977 "Invalid" 1976 "Invalid" 1975 "Invalid" 1974 "Invalid" 1973 "Invalid" 1972 "Invalid" 1971 "Invalid" 1970 "Invalid" 1969 "Invalid" 1968 "Invalid" 1967 "Invalid" 1966 "Invalid" 1965 "Invalid" 1964 "Invalid" 1963 "Invalid" 1962 "Invalid" 1961 "Invalid" 1960 "Invalid" 1959 "Invalid" 1958 "Invalid" 1957 "Invalid" 1956 "Invalid" 1955 "Invalid" 1954 "Invalid" 1953 "Invalid" 1952 "Invalid" 1951 "Invalid" 1950 "Invalid" 1949 "Invalid" 1948 "Invalid" 1947 "Invalid" 1946 "Invalid" 1945 "Invalid" 1944 "Invalid" 1943 "Invalid" 1942 "Invalid" 1941 "Invalid" 1940 "Invalid" 1939 "Invalid" 1938 "Invalid" 1937 "Invalid" 1936 "Invalid" 1935 "Invalid" 1934 "Invalid" 1933 "Invalid" 1932 "Invalid" 1931 "Invalid" 1930 "Invalid" 1929 "Invalid" 1928 "Invalid" 1927 "Invalid" 1926 "Invalid" 1925 "Invalid" 1924 "Invalid" 1923 "Invalid" 1922 "Invalid" 1921 "Invalid" 1920 "Invalid" 1919 "Invalid" 1918 "Invalid" 1917 "Invalid" 1916 "Invalid" 1915 "Invalid" 1914 "Invalid" 1913 "Invalid" 1912 "Invalid" 1911 "Invalid" 1910 "Invalid" 1909 "Invalid" 1908 "Invalid" 1907 "Invalid" 1906 "Invalid" 1905 "Invalid" 1904 "Invalid" 1903 "Invalid" 1902 "Invalid" 1901 "Invalid" 1900 "Invalid" 1899 "Invalid" 1898 "Invalid" 1897 "Invalid" 1896 "Invalid" 1895 "Invalid" 1894 "Invalid" 1893 "Invalid" 1892 "Invalid" 1891 "Invalid" 1890 "Invalid" 1889 "Invalid" 1888 "Invalid" 1887 "Invalid" 1886 "Invalid" 1885 "Invalid" 1884 "Invalid" 1883 "Invalid" 1882 "Invalid" 1881 "Invalid" 1880 "Invalid" 1879 "Invalid" 1878 "Invalid" 1877 "Invalid" 1876 "Invalid" 1875 "Invalid" 1874 "Invalid" 1873 "Invalid" 1872 "Invalid" 1871 "Invalid" 1870 "Invalid" 1869 "Invalid" 1868 "Invalid" 1867 "Invalid" 1866 "Invalid" 1865 "Invalid" 1864 "Invalid" 1863 "Invalid" 1862 "Invalid" 1861 "Invalid" 1860 "Invalid" 1859 "Invalid" 1858 "Invalid" 1857 "Invalid" 1856 "Invalid" 1855 "Invalid" 1854 "Invalid" 1853 "Invalid" 1852 "Invalid" 1851 "Invalid" 1850 "Invalid" 1849 "Invalid" 1848 "Invalid" 1847 "Invalid" 1846 "Invalid" 1845 "Invalid" 1844 "Invalid" 1843 "Invalid" 1842 "Invalid" 1841 "Invalid" 1840 "Invalid" 1839 "Invalid" 1838 "Invalid" 1837 "Invalid" 1836 "Invalid" 1835 "Invalid" 1834 "Invalid" 1833 "Invalid" 1832 "Invalid" 1831 "Invalid" 1830 "Invalid" 1829 "Invalid" 1828 "Invalid" 1827 "Invalid" 1826 "Invalid" 1825 "Invalid" 1824 "Invalid" 1823 "Invalid" 1822 "Invalid" 1821 "Invalid" 1820 "Invalid" 1819 "Invalid" 1818 "Invalid" 1817 "Invalid" 1816 "Invalid" 1815 "Invalid" 1814 "Invalid" 1813 "Invalid" 1812 "Invalid" 1811 "Invalid" 1810 "Invalid" 1809 "Invalid" 1808 "Invalid" 1807 "Invalid" 1806 "Invalid" 1805 "Invalid" 1804 "Invalid" 1803 "Invalid" 1802 "Invalid" 1801 "Invalid" ;
VAL_ 1058 BCU_CellVlt079_RM 2047 "Invalid" 2046 "Invalid" 2045 "Invalid" 2044 "Invalid" 2043 "Invalid" 2042 "Invalid" 2041 "Invalid" 2040 "Invalid" 2039 "Invalid" 2038 "Invalid" 2037 "Invalid" 2036 "Invalid" 2035 "Invalid" 2034 "Invalid" 2033 "Invalid" 2032 "Invalid" 2031 "Invalid" 2030 "Invalid" 2029 "Invalid" 2028 "Invalid" 2027 "Invalid" 2026 "Invalid" 2025 "Invalid" 2024 "Invalid" 2023 "Invalid" 2022 "Invalid" 2021 "Invalid" 2020 "Invalid" 2019 "Invalid" 2018 "Invalid" 2017 "Invalid" 2016 "Invalid" 2015 "Invalid" 2014 "Invalid" 2013 "Invalid" 2012 "Invalid" 2011 "Invalid" 2010 "Invalid" 2009 "Invalid" 2008 "Invalid" 2007 "Invalid" 2006 "Invalid" 2005 "Invalid" 2004 "Invalid" 2003 "Invalid" 2002 "Invalid" 2001 "Invalid" 2000 "Invalid" 1999 "Invalid" 1998 "Invalid" 1997 "Invalid" 1996 "Invalid" 1995 "Invalid" 1994 "Invalid" 1993 "Invalid" 1992 "Invalid" 1991 "Invalid" 1990 "Invalid" 1989 "Invalid" 1988 "Invalid" 1987 "Invalid" 1986 "Invalid" 1985 "Invalid" 1984 "Invalid" 1983 "Invalid" 1982 "Invalid" 1981 "Invalid" 1980 "Invalid" 1979 "Invalid" 1978 "Invalid" 1977 "Invalid" 1976 "Invalid" 1975 "Invalid" 1974 "Invalid" 1973 "Invalid" 1972 "Invalid" 1971 "Invalid" 1970 "Invalid" 1969 "Invalid" 1968 "Invalid" 1967 "Invalid" 1966 "Invalid" 1965 "Invalid" 1964 "Invalid" 1963 "Invalid" 1962 "Invalid" 1961 "Invalid" 1960 "Invalid" 1959 "Invalid" 1958 "Invalid" 1957 "Invalid" 1956 "Invalid" 1955 "Invalid" 1954 "Invalid" 1953 "Invalid" 1952 "Invalid" 1951 "Invalid" 1950 "Invalid" 1949 "Invalid" 1948 "Invalid" 1947 "Invalid" 1946 "Invalid" 1945 "Invalid" 1944 "Invalid" 1943 "Invalid" 1942 "Invalid" 1941 "Invalid" 1940 "Invalid" 1939 "Invalid" 1938 "Invalid" 1937 "Invalid" 1936 "Invalid" 1935 "Invalid" 1934 "Invalid" 1933 "Invalid" 1932 "Invalid" 1931 "Invalid" 1930 "Invalid" 1929 "Invalid" 1928 "Invalid" 1927 "Invalid" 1926 "Invalid" 1925 "Invalid" 1924 "Invalid" 1923 "Invalid" 1922 "Invalid" 1921 "Invalid" 1920 "Invalid" 1919 "Invalid" 1918 "Invalid" 1917 "Invalid" 1916 "Invalid" 1915 "Invalid" 1914 "Invalid" 1913 "Invalid" 1912 "Invalid" 1911 "Invalid" 1910 "Invalid" 1909 "Invalid" 1908 "Invalid" 1907 "Invalid" 1906 "Invalid" 1905 "Invalid" 1904 "Invalid" 1903 "Invalid" 1902 "Invalid" 1901 "Invalid" 1900 "Invalid" 1899 "Invalid" 1898 "Invalid" 1897 "Invalid" 1896 "Invalid" 1895 "Invalid" 1894 "Invalid" 1893 "Invalid" 1892 "Invalid" 1891 "Invalid" 1890 "Invalid" 1889 "Invalid" 1888 "Invalid" 1887 "Invalid" 1886 "Invalid" 1885 "Invalid" 1884 "Invalid" 1883 "Invalid" 1882 "Invalid" 1881 "Invalid" 1880 "Invalid" 1879 "Invalid" 1878 "Invalid" 1877 "Invalid" 1876 "Invalid" 1875 "Invalid" 1874 "Invalid" 1873 "Invalid" 1872 "Invalid" 1871 "Invalid" 1870 "Invalid" 1869 "Invalid" 1868 "Invalid" 1867 "Invalid" 1866 "Invalid" 1865 "Invalid" 1864 "Invalid" 1863 "Invalid" 1862 "Invalid" 1861 "Invalid" 1860 "Invalid" 1859 "Invalid" 1858 "Invalid" 1857 "Invalid" 1856 "Invalid" 1855 "Invalid" 1854 "Invalid" 1853 "Invalid" 1852 "Invalid" 1851 "Invalid" 1850 "Invalid" 1849 "Invalid" 1848 "Invalid" 1847 "Invalid" 1846 "Invalid" 1845 "Invalid" 1844 "Invalid" 1843 "Invalid" 1842 "Invalid" 1841 "Invalid" 1840 "Invalid" 1839 "Invalid" 1838 "Invalid" 1837 "Invalid" 1836 "Invalid" 1835 "Invalid" 1834 "Invalid" 1833 "Invalid" 1832 "Invalid" 1831 "Invalid" 1830 "Invalid" 1829 "Invalid" 1828 "Invalid" 1827 "Invalid" 1826 "Invalid" 1825 "Invalid" 1824 "Invalid" 1823 "Invalid" 1822 "Invalid" 1821 "Invalid" 1820 "Invalid" 1819 "Invalid" 1818 "Invalid" 1817 "Invalid" 1816 "Invalid" 1815 "Invalid" 1814 "Invalid" 1813 "Invalid" 1812 "Invalid" 1811 "Invalid" 1810 "Invalid" 1809 "Invalid" 1808 "Invalid" 1807 "Invalid" 1806 "Invalid" 1805 "Invalid" 1804 "Invalid" 1803 "Invalid" 1802 "Invalid" 1801 "Invalid" ;
VAL_ 1058 BCU_CellVlt080_RM 2047 "Invalid" 2046 "Invalid" 2045 "Invalid" 2044 "Invalid" 2043 "Invalid" 2042 "Invalid" 2041 "Invalid" 2040 "Invalid" 2039 "Invalid" 2038 "Invalid" 2037 "Invalid" 2036 "Invalid" 2035 "Invalid" 2034 "Invalid" 2033 "Invalid" 2032 "Invalid" 2031 "Invalid" 2030 "Invalid" 2029 "Invalid" 2028 "Invalid" 2027 "Invalid" 2026 "Invalid" 2025 "Invalid" 2024 "Invalid" 2023 "Invalid" 2022 "Invalid" 2021 "Invalid" 2020 "Invalid" 2019 "Invalid" 2018 "Invalid" 2017 "Invalid" 2016 "Invalid" 2015 "Invalid" 2014 "Invalid" 2013 "Invalid" 2012 "Invalid" 2011 "Invalid" 2010 "Invalid" 2009 "Invalid" 2008 "Invalid" 2007 "Invalid" 2006 "Invalid" 2005 "Invalid" 2004 "Invalid" 2003 "Invalid" 2002 "Invalid" 2001 "Invalid" 2000 "Invalid" 1999 "Invalid" 1998 "Invalid" 1997 "Invalid" 1996 "Invalid" 1995 "Invalid" 1994 "Invalid" 1993 "Invalid" 1992 "Invalid" 1991 "Invalid" 1990 "Invalid" 1989 "Invalid" 1988 "Invalid" 1987 "Invalid" 1986 "Invalid" 1985 "Invalid" 1984 "Invalid" 1983 "Invalid" 1982 "Invalid" 1981 "Invalid" 1980 "Invalid" 1979 "Invalid" 1978 "Invalid" 1977 "Invalid" 1976 "Invalid" 1975 "Invalid" 1974 "Invalid" 1973 "Invalid" 1972 "Invalid" 1971 "Invalid" 1970 "Invalid" 1969 "Invalid" 1968 "Invalid" 1967 "Invalid" 1966 "Invalid" 1965 "Invalid" 1964 "Invalid" 1963 "Invalid" 1962 "Invalid" 1961 "Invalid" 1960 "Invalid" 1959 "Invalid" 1958 "Invalid" 1957 "Invalid" 1956 "Invalid" 1955 "Invalid" 1954 "Invalid" 1953 "Invalid" 1952 "Invalid" 1951 "Invalid" 1950 "Invalid" 1949 "Invalid" 1948 "Invalid" 1947 "Invalid" 1946 "Invalid" 1945 "Invalid" 1944 "Invalid" 1943 "Invalid" 1942 "Invalid" 1941 "Invalid" 1940 "Invalid" 1939 "Invalid" 1938 "Invalid" 1937 "Invalid" 1936 "Invalid" 1935 "Invalid" 1934 "Invalid" 1933 "Invalid" 1932 "Invalid" 1931 "Invalid" 1930 "Invalid" 1929 "Invalid" 1928 "Invalid" 1927 "Invalid" 1926 "Invalid" 1925 "Invalid" 1924 "Invalid" 1923 "Invalid" 1922 "Invalid" 1921 "Invalid" 1920 "Invalid" 1919 "Invalid" 1918 "Invalid" 1917 "Invalid" 1916 "Invalid" 1915 "Invalid" 1914 "Invalid" 1913 "Invalid" 1912 "Invalid" 1911 "Invalid" 1910 "Invalid" 1909 "Invalid" 1908 "Invalid" 1907 "Invalid" 1906 "Invalid" 1905 "Invalid" 1904 "Invalid" 1903 "Invalid" 1902 "Invalid" 1901 "Invalid" 1900 "Invalid" 1899 "Invalid" 1898 "Invalid" 1897 "Invalid" 1896 "Invalid" 1895 "Invalid" 1894 "Invalid" 1893 "Invalid" 1892 "Invalid" 1891 "Invalid" 1890 "Invalid" 1889 "Invalid" 1888 "Invalid" 1887 "Invalid" 1886 "Invalid" 1885 "Invalid" 1884 "Invalid" 1883 "Invalid" 1882 "Invalid" 1881 "Invalid" 1880 "Invalid" 1879 "Invalid" 1878 "Invalid" 1877 "Invalid" 1876 "Invalid" 1875 "Invalid" 1874 "Invalid" 1873 "Invalid" 1872 "Invalid" 1871 "Invalid" 1870 "Invalid" 1869 "Invalid" 1868 "Invalid" 1867 "Invalid" 1866 "Invalid" 1865 "Invalid" 1864 "Invalid" 1863 "Invalid" 1862 "Invalid" 1861 "Invalid" 1860 "Invalid" 1859 "Invalid" 1858 "Invalid" 1857 "Invalid" 1856 "Invalid" 1855 "Invalid" 1854 "Invalid" 1853 "Invalid" 1852 "Invalid" 1851 "Invalid" 1850 "Invalid" 1849 "Invalid" 1848 "Invalid" 1847 "Invalid" 1846 "Invalid" 1845 "Invalid" 1844 "Invalid" 1843 "Invalid" 1842 "Invalid" 1841 "Invalid" 1840 "Invalid" 1839 "Invalid" 1838 "Invalid" 1837 "Invalid" 1836 "Invalid" 1835 "Invalid" 1834 "Invalid" 1833 "Invalid" 1832 "Invalid" 1831 "Invalid" 1830 "Invalid" 1829 "Invalid" 1828 "Invalid" 1827 "Invalid" 1826 "Invalid" 1825 "Invalid" 1824 "Invalid" 1823 "Invalid" 1822 "Invalid" 1821 "Invalid" 1820 "Invalid" 1819 "Invalid" 1818 "Invalid" 1817 "Invalid" 1816 "Invalid" 1815 "Invalid" 1814 "Invalid" 1813 "Invalid" 1812 "Invalid" 1811 "Invalid" 1810 "Invalid" 1809 "Invalid" 1808 "Invalid" 1807 "Invalid" 1806 "Invalid" 1805 "Invalid" 1804 "Invalid" 1803 "Invalid" 1802 "Invalid" 1801 "Invalid" ;
VAL_ 1058 BCU_CellTmp016_RM 255 "Invalid" 254 "Invalid" 253 "Invalid" 252 "Invalid" 251 "Invalid" 250 "Invalid" 249 "Invalid" 248 "Invalid" 247 "Invalid" 246 "Invalid" 245 "Invalid" 244 "Invalid" 243 "Invalid" 242 "Invalid" 241 "Invalid" 240 "Invalid" 239 "Invalid" 238 "Invalid" 237 "Invalid" 236 "Invalid" 235 "Invalid" 234 "Invalid" 233 "Invalid" 232 "Invalid" 231 "Invalid" 230 "Invalid" 229 "Invalid" 228 "Invalid" 227 "Invalid" 226 "Invalid" 225 "Invalid" 224 "Invalid" 223 "Invalid" 222 "Invalid" 221 "Invalid" 220 "Invalid" 219 "Invalid" 218 "Invalid" 217 "Invalid" 216 "Invalid" 215 "Invalid" 214 "Invalid" 213 "Invalid" 212 "Invalid" 211 "Invalid" 210 "Invalid" 209 "Invalid" 208 "Invalid" 207 "Invalid" 206 "Invalid" 205 "Invalid" 204 "Invalid" 203 "Invalid" 202 "Invalid" 201 "Invalid" 200 "Invalid" 199 "Invalid" 198 "Invalid" 197 "Invalid" 196 "Invalid" 195 "Invalid" 194 "Invalid" 193 "Invalid" 192 "Invalid" 191 "Invalid" 190 "Invalid" 189 "Invalid" 188 "Invalid" 187 "Invalid" 186 "Invalid" 185 "Invalid" 184 "Invalid" 183 "Invalid" 182 "Invalid" 181 "Invalid" 180 "Invalid" 179 "Invalid" 178 "Invalid" 177 "Invalid" 176 "Invalid" 175 "Invalid" 174 "Invalid" 173 "Invalid" 172 "Invalid" 171 "Invalid" 170 "Invalid" 169 "Invalid" 168 "Invalid" 167 "Invalid" 166 "Invalid" 165 "Invalid" 164 "Invalid" 163 "Invalid" 162 "Invalid" 161 "Invalid" ;
VAL_ 1059 BCU_CellVlt081_RM 2047 "Invalid" 2046 "Invalid" 2045 "Invalid" 2044 "Invalid" 2043 "Invalid" 2042 "Invalid" 2041 "Invalid" 2040 "Invalid" 2039 "Invalid" 2038 "Invalid" 2037 "Invalid" 2036 "Invalid" 2035 "Invalid" 2034 "Invalid" 2033 "Invalid" 2032 "Invalid" 2031 "Invalid" 2030 "Invalid" 2029 "Invalid" 2028 "Invalid" 2027 "Invalid" 2026 "Invalid" 2025 "Invalid" 2024 "Invalid" 2023 "Invalid" 2022 "Invalid" 2021 "Invalid" 2020 "Invalid" 2019 "Invalid" 2018 "Invalid" 2017 "Invalid" 2016 "Invalid" 2015 "Invalid" 2014 "Invalid" 2013 "Invalid" 2012 "Invalid" 2011 "Invalid" 2010 "Invalid" 2009 "Invalid" 2008 "Invalid" 2007 "Invalid" 2006 "Invalid" 2005 "Invalid" 2004 "Invalid" 2003 "Invalid" 2002 "Invalid" 2001 "Invalid" 2000 "Invalid" 1999 "Invalid" 1998 "Invalid" 1997 "Invalid" 1996 "Invalid" 1995 "Invalid" 1994 "Invalid" 1993 "Invalid" 1992 "Invalid" 1991 "Invalid" 1990 "Invalid" 1989 "Invalid" 1988 "Invalid" 1987 "Invalid" 1986 "Invalid" 1985 "Invalid" 1984 "Invalid" 1983 "Invalid" 1982 "Invalid" 1981 "Invalid" 1980 "Invalid" 1979 "Invalid" 1978 "Invalid" 1977 "Invalid" 1976 "Invalid" 1975 "Invalid" 1974 "Invalid" 1973 "Invalid" 1972 "Invalid" 1971 "Invalid" 1970 "Invalid" 1969 "Invalid" 1968 "Invalid" 1967 "Invalid" 1966 "Invalid" 1965 "Invalid" 1964 "Invalid" 1963 "Invalid" 1962 "Invalid" 1961 "Invalid" 1960 "Invalid" 1959 "Invalid" 1958 "Invalid" 1957 "Invalid" 1956 "Invalid" 1955 "Invalid" 1954 "Invalid" 1953 "Invalid" 1952 "Invalid" 1951 "Invalid" 1950 "Invalid" 1949 "Invalid" 1948 "Invalid" 1947 "Invalid" 1946 "Invalid" 1945 "Invalid" 1944 "Invalid" 1943 "Invalid" 1942 "Invalid" 1941 "Invalid" 1940 "Invalid" 1939 "Invalid" 1938 "Invalid" 1937 "Invalid" 1936 "Invalid" 1935 "Invalid" 1934 "Invalid" 1933 "Invalid" 1932 "Invalid" 1931 "Invalid" 1930 "Invalid" 1929 "Invalid" 1928 "Invalid" 1927 "Invalid" 1926 "Invalid" 1925 "Invalid" 1924 "Invalid" 1923 "Invalid" 1922 "Invalid" 1921 "Invalid" 1920 "Invalid" 1919 "Invalid" 1918 "Invalid" 1917 "Invalid" 1916 "Invalid" 1915 "Invalid" 1914 "Invalid" 1913 "Invalid" 1912 "Invalid" 1911 "Invalid" 1910 "Invalid" 1909 "Invalid" 1908 "Invalid" 1907 "Invalid" 1906 "Invalid" 1905 "Invalid" 1904 "Invalid" 1903 "Invalid" 1902 "Invalid" 1901 "Invalid" 1900 "Invalid" 1899 "Invalid" 1898 "Invalid" 1897 "Invalid" 1896 "Invalid" 1895 "Invalid" 1894 "Invalid" 1893 "Invalid" 1892 "Invalid" 1891 "Invalid" 1890 "Invalid" 1889 "Invalid" 1888 "Invalid" 1887 "Invalid" 1886 "Invalid" 1885 "Invalid" 1884 "Invalid" 1883 "Invalid" 1882 "Invalid" 1881 "Invalid" 1880 "Invalid" 1879 "Invalid" 1878 "Invalid" 1877 "Invalid" 1876 "Invalid" 1875 "Invalid" 1874 "Invalid" 1873 "Invalid" 1872 "Invalid" 1871 "Invalid" 1870 "Invalid" 1869 "Invalid" 1868 "Invalid" 1867 "Invalid" 1866 "Invalid" 1865 "Invalid" 1864 "Invalid" 1863 "Invalid" 1862 "Invalid" 1861 "Invalid" 1860 "Invalid" 1859 "Invalid" 1858 "Invalid" 1857 "Invalid" 1856 "Invalid" 1855 "Invalid" 1854 "Invalid" 1853 "Invalid" 1852 "Invalid" 1851 "Invalid" 1850 "Invalid" 1849 "Invalid" 1848 "Invalid" 1847 "Invalid" 1846 "Invalid" 1845 "Invalid" 1844 "Invalid" 1843 "Invalid" 1842 "Invalid" 1841 "Invalid" 1840 "Invalid" 1839 "Invalid" 1838 "Invalid" 1837 "Invalid" 1836 "Invalid" 1835 "Invalid" 1834 "Invalid" 1833 "Invalid" 1832 "Invalid" 1831 "Invalid" 1830 "Invalid" 1829 "Invalid" 1828 "Invalid" 1827 "Invalid" 1826 "Invalid" 1825 "Invalid" 1824 "Invalid" 1823 "Invalid" 1822 "Invalid" 1821 "Invalid" 1820 "Invalid" 1819 "Invalid" 1818 "Invalid" 1817 "Invalid" 1816 "Invalid" 1815 "Invalid" 1814 "Invalid" 1813 "Invalid" 1812 "Invalid" 1811 "Invalid" 1810 "Invalid" 1809 "Invalid" 1808 "Invalid" 1807 "Invalid" 1806 "Invalid" 1805 "Invalid" 1804 "Invalid" 1803 "Invalid" 1802 "Invalid" 1801 "Invalid" ;
VAL_ 1059 BCU_CellVlt082_RM 2047 "Invalid" 2046 "Invalid" 2045 "Invalid" 2044 "Invalid" 2043 "Invalid" 2042 "Invalid" 2041 "Invalid" 2040 "Invalid" 2039 "Invalid" 2038 "Invalid" 2037 "Invalid" 2036 "Invalid" 2035 "Invalid" 2034 "Invalid" 2033 "Invalid" 2032 "Invalid" 2031 "Invalid" 2030 "Invalid" 2029 "Invalid" 2028 "Invalid" 2027 "Invalid" 2026 "Invalid" 2025 "Invalid" 2024 "Invalid" 2023 "Invalid" 2022 "Invalid" 2021 "Invalid" 2020 "Invalid" 2019 "Invalid" 2018 "Invalid" 2017 "Invalid" 2016 "Invalid" 2015 "Invalid" 2014 "Invalid" 2013 "Invalid" 2012 "Invalid" 2011 "Invalid" 2010 "Invalid" 2009 "Invalid" 2008 "Invalid" 2007 "Invalid" 2006 "Invalid" 2005 "Invalid" 2004 "Invalid" 2003 "Invalid" 2002 "Invalid" 2001 "Invalid" 2000 "Invalid" 1999 "Invalid" 1998 "Invalid" 1997 "Invalid" 1996 "Invalid" 1995 "Invalid" 1994 "Invalid" 1993 "Invalid" 1992 "Invalid" 1991 "Invalid" 1990 "Invalid" 1989 "Invalid" 1988 "Invalid" 1987 "Invalid" 1986 "Invalid" 1985 "Invalid" 1984 "Invalid" 1983 "Invalid" 1982 "Invalid" 1981 "Invalid" 1980 "Invalid" 1979 "Invalid" 1978 "Invalid" 1977 "Invalid" 1976 "Invalid" 1975 "Invalid" 1974 "Invalid" 1973 "Invalid" 1972 "Invalid" 1971 "Invalid" 1970 "Invalid" 1969 "Invalid" 1968 "Invalid" 1967 "Invalid" 1966 "Invalid" 1965 "Invalid" 1964 "Invalid" 1963 "Invalid" 1962 "Invalid" 1961 "Invalid" 1960 "Invalid" 1959 "Invalid" 1958 "Invalid" 1957 "Invalid" 1956 "Invalid" 1955 "Invalid" 1954 "Invalid" 1953 "Invalid" 1952 "Invalid" 1951 "Invalid" 1950 "Invalid" 1949 "Invalid" 1948 "Invalid" 1947 "Invalid" 1946 "Invalid" 1945 "Invalid" 1944 "Invalid" 1943 "Invalid" 1942 "Invalid" 1941 "Invalid" 1940 "Invalid" 1939 "Invalid" 1938 "Invalid" 1937 "Invalid" 1936 "Invalid" 1935 "Invalid" 1934 "Invalid" 1933 "Invalid" 1932 "Invalid" 1931 "Invalid" 1930 "Invalid" 1929 "Invalid" 1928 "Invalid" 1927 "Invalid" 1926 "Invalid" 1925 "Invalid" 1924 "Invalid" 1923 "Invalid" 1922 "Invalid" 1921 "Invalid" 1920 "Invalid" 1919 "Invalid" 1918 "Invalid" 1917 "Invalid" 1916 "Invalid" 1915 "Invalid" 1914 "Invalid" 1913 "Invalid" 1912 "Invalid" 1911 "Invalid" 1910 "Invalid" 1909 "Invalid" 1908 "Invalid" 1907 "Invalid" 1906 "Invalid" 1905 "Invalid" 1904 "Invalid" 1903 "Invalid" 1902 "Invalid" 1901 "Invalid" 1900 "Invalid" 1899 "Invalid" 1898 "Invalid" 1897 "Invalid" 1896 "Invalid" 1895 "Invalid" 1894 "Invalid" 1893 "Invalid" 1892 "Invalid" 1891 "Invalid" 1890 "Invalid" 1889 "Invalid" 1888 "Invalid" 1887 "Invalid" 1886 "Invalid" 1885 "Invalid" 1884 "Invalid" 1883 "Invalid" 1882 "Invalid" 1881 "Invalid" 1880 "Invalid" 1879 "Invalid" 1878 "Invalid" 1877 "Invalid" 1876 "Invalid" 1875 "Invalid" 1874 "Invalid" 1873 "Invalid" 1872 "Invalid" 1871 "Invalid" 1870 "Invalid" 1869 "Invalid" 1868 "Invalid" 1867 "Invalid" 1866 "Invalid" 1865 "Invalid" 1864 "Invalid" 1863 "Invalid" 1862 "Invalid" 1861 "Invalid" 1860 "Invalid" 1859 "Invalid" 1858 "Invalid" 1857 "Invalid" 1856 "Invalid" 1855 "Invalid" 1854 "Invalid" 1853 "Invalid" 1852 "Invalid" 1851 "Invalid" 1850 "Invalid" 1849 "Invalid" 1848 "Invalid" 1847 "Invalid" 1846 "Invalid" 1845 "Invalid" 1844 "Invalid" 1843 "Invalid" 1842 "Invalid" 1841 "Invalid" 1840 "Invalid" 1839 "Invalid" 1838 "Invalid" 1837 "Invalid" 1836 "Invalid" 1835 "Invalid" 1834 "Invalid" 1833 "Invalid" 1832 "Invalid" 1831 "Invalid" 1830 "Invalid" 1829 "Invalid" 1828 "Invalid" 1827 "Invalid" 1826 "Invalid" 1825 "Invalid" 1824 "Invalid" 1823 "Invalid" 1822 "Invalid" 1821 "Invalid" 1820 "Invalid" 1819 "Invalid" 1818 "Invalid" 1817 "Invalid" 1816 "Invalid" 1815 "Invalid" 1814 "Invalid" 1813 "Invalid" 1812 "Invalid" 1811 "Invalid" 1810 "Invalid" 1809 "Invalid" 1808 "Invalid" 1807 "Invalid" 1806 "Invalid" 1805 "Invalid" 1804 "Invalid" 1803 "Invalid" 1802 "Invalid" 1801 "Invalid" ;
VAL_ 1059 BCU_CellVlt083_RM 2047 "Invalid" 2046 "Invalid" 2045 "Invalid" 2044 "Invalid" 2043 "Invalid" 2042 "Invalid" 2041 "Invalid" 2040 "Invalid" 2039 "Invalid" 2038 "Invalid" 2037 "Invalid" 2036 "Invalid" 2035 "Invalid" 2034 "Invalid" 2033 "Invalid" 2032 "Invalid" 2031 "Invalid" 2030 "Invalid" 2029 "Invalid" 2028 "Invalid" 2027 "Invalid" 2026 "Invalid" 2025 "Invalid" 2024 "Invalid" 2023 "Invalid" 2022 "Invalid" 2021 "Invalid" 2020 "Invalid" 2019 "Invalid" 2018 "Invalid" 2017 "Invalid" 2016 "Invalid" 2015 "Invalid" 2014 "Invalid" 2013 "Invalid" 2012 "Invalid" 2011 "Invalid" 2010 "Invalid" 2009 "Invalid" 2008 "Invalid" 2007 "Invalid" 2006 "Invalid" 2005 "Invalid" 2004 "Invalid" 2003 "Invalid" 2002 "Invalid" 2001 "Invalid" 2000 "Invalid" 1999 "Invalid" 1998 "Invalid" 1997 "Invalid" 1996 "Invalid" 1995 "Invalid" 1994 "Invalid" 1993 "Invalid" 1992 "Invalid" 1991 "Invalid" 1990 "Invalid" 1989 "Invalid" 1988 "Invalid" 1987 "Invalid" 1986 "Invalid" 1985 "Invalid" 1984 "Invalid" 1983 "Invalid" 1982 "Invalid" 1981 "Invalid" 1980 "Invalid" 1979 "Invalid" 1978 "Invalid" 1977 "Invalid" 1976 "Invalid" 1975 "Invalid" 1974 "Invalid" 1973 "Invalid" 1972 "Invalid" 1971 "Invalid" 1970 "Invalid" 1969 "Invalid" 1968 "Invalid" 1967 "Invalid" 1966 "Invalid" 1965 "Invalid" 1964 "Invalid" 1963 "Invalid" 1962 "Invalid" 1961 "Invalid" 1960 "Invalid" 1959 "Invalid" 1958 "Invalid" 1957 "Invalid" 1956 "Invalid" 1955 "Invalid" 1954 "Invalid" 1953 "Invalid" 1952 "Invalid" 1951 "Invalid" 1950 "Invalid" 1949 "Invalid" 1948 "Invalid" 1947 "Invalid" 1946 "Invalid" 1945 "Invalid" 1944 "Invalid" 1943 "Invalid" 1942 "Invalid" 1941 "Invalid" 1940 "Invalid" 1939 "Invalid" 1938 "Invalid" 1937 "Invalid" 1936 "Invalid" 1935 "Invalid" 1934 "Invalid" 1933 "Invalid" 1932 "Invalid" 1931 "Invalid" 1930 "Invalid" 1929 "Invalid" 1928 "Invalid" 1927 "Invalid" 1926 "Invalid" 1925 "Invalid" 1924 "Invalid" 1923 "Invalid" 1922 "Invalid" 1921 "Invalid" 1920 "Invalid" 1919 "Invalid" 1918 "Invalid" 1917 "Invalid" 1916 "Invalid" 1915 "Invalid" 1914 "Invalid" 1913 "Invalid" 1912 "Invalid" 1911 "Invalid" 1910 "Invalid" 1909 "Invalid" 1908 "Invalid" 1907 "Invalid" 1906 "Invalid" 1905 "Invalid" 1904 "Invalid" 1903 "Invalid" 1902 "Invalid" 1901 "Invalid" 1900 "Invalid" 1899 "Invalid" 1898 "Invalid" 1897 "Invalid" 1896 "Invalid" 1895 "Invalid" 1894 "Invalid" 1893 "Invalid" 1892 "Invalid" 1891 "Invalid" 1890 "Invalid" 1889 "Invalid" 1888 "Invalid" 1887 "Invalid" 1886 "Invalid" 1885 "Invalid" 1884 "Invalid" 1883 "Invalid" 1882 "Invalid" 1881 "Invalid" 1880 "Invalid" 1879 "Invalid" 1878 "Invalid" 1877 "Invalid" 1876 "Invalid" 1875 "Invalid" 1874 "Invalid" 1873 "Invalid" 1872 "Invalid" 1871 "Invalid" 1870 "Invalid" 1869 "Invalid" 1868 "Invalid" 1867 "Invalid" 1866 "Invalid" 1865 "Invalid" 1864 "Invalid" 1863 "Invalid" 1862 "Invalid" 1861 "Invalid" 1860 "Invalid" 1859 "Invalid" 1858 "Invalid" 1857 "Invalid" 1856 "Invalid" 1855 "Invalid" 1854 "Invalid" 1853 "Invalid" 1852 "Invalid" 1851 "Invalid" 1850 "Invalid" 1849 "Invalid" 1848 "Invalid" 1847 "Invalid" 1846 "Invalid" 1845 "Invalid" 1844 "Invalid" 1843 "Invalid" 1842 "Invalid" 1841 "Invalid" 1840 "Invalid" 1839 "Invalid" 1838 "Invalid" 1837 "Invalid" 1836 "Invalid" 1835 "Invalid" 1834 "Invalid" 1833 "Invalid" 1832 "Invalid" 1831 "Invalid" 1830 "Invalid" 1829 "Invalid" 1828 "Invalid" 1827 "Invalid" 1826 "Invalid" 1825 "Invalid" 1824 "Invalid" 1823 "Invalid" 1822 "Invalid" 1821 "Invalid" 1820 "Invalid" 1819 "Invalid" 1818 "Invalid" 1817 "Invalid" 1816 "Invalid" 1815 "Invalid" 1814 "Invalid" 1813 "Invalid" 1812 "Invalid" 1811 "Invalid" 1810 "Invalid" 1809 "Invalid" 1808 "Invalid" 1807 "Invalid" 1806 "Invalid" 1805 "Invalid" 1804 "Invalid" 1803 "Invalid" 1802 "Invalid" 1801 "Invalid" ;
VAL_ 1059 BCU_CellVlt084_RM 2047 "Invalid" 2046 "Invalid" 2045 "Invalid" 2044 "Invalid" 2043 "Invalid" 2042 "Invalid" 2041 "Invalid" 2040 "Invalid" 2039 "Invalid" 2038 "Invalid" 2037 "Invalid" 2036 "Invalid" 2035 "Invalid" 2034 "Invalid" 2033 "Invalid" 2032 "Invalid" 2031 "Invalid" 2030 "Invalid" 2029 "Invalid" 2028 "Invalid" 2027 "Invalid" 2026 "Invalid" 2025 "Invalid" 2024 "Invalid" 2023 "Invalid" 2022 "Invalid" 2021 "Invalid" 2020 "Invalid" 2019 "Invalid" 2018 "Invalid" 2017 "Invalid" 2016 "Invalid" 2015 "Invalid" 2014 "Invalid" 2013 "Invalid" 2012 "Invalid" 2011 "Invalid" 2010 "Invalid" 2009 "Invalid" 2008 "Invalid" 2007 "Invalid" 2006 "Invalid" 2005 "Invalid" 2004 "Invalid" 2003 "Invalid" 2002 "Invalid" 2001 "Invalid" 2000 "Invalid" 1999 "Invalid" 1998 "Invalid" 1997 "Invalid" 1996 "Invalid" 1995 "Invalid" 1994 "Invalid" 1993 "Invalid" 1992 "Invalid" 1991 "Invalid" 1990 "Invalid" 1989 "Invalid" 1988 "Invalid" 1987 "Invalid" 1986 "Invalid" 1985 "Invalid" 1984 "Invalid" 1983 "Invalid" 1982 "Invalid" 1981 "Invalid" 1980 "Invalid" 1979 "Invalid" 1978 "Invalid" 1977 "Invalid" 1976 "Invalid" 1975 "Invalid" 1974 "Invalid" 1973 "Invalid" 1972 "Invalid" 1971 "Invalid" 1970 "Invalid" 1969 "Invalid" 1968 "Invalid" 1967 "Invalid" 1966 "Invalid" 1965 "Invalid" 1964 "Invalid" 1963 "Invalid" 1962 "Invalid" 1961 "Invalid" 1960 "Invalid" 1959 "Invalid" 1958 "Invalid" 1957 "Invalid" 1956 "Invalid" 1955 "Invalid" 1954 "Invalid" 1953 "Invalid" 1952 "Invalid" 1951 "Invalid" 1950 "Invalid" 1949 "Invalid" 1948 "Invalid" 1947 "Invalid" 1946 "Invalid" 1945 "Invalid" 1944 "Invalid" 1943 "Invalid" 1942 "Invalid" 1941 "Invalid" 1940 "Invalid" 1939 "Invalid" 1938 "Invalid" 1937 "Invalid" 1936 "Invalid" 1935 "Invalid" 1934 "Invalid" 1933 "Invalid" 1932 "Invalid" 1931 "Invalid" 1930 "Invalid" 1929 "Invalid" 1928 "Invalid" 1927 "Invalid" 1926 "Invalid" 1925 "Invalid" 1924 "Invalid" 1923 "Invalid" 1922 "Invalid" 1921 "Invalid" 1920 "Invalid" 1919 "Invalid" 1918 "Invalid" 1917 "Invalid" 1916 "Invalid" 1915 "Invalid" 1914 "Invalid" 1913 "Invalid" 1912 "Invalid" 1911 "Invalid" 1910 "Invalid" 1909 "Invalid" 1908 "Invalid" 1907 "Invalid" 1906 "Invalid" 1905 "Invalid" 1904 "Invalid" 1903 "Invalid" 1902 "Invalid" 1901 "Invalid" 1900 "Invalid" 1899 "Invalid" 1898 "Invalid" 1897 "Invalid" 1896 "Invalid" 1895 "Invalid" 1894 "Invalid" 1893 "Invalid" 1892 "Invalid" 1891 "Invalid" 1890 "Invalid" 1889 "Invalid" 1888 "Invalid" 1887 "Invalid" 1886 "Invalid" 1885 "Invalid" 1884 "Invalid" 1883 "Invalid" 1882 "Invalid" 1881 "Invalid" 1880 "Invalid" 1879 "Invalid" 1878 "Invalid" 1877 "Invalid" 1876 "Invalid" 1875 "Invalid" 1874 "Invalid" 1873 "Invalid" 1872 "Invalid" 1871 "Invalid" 1870 "Invalid" 1869 "Invalid" 1868 "Invalid" 1867 "Invalid" 1866 "Invalid" 1865 "Invalid" 1864 "Invalid" 1863 "Invalid" 1862 "Invalid" 1861 "Invalid" 1860 "Invalid" 1859 "Invalid" 1858 "Invalid" 1857 "Invalid" 1856 "Invalid" 1855 "Invalid" 1854 "Invalid" 1853 "Invalid" 1852 "Invalid" 1851 "Invalid" 1850 "Invalid" 1849 "Invalid" 1848 "Invalid" 1847 "Invalid" 1846 "Invalid" 1845 "Invalid" 1844 "Invalid" 1843 "Invalid" 1842 "Invalid" 1841 "Invalid" 1840 "Invalid" 1839 "Invalid" 1838 "Invalid" 1837 "Invalid" 1836 "Invalid" 1835 "Invalid" 1834 "Invalid" 1833 "Invalid" 1832 "Invalid" 1831 "Invalid" 1830 "Invalid" 1829 "Invalid" 1828 "Invalid" 1827 "Invalid" 1826 "Invalid" 1825 "Invalid" 1824 "Invalid" 1823 "Invalid" 1822 "Invalid" 1821 "Invalid" 1820 "Invalid" 1819 "Invalid" 1818 "Invalid" 1817 "Invalid" 1816 "Invalid" 1815 "Invalid" 1814 "Invalid" 1813 "Invalid" 1812 "Invalid" 1811 "Invalid" 1810 "Invalid" 1809 "Invalid" 1808 "Invalid" 1807 "Invalid" 1806 "Invalid" 1805 "Invalid" 1804 "Invalid" 1803 "Invalid" 1802 "Invalid" 1801 "Invalid" ;
VAL_ 1059 BCU_CellVlt085_RM 2047 "Invalid" 2046 "Invalid" 2045 "Invalid" 2044 "Invalid" 2043 "Invalid" 2042 "Invalid" 2041 "Invalid" 2040 "Invalid" 2039 "Invalid" 2038 "Invalid" 2037 "Invalid" 2036 "Invalid" 2035 "Invalid" 2034 "Invalid" 2033 "Invalid" 2032 "Invalid" 2031 "Invalid" 2030 "Invalid" 2029 "Invalid" 2028 "Invalid" 2027 "Invalid" 2026 "Invalid" 2025 "Invalid" 2024 "Invalid" 2023 "Invalid" 2022 "Invalid" 2021 "Invalid" 2020 "Invalid" 2019 "Invalid" 2018 "Invalid" 2017 "Invalid" 2016 "Invalid" 2015 "Invalid" 2014 "Invalid" 2013 "Invalid" 2012 "Invalid" 2011 "Invalid" 2010 "Invalid" 2009 "Invalid" 2008 "Invalid" 2007 "Invalid" 2006 "Invalid" 2005 "Invalid" 2004 "Invalid" 2003 "Invalid" 2002 "Invalid" 2001 "Invalid" 2000 "Invalid" 1999 "Invalid" 1998 "Invalid" 1997 "Invalid" 1996 "Invalid" 1995 "Invalid" 1994 "Invalid" 1993 "Invalid" 1992 "Invalid" 1991 "Invalid" 1990 "Invalid" 1989 "Invalid" 1988 "Invalid" 1987 "Invalid" 1986 "Invalid" 1985 "Invalid" 1984 "Invalid" 1983 "Invalid" 1982 "Invalid" 1981 "Invalid" 1980 "Invalid" 1979 "Invalid" 1978 "Invalid" 1977 "Invalid" 1976 "Invalid" 1975 "Invalid" 1974 "Invalid" 1973 "Invalid" 1972 "Invalid" 1971 "Invalid" 1970 "Invalid" 1969 "Invalid" 1968 "Invalid" 1967 "Invalid" 1966 "Invalid" 1965 "Invalid" 1964 "Invalid" 1963 "Invalid" 1962 "Invalid" 1961 "Invalid" 1960 "Invalid" 1959 "Invalid" 1958 "Invalid" 1957 "Invalid" 1956 "Invalid" 1955 "Invalid" 1954 "Invalid" 1953 "Invalid" 1952 "Invalid" 1951 "Invalid" 1950 "Invalid" 1949 "Invalid" 1948 "Invalid" 1947 "Invalid" 1946 "Invalid" 1945 "Invalid" 1944 "Invalid" 1943 "Invalid" 1942 "Invalid" 1941 "Invalid" 1940 "Invalid" 1939 "Invalid" 1938 "Invalid" 1937 "Invalid" 1936 "Invalid" 1935 "Invalid" 1934 "Invalid" 1933 "Invalid" 1932 "Invalid" 1931 "Invalid" 1930 "Invalid" 1929 "Invalid" 1928 "Invalid" 1927 "Invalid" 1926 "Invalid" 1925 "Invalid" 1924 "Invalid" 1923 "Invalid" 1922 "Invalid" 1921 "Invalid" 1920 "Invalid" 1919 "Invalid" 1918 "Invalid" 1917 "Invalid" 1916 "Invalid" 1915 "Invalid" 1914 "Invalid" 1913 "Invalid" 1912 "Invalid" 1911 "Invalid" 1910 "Invalid" 1909 "Invalid" 1908 "Invalid" 1907 "Invalid" 1906 "Invalid" 1905 "Invalid" 1904 "Invalid" 1903 "Invalid" 1902 "Invalid" 1901 "Invalid" 1900 "Invalid" 1899 "Invalid" 1898 "Invalid" 1897 "Invalid" 1896 "Invalid" 1895 "Invalid" 1894 "Invalid" 1893 "Invalid" 1892 "Invalid" 1891 "Invalid" 1890 "Invalid" 1889 "Invalid" 1888 "Invalid" 1887 "Invalid" 1886 "Invalid" 1885 "Invalid" 1884 "Invalid" 1883 "Invalid" 1882 "Invalid" 1881 "Invalid" 1880 "Invalid" 1879 "Invalid" 1878 "Invalid" 1877 "Invalid" 1876 "Invalid" 1875 "Invalid" 1874 "Invalid" 1873 "Invalid" 1872 "Invalid" 1871 "Invalid" 1870 "Invalid" 1869 "Invalid" 1868 "Invalid" 1867 "Invalid" 1866 "Invalid" 1865 "Invalid" 1864 "Invalid" 1863 "Invalid" 1862 "Invalid" 1861 "Invalid" 1860 "Invalid" 1859 "Invalid" 1858 "Invalid" 1857 "Invalid" 1856 "Invalid" 1855 "Invalid" 1854 "Invalid" 1853 "Invalid" 1852 "Invalid" 1851 "Invalid" 1850 "Invalid" 1849 "Invalid" 1848 "Invalid" 1847 "Invalid" 1846 "Invalid" 1845 "Invalid" 1844 "Invalid" 1843 "Invalid" 1842 "Invalid" 1841 "Invalid" 1840 "Invalid" 1839 "Invalid" 1838 "Invalid" 1837 "Invalid" 1836 "Invalid" 1835 "Invalid" 1834 "Invalid" 1833 "Invalid" 1832 "Invalid" 1831 "Invalid" 1830 "Invalid" 1829 "Invalid" 1828 "Invalid" 1827 "Invalid" 1826 "Invalid" 1825 "Invalid" 1824 "Invalid" 1823 "Invalid" 1822 "Invalid" 1821 "Invalid" 1820 "Invalid" 1819 "Invalid" 1818 "Invalid" 1817 "Invalid" 1816 "Invalid" 1815 "Invalid" 1814 "Invalid" 1813 "Invalid" 1812 "Invalid" 1811 "Invalid" 1810 "Invalid" 1809 "Invalid" 1808 "Invalid" 1807 "Invalid" 1806 "Invalid" 1805 "Invalid" 1804 "Invalid" 1803 "Invalid" 1802 "Invalid" 1801 "Invalid" ;
VAL_ 1059 BCU_CellTmp017_RM 255 "Invalid" 254 "Invalid" 253 "Invalid" 252 "Invalid" 251 "Invalid" 250 "Invalid" 249 "Invalid" 248 "Invalid" 247 "Invalid" 246 "Invalid" 245 "Invalid" 244 "Invalid" 243 "Invalid" 242 "Invalid" 241 "Invalid" 240 "Invalid" 239 "Invalid" 238 "Invalid" 237 "Invalid" 236 "Invalid" 235 "Invalid" 234 "Invalid" 233 "Invalid" 232 "Invalid" 231 "Invalid" 230 "Invalid" 229 "Invalid" 228 "Invalid" 227 "Invalid" 226 "Invalid" 225 "Invalid" 224 "Invalid" 223 "Invalid" 222 "Invalid" 221 "Invalid" 220 "Invalid" 219 "Invalid" 218 "Invalid" 217 "Invalid" 216 "Invalid" 215 "Invalid" 214 "Invalid" 213 "Invalid" 212 "Invalid" 211 "Invalid" 210 "Invalid" 209 "Invalid" 208 "Invalid" 207 "Invalid" 206 "Invalid" 205 "Invalid" 204 "Invalid" 203 "Invalid" 202 "Invalid" 201 "Invalid" 200 "Invalid" 199 "Invalid" 198 "Invalid" 197 "Invalid" 196 "Invalid" 195 "Invalid" 194 "Invalid" 193 "Invalid" 192 "Invalid" 191 "Invalid" 190 "Invalid" 189 "Invalid" 188 "Invalid" 187 "Invalid" 186 "Invalid" 185 "Invalid" 184 "Invalid" 183 "Invalid" 182 "Invalid" 181 "Invalid" 180 "Invalid" 179 "Invalid" 178 "Invalid" 177 "Invalid" 176 "Invalid" 175 "Invalid" 174 "Invalid" 173 "Invalid" 172 "Invalid" 171 "Invalid" 170 "Invalid" 169 "Invalid" 168 "Invalid" 167 "Invalid" 166 "Invalid" 165 "Invalid" 164 "Invalid" 163 "Invalid" 162 "Invalid" 161 "Invalid" ;
VAL_ 1060 BCU_CellVlt086_RM 2047 "Invalid" 2046 "Invalid" 2045 "Invalid" 2044 "Invalid" 2043 "Invalid" 2042 "Invalid" 2041 "Invalid" 2040 "Invalid" 2039 "Invalid" 2038 "Invalid" 2037 "Invalid" 2036 "Invalid" 2035 "Invalid" 2034 "Invalid" 2033 "Invalid" 2032 "Invalid" 2031 "Invalid" 2030 "Invalid" 2029 "Invalid" 2028 "Invalid" 2027 "Invalid" 2026 "Invalid" 2025 "Invalid" 2024 "Invalid" 2023 "Invalid" 2022 "Invalid" 2021 "Invalid" 2020 "Invalid" 2019 "Invalid" 2018 "Invalid" 2017 "Invalid" 2016 "Invalid" 2015 "Invalid" 2014 "Invalid" 2013 "Invalid" 2012 "Invalid" 2011 "Invalid" 2010 "Invalid" 2009 "Invalid" 2008 "Invalid" 2007 "Invalid" 2006 "Invalid" 2005 "Invalid" 2004 "Invalid" 2003 "Invalid" 2002 "Invalid" 2001 "Invalid" 2000 "Invalid" 1999 "Invalid" 1998 "Invalid" 1997 "Invalid" 1996 "Invalid" 1995 "Invalid" 1994 "Invalid" 1993 "Invalid" 1992 "Invalid" 1991 "Invalid" 1990 "Invalid" 1989 "Invalid" 1988 "Invalid" 1987 "Invalid" 1986 "Invalid" 1985 "Invalid" 1984 "Invalid" 1983 "Invalid" 1982 "Invalid" 1981 "Invalid" 1980 "Invalid" 1979 "Invalid" 1978 "Invalid" 1977 "Invalid" 1976 "Invalid" 1975 "Invalid" 1974 "Invalid" 1973 "Invalid" 1972 "Invalid" 1971 "Invalid" 1970 "Invalid" 1969 "Invalid" 1968 "Invalid" 1967 "Invalid" 1966 "Invalid" 1965 "Invalid" 1964 "Invalid" 1963 "Invalid" 1962 "Invalid" 1961 "Invalid" 1960 "Invalid" 1959 "Invalid" 1958 "Invalid" 1957 "Invalid" 1956 "Invalid" 1955 "Invalid" 1954 "Invalid" 1953 "Invalid" 1952 "Invalid" 1951 "Invalid" 1950 "Invalid" 1949 "Invalid" 1948 "Invalid" 1947 "Invalid" 1946 "Invalid" 1945 "Invalid" 1944 "Invalid" 1943 "Invalid" 1942 "Invalid" 1941 "Invalid" 1940 "Invalid" 1939 "Invalid" 1938 "Invalid" 1937 "Invalid" 1936 "Invalid" 1935 "Invalid" 1934 "Invalid" 1933 "Invalid" 1932 "Invalid" 1931 "Invalid" 1930 "Invalid" 1929 "Invalid" 1928 "Invalid" 1927 "Invalid" 1926 "Invalid" 1925 "Invalid" 1924 "Invalid" 1923 "Invalid" 1922 "Invalid" 1921 "Invalid" 1920 "Invalid" 1919 "Invalid" 1918 "Invalid" 1917 "Invalid" 1916 "Invalid" 1915 "Invalid" 1914 "Invalid" 1913 "Invalid" 1912 "Invalid" 1911 "Invalid" 1910 "Invalid" 1909 "Invalid" 1908 "Invalid" 1907 "Invalid" 1906 "Invalid" 1905 "Invalid" 1904 "Invalid" 1903 "Invalid" 1902 "Invalid" 1901 "Invalid" 1900 "Invalid" 1899 "Invalid" 1898 "Invalid" 1897 "Invalid" 1896 "Invalid" 1895 "Invalid" 1894 "Invalid" 1893 "Invalid" 1892 "Invalid" 1891 "Invalid" 1890 "Invalid" 1889 "Invalid" 1888 "Invalid" 1887 "Invalid" 1886 "Invalid" 1885 "Invalid" 1884 "Invalid" 1883 "Invalid" 1882 "Invalid" 1881 "Invalid" 1880 "Invalid" 1879 "Invalid" 1878 "Invalid" 1877 "Invalid" 1876 "Invalid" 1875 "Invalid" 1874 "Invalid" 1873 "Invalid" 1872 "Invalid" 1871 "Invalid" 1870 "Invalid" 1869 "Invalid" 1868 "Invalid" 1867 "Invalid" 1866 "Invalid" 1865 "Invalid" 1864 "Invalid" 1863 "Invalid" 1862 "Invalid" 1861 "Invalid" 1860 "Invalid" 1859 "Invalid" 1858 "Invalid" 1857 "Invalid" 1856 "Invalid" 1855 "Invalid" 1854 "Invalid" 1853 "Invalid" 1852 "Invalid" 1851 "Invalid" 1850 "Invalid" 1849 "Invalid" 1848 "Invalid" 1847 "Invalid" 1846 "Invalid" 1845 "Invalid" 1844 "Invalid" 1843 "Invalid" 1842 "Invalid" 1841 "Invalid" 1840 "Invalid" 1839 "Invalid" 1838 "Invalid" 1837 "Invalid" 1836 "Invalid" 1835 "Invalid" 1834 "Invalid" 1833 "Invalid" 1832 "Invalid" 1831 "Invalid" 1830 "Invalid" 1829 "Invalid" 1828 "Invalid" 1827 "Invalid" 1826 "Invalid" 1825 "Invalid" 1824 "Invalid" 1823 "Invalid" 1822 "Invalid" 1821 "Invalid" 1820 "Invalid" 1819 "Invalid" 1818 "Invalid" 1817 "Invalid" 1816 "Invalid" 1815 "Invalid" 1814 "Invalid" 1813 "Invalid" 1812 "Invalid" 1811 "Invalid" 1810 "Invalid" 1809 "Invalid" 1808 "Invalid" 1807 "Invalid" 1806 "Invalid" 1805 "Invalid" 1804 "Invalid" 1803 "Invalid" 1802 "Invalid" 1801 "Invalid" ;
VAL_ 1060 BCU_CellVlt087_RM 2047 "Invalid" 2046 "Invalid" 2045 "Invalid" 2044 "Invalid" 2043 "Invalid" 2042 "Invalid" 2041 "Invalid" 2040 "Invalid" 2039 "Invalid" 2038 "Invalid" 2037 "Invalid" 2036 "Invalid" 2035 "Invalid" 2034 "Invalid" 2033 "Invalid" 2032 "Invalid" 2031 "Invalid" 2030 "Invalid" 2029 "Invalid" 2028 "Invalid" 2027 "Invalid" 2026 "Invalid" 2025 "Invalid" 2024 "Invalid" 2023 "Invalid" 2022 "Invalid" 2021 "Invalid" 2020 "Invalid" 2019 "Invalid" 2018 "Invalid" 2017 "Invalid" 2016 "Invalid" 2015 "Invalid" 2014 "Invalid" 2013 "Invalid" 2012 "Invalid" 2011 "Invalid" 2010 "Invalid" 2009 "Invalid" 2008 "Invalid" 2007 "Invalid" 2006 "Invalid" 2005 "Invalid" 2004 "Invalid" 2003 "Invalid" 2002 "Invalid" 2001 "Invalid" 2000 "Invalid" 1999 "Invalid" 1998 "Invalid" 1997 "Invalid" 1996 "Invalid" 1995 "Invalid" 1994 "Invalid" 1993 "Invalid" 1992 "Invalid" 1991 "Invalid" 1990 "Invalid" 1989 "Invalid" 1988 "Invalid" 1987 "Invalid" 1986 "Invalid" 1985 "Invalid" 1984 "Invalid" 1983 "Invalid" 1982 "Invalid" 1981 "Invalid" 1980 "Invalid" 1979 "Invalid" 1978 "Invalid" 1977 "Invalid" 1976 "Invalid" 1975 "Invalid" 1974 "Invalid" 1973 "Invalid" 1972 "Invalid" 1971 "Invalid" 1970 "Invalid" 1969 "Invalid" 1968 "Invalid" 1967 "Invalid" 1966 "Invalid" 1965 "Invalid" 1964 "Invalid" 1963 "Invalid" 1962 "Invalid" 1961 "Invalid" 1960 "Invalid" 1959 "Invalid" 1958 "Invalid" 1957 "Invalid" 1956 "Invalid" 1955 "Invalid" 1954 "Invalid" 1953 "Invalid" 1952 "Invalid" 1951 "Invalid" 1950 "Invalid" 1949 "Invalid" 1948 "Invalid" 1947 "Invalid" 1946 "Invalid" 1945 "Invalid" 1944 "Invalid" 1943 "Invalid" 1942 "Invalid" 1941 "Invalid" 1940 "Invalid" 1939 "Invalid" 1938 "Invalid" 1937 "Invalid" 1936 "Invalid" 1935 "Invalid" 1934 "Invalid" 1933 "Invalid" 1932 "Invalid" 1931 "Invalid" 1930 "Invalid" 1929 "Invalid" 1928 "Invalid" 1927 "Invalid" 1926 "Invalid" 1925 "Invalid" 1924 "Invalid" 1923 "Invalid" 1922 "Invalid" 1921 "Invalid" 1920 "Invalid" 1919 "Invalid" 1918 "Invalid" 1917 "Invalid" 1916 "Invalid" 1915 "Invalid" 1914 "Invalid" 1913 "Invalid" 1912 "Invalid" 1911 "Invalid" 1910 "Invalid" 1909 "Invalid" 1908 "Invalid" 1907 "Invalid" 1906 "Invalid" 1905 "Invalid" 1904 "Invalid" 1903 "Invalid" 1902 "Invalid" 1901 "Invalid" 1900 "Invalid" 1899 "Invalid" 1898 "Invalid" 1897 "Invalid" 1896 "Invalid" 1895 "Invalid" 1894 "Invalid" 1893 "Invalid" 1892 "Invalid" 1891 "Invalid" 1890 "Invalid" 1889 "Invalid" 1888 "Invalid" 1887 "Invalid" 1886 "Invalid" 1885 "Invalid" 1884 "Invalid" 1883 "Invalid" 1882 "Invalid" 1881 "Invalid" 1880 "Invalid" 1879 "Invalid" 1878 "Invalid" 1877 "Invalid" 1876 "Invalid" 1875 "Invalid" 1874 "Invalid" 1873 "Invalid" 1872 "Invalid" 1871 "Invalid" 1870 "Invalid" 1869 "Invalid" 1868 "Invalid" 1867 "Invalid" 1866 "Invalid" 1865 "Invalid" 1864 "Invalid" 1863 "Invalid" 1862 "Invalid" 1861 "Invalid" 1860 "Invalid" 1859 "Invalid" 1858 "Invalid" 1857 "Invalid" 1856 "Invalid" 1855 "Invalid" 1854 "Invalid" 1853 "Invalid" 1852 "Invalid" 1851 "Invalid" 1850 "Invalid" 1849 "Invalid" 1848 "Invalid" 1847 "Invalid" 1846 "Invalid" 1845 "Invalid" 1844 "Invalid" 1843 "Invalid" 1842 "Invalid" 1841 "Invalid" 1840 "Invalid" 1839 "Invalid" 1838 "Invalid" 1837 "Invalid" 1836 "Invalid" 1835 "Invalid" 1834 "Invalid" 1833 "Invalid" 1832 "Invalid" 1831 "Invalid" 1830 "Invalid" 1829 "Invalid" 1828 "Invalid" 1827 "Invalid" 1826 "Invalid" 1825 "Invalid" 1824 "Invalid" 1823 "Invalid" 1822 "Invalid" 1821 "Invalid" 1820 "Invalid" 1819 "Invalid" 1818 "Invalid" 1817 "Invalid" 1816 "Invalid" 1815 "Invalid" 1814 "Invalid" 1813 "Invalid" 1812 "Invalid" 1811 "Invalid" 1810 "Invalid" 1809 "Invalid" 1808 "Invalid" 1807 "Invalid" 1806 "Invalid" 1805 "Invalid" 1804 "Invalid" 1803 "Invalid" 1802 "Invalid" 1801 "Invalid" ;
VAL_ 1060 BCU_CellVlt088_RM 2047 "Invalid" 2046 "Invalid" 2045 "Invalid" 2044 "Invalid" 2043 "Invalid" 2042 "Invalid" 2041 "Invalid" 2040 "Invalid" 2039 "Invalid" 2038 "Invalid" 2037 "Invalid" 2036 "Invalid" 2035 "Invalid" 2034 "Invalid" 2033 "Invalid" 2032 "Invalid" 2031 "Invalid" 2030 "Invalid" 2029 "Invalid" 2028 "Invalid" 2027 "Invalid" 2026 "Invalid" 2025 "Invalid" 2024 "Invalid" 2023 "Invalid" 2022 "Invalid" 2021 "Invalid" 2020 "Invalid" 2019 "Invalid" 2018 "Invalid" 2017 "Invalid" 2016 "Invalid" 2015 "Invalid" 2014 "Invalid" 2013 "Invalid" 2012 "Invalid" 2011 "Invalid" 2010 "Invalid" 2009 "Invalid" 2008 "Invalid" 2007 "Invalid" 2006 "Invalid" 2005 "Invalid" 2004 "Invalid" 2003 "Invalid" 2002 "Invalid" 2001 "Invalid" 2000 "Invalid" 1999 "Invalid" 1998 "Invalid" 1997 "Invalid" 1996 "Invalid" 1995 "Invalid" 1994 "Invalid" 1993 "Invalid" 1992 "Invalid" 1991 "Invalid" 1990 "Invalid" 1989 "Invalid" 1988 "Invalid" 1987 "Invalid" 1986 "Invalid" 1985 "Invalid" 1984 "Invalid" 1983 "Invalid" 1982 "Invalid" 1981 "Invalid" 1980 "Invalid" 1979 "Invalid" 1978 "Invalid" 1977 "Invalid" 1976 "Invalid" 1975 "Invalid" 1974 "Invalid" 1973 "Invalid" 1972 "Invalid" 1971 "Invalid" 1970 "Invalid" 1969 "Invalid" 1968 "Invalid" 1967 "Invalid" 1966 "Invalid" 1965 "Invalid" 1964 "Invalid" 1963 "Invalid" 1962 "Invalid" 1961 "Invalid" 1960 "Invalid" 1959 "Invalid" 1958 "Invalid" 1957 "Invalid" 1956 "Invalid" 1955 "Invalid" 1954 "Invalid" 1953 "Invalid" 1952 "Invalid" 1951 "Invalid" 1950 "Invalid" 1949 "Invalid" 1948 "Invalid" 1947 "Invalid" 1946 "Invalid" 1945 "Invalid" 1944 "Invalid" 1943 "Invalid" 1942 "Invalid" 1941 "Invalid" 1940 "Invalid" 1939 "Invalid" 1938 "Invalid" 1937 "Invalid" 1936 "Invalid" 1935 "Invalid" 1934 "Invalid" 1933 "Invalid" 1932 "Invalid" 1931 "Invalid" 1930 "Invalid" 1929 "Invalid" 1928 "Invalid" 1927 "Invalid" 1926 "Invalid" 1925 "Invalid" 1924 "Invalid" 1923 "Invalid" 1922 "Invalid" 1921 "Invalid" 1920 "Invalid" 1919 "Invalid" 1918 "Invalid" 1917 "Invalid" 1916 "Invalid" 1915 "Invalid" 1914 "Invalid" 1913 "Invalid" 1912 "Invalid" 1911 "Invalid" 1910 "Invalid" 1909 "Invalid" 1908 "Invalid" 1907 "Invalid" 1906 "Invalid" 1905 "Invalid" 1904 "Invalid" 1903 "Invalid" 1902 "Invalid" 1901 "Invalid" 1900 "Invalid" 1899 "Invalid" 1898 "Invalid" 1897 "Invalid" 1896 "Invalid" 1895 "Invalid" 1894 "Invalid" 1893 "Invalid" 1892 "Invalid" 1891 "Invalid" 1890 "Invalid" 1889 "Invalid" 1888 "Invalid" 1887 "Invalid" 1886 "Invalid" 1885 "Invalid" 1884 "Invalid" 1883 "Invalid" 1882 "Invalid" 1881 "Invalid" 1880 "Invalid" 1879 "Invalid" 1878 "Invalid" 1877 "Invalid" 1876 "Invalid" 1875 "Invalid" 1874 "Invalid" 1873 "Invalid" 1872 "Invalid" 1871 "Invalid" 1870 "Invalid" 1869 "Invalid" 1868 "Invalid" 1867 "Invalid" 1866 "Invalid" 1865 "Invalid" 1864 "Invalid" 1863 "Invalid" 1862 "Invalid" 1861 "Invalid" 1860 "Invalid" 1859 "Invalid" 1858 "Invalid" 1857 "Invalid" 1856 "Invalid" 1855 "Invalid" 1854 "Invalid" 1853 "Invalid" 1852 "Invalid" 1851 "Invalid" 1850 "Invalid" 1849 "Invalid" 1848 "Invalid" 1847 "Invalid" 1846 "Invalid" 1845 "Invalid" 1844 "Invalid" 1843 "Invalid" 1842 "Invalid" 1841 "Invalid" 1840 "Invalid" 1839 "Invalid" 1838 "Invalid" 1837 "Invalid" 1836 "Invalid" 1835 "Invalid" 1834 "Invalid" 1833 "Invalid" 1832 "Invalid" 1831 "Invalid" 1830 "Invalid" 1829 "Invalid" 1828 "Invalid" 1827 "Invalid" 1826 "Invalid" 1825 "Invalid" 1824 "Invalid" 1823 "Invalid" 1822 "Invalid" 1821 "Invalid" 1820 "Invalid" 1819 "Invalid" 1818 "Invalid" 1817 "Invalid" 1816 "Invalid" 1815 "Invalid" 1814 "Invalid" 1813 "Invalid" 1812 "Invalid" 1811 "Invalid" 1810 "Invalid" 1809 "Invalid" 1808 "Invalid" 1807 "Invalid" 1806 "Invalid" 1805 "Invalid" 1804 "Invalid" 1803 "Invalid" 1802 "Invalid" 1801 "Invalid" ;
VAL_ 1060 BCU_CellVlt089_RM 2047 "Invalid" 2046 "Invalid" 2045 "Invalid" 2044 "Invalid" 2043 "Invalid" 2042 "Invalid" 2041 "Invalid" 2040 "Invalid" 2039 "Invalid" 2038 "Invalid" 2037 "Invalid" 2036 "Invalid" 2035 "Invalid" 2034 "Invalid" 2033 "Invalid" 2032 "Invalid" 2031 "Invalid" 2030 "Invalid" 2029 "Invalid" 2028 "Invalid" 2027 "Invalid" 2026 "Invalid" 2025 "Invalid" 2024 "Invalid" 2023 "Invalid" 2022 "Invalid" 2021 "Invalid" 2020 "Invalid" 2019 "Invalid" 2018 "Invalid" 2017 "Invalid" 2016 "Invalid" 2015 "Invalid" 2014 "Invalid" 2013 "Invalid" 2012 "Invalid" 2011 "Invalid" 2010 "Invalid" 2009 "Invalid" 2008 "Invalid" 2007 "Invalid" 2006 "Invalid" 2005 "Invalid" 2004 "Invalid" 2003 "Invalid" 2002 "Invalid" 2001 "Invalid" 2000 "Invalid" 1999 "Invalid" 1998 "Invalid" 1997 "Invalid" 1996 "Invalid" 1995 "Invalid" 1994 "Invalid" 1993 "Invalid" 1992 "Invalid" 1991 "Invalid" 1990 "Invalid" 1989 "Invalid" 1988 "Invalid" 1987 "Invalid" 1986 "Invalid" 1985 "Invalid" 1984 "Invalid" 1983 "Invalid" 1982 "Invalid" 1981 "Invalid" 1980 "Invalid" 1979 "Invalid" 1978 "Invalid" 1977 "Invalid" 1976 "Invalid" 1975 "Invalid" 1974 "Invalid" 1973 "Invalid" 1972 "Invalid" 1971 "Invalid" 1970 "Invalid" 1969 "Invalid" 1968 "Invalid" 1967 "Invalid" 1966 "Invalid" 1965 "Invalid" 1964 "Invalid" 1963 "Invalid" 1962 "Invalid" 1961 "Invalid" 1960 "Invalid" 1959 "Invalid" 1958 "Invalid" 1957 "Invalid" 1956 "Invalid" 1955 "Invalid" 1954 "Invalid" 1953 "Invalid" 1952 "Invalid" 1951 "Invalid" 1950 "Invalid" 1949 "Invalid" 1948 "Invalid" 1947 "Invalid" 1946 "Invalid" 1945 "Invalid" 1944 "Invalid" 1943 "Invalid" 1942 "Invalid" 1941 "Invalid" 1940 "Invalid" 1939 "Invalid" 1938 "Invalid" 1937 "Invalid" 1936 "Invalid" 1935 "Invalid" 1934 "Invalid" 1933 "Invalid" 1932 "Invalid" 1931 "Invalid" 1930 "Invalid" 1929 "Invalid" 1928 "Invalid" 1927 "Invalid" 1926 "Invalid" 1925 "Invalid" 1924 "Invalid" 1923 "Invalid" 1922 "Invalid" 1921 "Invalid" 1920 "Invalid" 1919 "Invalid" 1918 "Invalid" 1917 "Invalid" 1916 "Invalid" 1915 "Invalid" 1914 "Invalid" 1913 "Invalid" 1912 "Invalid" 1911 "Invalid" 1910 "Invalid" 1909 "Invalid" 1908 "Invalid" 1907 "Invalid" 1906 "Invalid" 1905 "Invalid" 1904 "Invalid" 1903 "Invalid" 1902 "Invalid" 1901 "Invalid" 1900 "Invalid" 1899 "Invalid" 1898 "Invalid" 1897 "Invalid" 1896 "Invalid" 1895 "Invalid" 1894 "Invalid" 1893 "Invalid" 1892 "Invalid" 1891 "Invalid" 1890 "Invalid" 1889 "Invalid" 1888 "Invalid" 1887 "Invalid" 1886 "Invalid" 1885 "Invalid" 1884 "Invalid" 1883 "Invalid" 1882 "Invalid" 1881 "Invalid" 1880 "Invalid" 1879 "Invalid" 1878 "Invalid" 1877 "Invalid" 1876 "Invalid" 1875 "Invalid" 1874 "Invalid" 1873 "Invalid" 1872 "Invalid" 1871 "Invalid" 1870 "Invalid" 1869 "Invalid" 1868 "Invalid" 1867 "Invalid" 1866 "Invalid" 1865 "Invalid" 1864 "Invalid" 1863 "Invalid" 1862 "Invalid" 1861 "Invalid" 1860 "Invalid" 1859 "Invalid" 1858 "Invalid" 1857 "Invalid" 1856 "Invalid" 1855 "Invalid" 1854 "Invalid" 1853 "Invalid" 1852 "Invalid" 1851 "Invalid" 1850 "Invalid" 1849 "Invalid" 1848 "Invalid" 1847 "Invalid" 1846 "Invalid" 1845 "Invalid" 1844 "Invalid" 1843 "Invalid" 1842 "Invalid" 1841 "Invalid" 1840 "Invalid" 1839 "Invalid" 1838 "Invalid" 1837 "Invalid" 1836 "Invalid" 1835 "Invalid" 1834 "Invalid" 1833 "Invalid" 1832 "Invalid" 1831 "Invalid" 1830 "Invalid" 1829 "Invalid" 1828 "Invalid" 1827 "Invalid" 1826 "Invalid" 1825 "Invalid" 1824 "Invalid" 1823 "Invalid" 1822 "Invalid" 1821 "Invalid" 1820 "Invalid" 1819 "Invalid" 1818 "Invalid" 1817 "Invalid" 1816 "Invalid" 1815 "Invalid" 1814 "Invalid" 1813 "Invalid" 1812 "Invalid" 1811 "Invalid" 1810 "Invalid" 1809 "Invalid" 1808 "Invalid" 1807 "Invalid" 1806 "Invalid" 1805 "Invalid" 1804 "Invalid" 1803 "Invalid" 1802 "Invalid" 1801 "Invalid" ;
VAL_ 1060 BCU_CellVlt090_RM 2047 "Invalid" 2046 "Invalid" 2045 "Invalid" 2044 "Invalid" 2043 "Invalid" 2042 "Invalid" 2041 "Invalid" 2040 "Invalid" 2039 "Invalid" 2038 "Invalid" 2037 "Invalid" 2036 "Invalid" 2035 "Invalid" 2034 "Invalid" 2033 "Invalid" 2032 "Invalid" 2031 "Invalid" 2030 "Invalid" 2029 "Invalid" 2028 "Invalid" 2027 "Invalid" 2026 "Invalid" 2025 "Invalid" 2024 "Invalid" 2023 "Invalid" 2022 "Invalid" 2021 "Invalid" 2020 "Invalid" 2019 "Invalid" 2018 "Invalid" 2017 "Invalid" 2016 "Invalid" 2015 "Invalid" 2014 "Invalid" 2013 "Invalid" 2012 "Invalid" 2011 "Invalid" 2010 "Invalid" 2009 "Invalid" 2008 "Invalid" 2007 "Invalid" 2006 "Invalid" 2005 "Invalid" 2004 "Invalid" 2003 "Invalid" 2002 "Invalid" 2001 "Invalid" 2000 "Invalid" 1999 "Invalid" 1998 "Invalid" 1997 "Invalid" 1996 "Invalid" 1995 "Invalid" 1994 "Invalid" 1993 "Invalid" 1992 "Invalid" 1991 "Invalid" 1990 "Invalid" 1989 "Invalid" 1988 "Invalid" 1987 "Invalid" 1986 "Invalid" 1985 "Invalid" 1984 "Invalid" 1983 "Invalid" 1982 "Invalid" 1981 "Invalid" 1980 "Invalid" 1979 "Invalid" 1978 "Invalid" 1977 "Invalid" 1976 "Invalid" 1975 "Invalid" 1974 "Invalid" 1973 "Invalid" 1972 "Invalid" 1971 "Invalid" 1970 "Invalid" 1969 "Invalid" 1968 "Invalid" 1967 "Invalid" 1966 "Invalid" 1965 "Invalid" 1964 "Invalid" 1963 "Invalid" 1962 "Invalid" 1961 "Invalid" 1960 "Invalid" 1959 "Invalid" 1958 "Invalid" 1957 "Invalid" 1956 "Invalid" 1955 "Invalid" 1954 "Invalid" 1953 "Invalid" 1952 "Invalid" 1951 "Invalid" 1950 "Invalid" 1949 "Invalid" 1948 "Invalid" 1947 "Invalid" 1946 "Invalid" 1945 "Invalid" 1944 "Invalid" 1943 "Invalid" 1942 "Invalid" 1941 "Invalid" 1940 "Invalid" 1939 "Invalid" 1938 "Invalid" 1937 "Invalid" 1936 "Invalid" 1935 "Invalid" 1934 "Invalid" 1933 "Invalid" 1932 "Invalid" 1931 "Invalid" 1930 "Invalid" 1929 "Invalid" 1928 "Invalid" 1927 "Invalid" 1926 "Invalid" 1925 "Invalid" 1924 "Invalid" 1923 "Invalid" 1922 "Invalid" 1921 "Invalid" 1920 "Invalid" 1919 "Invalid" 1918 "Invalid" 1917 "Invalid" 1916 "Invalid" 1915 "Invalid" 1914 "Invalid" 1913 "Invalid" 1912 "Invalid" 1911 "Invalid" 1910 "Invalid" 1909 "Invalid" 1908 "Invalid" 1907 "Invalid" 1906 "Invalid" 1905 "Invalid" 1904 "Invalid" 1903 "Invalid" 1902 "Invalid" 1901 "Invalid" 1900 "Invalid" 1899 "Invalid" 1898 "Invalid" 1897 "Invalid" 1896 "Invalid" 1895 "Invalid" 1894 "Invalid" 1893 "Invalid" 1892 "Invalid" 1891 "Invalid" 1890 "Invalid" 1889 "Invalid" 1888 "Invalid" 1887 "Invalid" 1886 "Invalid" 1885 "Invalid" 1884 "Invalid" 1883 "Invalid" 1882 "Invalid" 1881 "Invalid" 1880 "Invalid" 1879 "Invalid" 1878 "Invalid" 1877 "Invalid" 1876 "Invalid" 1875 "Invalid" 1874 "Invalid" 1873 "Invalid" 1872 "Invalid" 1871 "Invalid" 1870 "Invalid" 1869 "Invalid" 1868 "Invalid" 1867 "Invalid" 1866 "Invalid" 1865 "Invalid" 1864 "Invalid" 1863 "Invalid" 1862 "Invalid" 1861 "Invalid" 1860 "Invalid" 1859 "Invalid" 1858 "Invalid" 1857 "Invalid" 1856 "Invalid" 1855 "Invalid" 1854 "Invalid" 1853 "Invalid" 1852 "Invalid" 1851 "Invalid" 1850 "Invalid" 1849 "Invalid" 1848 "Invalid" 1847 "Invalid" 1846 "Invalid" 1845 "Invalid" 1844 "Invalid" 1843 "Invalid" 1842 "Invalid" 1841 "Invalid" 1840 "Invalid" 1839 "Invalid" 1838 "Invalid" 1837 "Invalid" 1836 "Invalid" 1835 "Invalid" 1834 "Invalid" 1833 "Invalid" 1832 "Invalid" 1831 "Invalid" 1830 "Invalid" 1829 "Invalid" 1828 "Invalid" 1827 "Invalid" 1826 "Invalid" 1825 "Invalid" 1824 "Invalid" 1823 "Invalid" 1822 "Invalid" 1821 "Invalid" 1820 "Invalid" 1819 "Invalid" 1818 "Invalid" 1817 "Invalid" 1816 "Invalid" 1815 "Invalid" 1814 "Invalid" 1813 "Invalid" 1812 "Invalid" 1811 "Invalid" 1810 "Invalid" 1809 "Invalid" 1808 "Invalid" 1807 "Invalid" 1806 "Invalid" 1805 "Invalid" 1804 "Invalid" 1803 "Invalid" 1802 "Invalid" 1801 "Invalid" ;
VAL_ 1060 BCU_CellTmp018_RM 255 "Invalid" 254 "Invalid" 253 "Invalid" 252 "Invalid" 251 "Invalid" 250 "Invalid" 249 "Invalid" 248 "Invalid" 247 "Invalid" 246 "Invalid" 245 "Invalid" 244 "Invalid" 243 "Invalid" 242 "Invalid" 241 "Invalid" 240 "Invalid" 239 "Invalid" 238 "Invalid" 237 "Invalid" 236 "Invalid" 235 "Invalid" 234 "Invalid" 233 "Invalid" 232 "Invalid" 231 "Invalid" 230 "Invalid" 229 "Invalid" 228 "Invalid" 227 "Invalid" 226 "Invalid" 225 "Invalid" 224 "Invalid" 223 "Invalid" 222 "Invalid" 221 "Invalid" 220 "Invalid" 219 "Invalid" 218 "Invalid" 217 "Invalid" 216 "Invalid" 215 "Invalid" 214 "Invalid" 213 "Invalid" 212 "Invalid" 211 "Invalid" 210 "Invalid" 209 "Invalid" 208 "Invalid" 207 "Invalid" 206 "Invalid" 205 "Invalid" 204 "Invalid" 203 "Invalid" 202 "Invalid" 201 "Invalid" 200 "Invalid" 199 "Invalid" 198 "Invalid" 197 "Invalid" 196 "Invalid" 195 "Invalid" 194 "Invalid" 193 "Invalid" 192 "Invalid" 191 "Invalid" 190 "Invalid" 189 "Invalid" 188 "Invalid" 187 "Invalid" 186 "Invalid" 185 "Invalid" 184 "Invalid" 183 "Invalid" 182 "Invalid" 181 "Invalid" 180 "Invalid" 179 "Invalid" 178 "Invalid" 177 "Invalid" 176 "Invalid" 175 "Invalid" 174 "Invalid" 173 "Invalid" 172 "Invalid" 171 "Invalid" 170 "Invalid" 169 "Invalid" 168 "Invalid" 167 "Invalid" 166 "Invalid" 165 "Invalid" 164 "Invalid" 163 "Invalid" 162 "Invalid" 161 "Invalid" ;
